VERSION ""

NS_ :

BS_:

BU_:

BO_ 2558394110 EAMC: 8 Vector__XXX
 SG_ EltrfdAssrMtrEnlCmmnd : 0|2@1+ (1,0) [0|3] "" Vector__XXX
 SG_ EltrfdAssrMtrPrntSpdCmmnd : 24|8@1+ (0.5,0) [0|125] "%" Vector__XXX
 SG_ EltrfdAssrMtrPwrHld : 2|2@1+ (1,0) [0|3] "" Vector__XXX
 SG_ EltrfdAssrMtrSpdCmmnd : 8|16@1+ (0.5,0) [0|32127.5] "rpm" Vector__XXX
 SG_ ElectrifiedAccessoryMotor1 : 32|1@1+ (1,0) [0|1] "" Vector__XXX
 SG_ ElectrifiedAccessoryMotor2 : 33|1@1+ (1,0) [0|1] "" Vector__XXX
 SG_ ElectrifiedAccessoryMotor3 : 34|1@1+ (1,0) [0|1] "" Vector__XXX
 SG_ ElectrifiedAccessoryMotor4 : 35|1@1+ (1,0) [0|1] "" Vector__XXX
 SG_ ElectrifiedAccessoryMotor5 : 36|1@1+ (1,0) [0|1] "" Vector__XXX
 SG_ ElectrifiedAccessoryMotor6 : 37|1@1+ (1,0) [0|1] "" Vector__XXX
 SG_ ElectrifiedAccessoryMotor7 : 38|1@1+ (1,0) [0|1] "" Vector__XXX
 SG_ ElectrifiedAccessoryMotor8 : 39|1@1+ (1,0) [0|1] "" Vector__XXX
 SG_ ElectrifiedAccessoryMotor9 : 40|1@1+ (1,0) [0|1] "" Vector__XXX
 SG_ ElectrifiedAccessoryMotor10 : 41|1@1+ (1,0) [0|1] "" Vector__XXX
 SG_ ElectrifiedAccessoryMotor11 : 42|1@1+ (1,0) [0|1] "" Vector__XXX
 SG_ ElectrifiedAccessoryMotor12 : 43|1@1+ (1,0) [0|1] "" Vector__XXX
 SG_ ElectrifiedAccessoryMotor13 : 44|1@1+ (1,0) [0|1] "" Vector__XXX
 SG_ ElectrifiedAccessoryMotor14 : 45|1@1+ (1,0) [0|1] "" Vector__XXX
 SG_ ElectrifiedAccessoryMotor15 : 46|1@1+ (1,0) [0|1] "" Vector__XXX

BO_ 2558459646 ESRRBR: 8 Vector__XXX
 SG_ RqstdEngnSpdAlrtnRtLmt : 0|16@1+ (1,0) [0|64255] "rpm/s" Vector__XXX
 SG_ RqstdEngnSpdDlrtnRtLmt : 16|16@1+ (1,0) [0|64255] "rpm/s" Vector__XXX

BO_ 2558525182 TSIC: 200 Vector__XXX
 SG_ NumberofTireSensors : 0|8@1+ (1,0) [0|250] "count" Vector__XXX
 SG_ TireLocation : 16|8@1+ (8,0) [0|0] "bit-mapped" Vector__XXX
 SG_ TireNumber : 8|8@1+ (1,0) [0|250] "count" Vector__XXX
 SG_ TireSensorIdentificationNumber : 24|8@1+ (1,0) [0|255] "ASCII" Vector__XXX

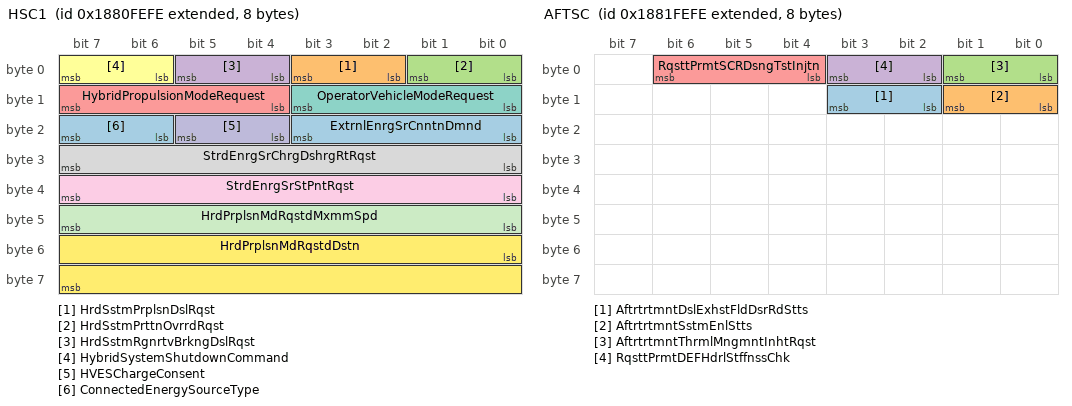
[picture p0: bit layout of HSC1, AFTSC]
BO_ 2558590718 HSC1: 8 Vector__XXX
 SG_ ExtrnlEnrgSrCnntnDmnd : 16|4@1+ (1,0) [0|15] "" Vector__XXX
 SG_ HrdSstmPrplsnDslRqst : 2|2@1+ (1,0) [0|3] "" Vector__XXX
 SG_ HrdSstmPrttnOvrrdRqst : 0|2@1+ (1,0) [0|3] "" Vector__XXX
 SG_ HrdSstmRgnrtvBrkngDslRqst : 4|2@1+ (1,0) [0|3] "" Vector__XXX
 SG_ HybridPropulsionModeRequest : 12|4@1+ (1,0) [0|15] "" Vector__XXX
 SG_ HybridSystemShutdownCommand : 6|2@1+ (1,0) [0|3] "" Vector__XXX
 SG_ OperatorVehicleModeRequest : 8|4@1+ (1,0) [0|15] "" Vector__XXX
 SG_ StrdEnrgSrChrgDshrgRtRqst : 24|8@1+ (0.4,0) [0|100] "%" Vector__XXX
 SG_ StrdEnrgSrStPntRqst : 32|8@1+ (0.4,0) [0|100] "%" Vector__XXX
 SG_ HVESChargeConsent : 20|2@1+ (1,0) [0|3] "" Vector__XXX
 SG_ HrdPrplsnMdRqstdMxmmSpd : 40|8@1+ (1,0) [0|250] "km/h" Vector__XXX
 SG_ HrdPrplsnMdRqstdDstn : 48|16@1+ (0.03125,0) [0|2007.96875] "km" Vector__XXX
 SG_ ConnectedEnergySourceType : 22|2@1+ (1,0) [0|3] "" Vector__XXX

BO_ 2558656254 AFTSC: 8 Vector__XXX
 SG_ AftrtrtmntDslExhstFldDsrRdStts : 10|2@1+ (1,0) [0|3] "" Vector__XXX
 SG_ AftrtrtmntSstmEnlStts : 8|2@1+ (1,0) [0|3] "" Vector__XXX
 SG_ AftrtrtmntThrmlMngmntInhtRqst : 0|2@1+ (1,0) [0|3] "" Vector__XXX
 SG_ RqsttPrmtDEFHdrlStffnssChk : 2|2@1+ (1,0) [0|3] "" Vector__XXX
 SG_ RqsttPrmtSCRDsngTstInjtn : 4|3@1+ (1,0) [0|7] "" Vector__XXX

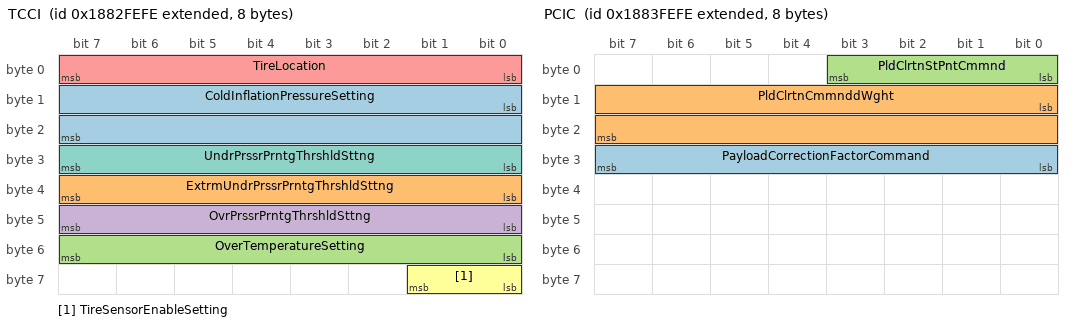
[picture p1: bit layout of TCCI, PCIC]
BO_ 2558721790 TCCI: 8 Vector__XXX
 SG_ ColdInflationPressureSetting : 8|16@1+ (1,0) [0|64255] "kPa" Vector__XXX
 SG_ ExtrmUndrPrssrPrntgThrshldSttng : 32|8@1+ (0.5,0) [0|125] "%" Vector__XXX
 SG_ OverTemperatureSetting : 48|8@1+ (1,-40) [-40|210] "degC" Vector__XXX
 SG_ OvrPrssrPrntgThrshldSttng : 40|8@1+ (0.5,0) [0|125] "%" Vector__XXX
 SG_ TireLocation : 0|8@1+ (8,0) [0|0] "bit-mapped" Vector__XXX
 SG_ TireSensorEnableSetting : 56|2@1+ (1,0) [0|3] "" Vector__XXX
 SG_ UndrPrssrPrntgThrshldSttng : 24|8@1+ (0.5,0) [0|125] "%" Vector__XXX

BO_ 2558787326 PCIC: 8 Vector__XXX
 SG_ PayloadCorrectionFactorCommand : 24|8@1+ (1,-125) [-125|125] "%" Vector__XXX
 SG_ PldClrtnCmmnddWght : 8|16@1+ (2,0) [0|128510] "kg" Vector__XXX
 SG_ PldClrtnStPntCmmnd : 0|4@1+ (1,0) [0|15] "" Vector__XXX

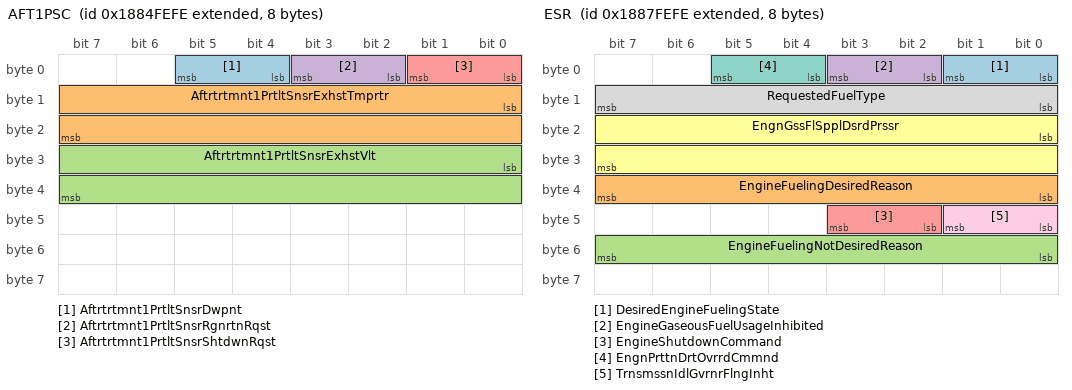
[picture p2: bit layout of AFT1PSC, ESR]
BO_ 2558852862 AFT1PSC: 8 Vector__XXX
 SG_ Aftrtrtmnt1PrtltSnsrDwpnt : 4|2@1+ (1,0) [0|3] "" Vector__XXX
 SG_ Aftrtrtmnt1PrtltSnsrExhstTmprtr : 8|16@1+ (0.03125,-273) [-273|1734.96875] "degC" Vector__XXX
 SG_ Aftrtrtmnt1PrtltSnsrExhstVlt : 24|16@1+ (0.00390625,0) [0|250.996] "km/h" Vector__XXX
 SG_ Aftrtrtmnt1PrtltSnsrRgnrtnRqst : 2|2@1+ (1,0) [0|3] "" Vector__XXX
 SG_ Aftrtrtmnt1PrtltSnsrShtdwnRqst : 0|2@1+ (1,0) [0|3] "" Vector__XXX

BO_ 2558918398 CM2: 8 Vector__XXX
 SG_ ActiveShiftConsoleRequest : 52|2@1+ (1,0) [0|3] "" Vector__XXX
 SG_ AftrtrtmntSstmEnlCmmnd : 50|2@1+ (1,0) [0|3] "" Vector__XXX
 SG_ AttttRtESpdAwdSwt : 30|2@1+ (1,0) [0|3] "" Vector__XXX
 SG_ ElvtdEngnSpdAllwdSwth : 28|2@1+ (1,0) [0|3] "" Vector__XXX
 SG_ EngineFan2RequestedPercentSpeed : 0|8@1+ (0.4,0) [0|100] "%" Vector__XXX
 SG_ EngineStopStartDisableCommand : 26|2@1+ (1,0) [0|3] "" Vector__XXX
 SG_ EngnIdlMngmntPndngEvntOvrrd : 54|2@1+ (1,0) [0|3] "" Vector__XXX
 SG_ HtExhngrDrsPrgFrSwth : 20|2@1+ (1,0) [0|3] "" Vector__XXX
 SG_ HtExhngrDrsPrgInhtSwth : 18|2@1+ (1,0) [0|3] "" Vector__XXX
 SG_ PerformanceBiasSelection : 8|8@1+ (0.4,0) [0|100] "%" Vector__XXX
 SG_ PrdtvCrsCntrlDtvtnRqst : 24|2@1+ (1,0) [0|3] "" Vector__XXX
 SG_ PrdtvCrsCntrlEnlSwth : 22|2@1+ (1,0) [0|3] "" Vector__XXX
 SG_ PrdtvCrsCntrlMxmmNgtvOffst : 40|8@1+ (0.125,-31.25) [-31.25|0] "km/h" Vector__XXX
 SG_ PrdtvCrsCntrlMxmmPstvOffst : 32|8@1+ (0.125,0) [0|31.25] "km/h" Vector__XXX
 SG_ SCROprtrIndmntOvrrdSwth : 16|2@1+ (1,0) [0|3] "" Vector__XXX
 SG_ TrnsmssnAtNtrlMnlRtrnEnlSwth : 48|2@1+ (1,0) [0|3] "" Vector__XXX
 SG_ VehicleHoodSwitch : 56|2@1+ (1,0) [0|3] "" Vector__XXX

BO_ 2558983934 SPOC: 8 Vector__XXX
 SG_ SwitchedPowerOutput10Command : 20|2@1+ (1,0) [0|3] "" Vector__XXX
 SG_ SwitchedPowerOutput11Command : 18|2@1+ (1,0) [0|3] "" Vector__XXX
 SG_ SwitchedPowerOutput12Command : 16|2@1+ (1,0) [0|3] "" Vector__XXX
 SG_ SwitchedPowerOutput13Command : 30|2@1+ (1,0) [0|3] "" Vector__XXX
 SG_ SwitchedPowerOutput14Command : 28|2@1+ (1,0) [0|3] "" Vector__XXX
 SG_ SwitchedPowerOutput15Command : 26|2@1+ (1,0) [0|3] "" Vector__XXX
 SG_ SwitchedPowerOutput16Command : 24|2@1+ (1,0) [0|3] "" Vector__XXX
 SG_ SwitchedPowerOutput17Command : 38|2@1+ (1,0) [0|3] "" Vector__XXX
 SG_ SwitchedPowerOutput18Command : 36|2@1+ (1,0) [0|3] "" Vector__XXX
 SG_ SwitchedPowerOutput19Command : 34|2@1+ (1,0) [0|3] "" Vector__XXX
 SG_ SwitchedPowerOutput1Command : 6|2@1+ (1,0) [0|3] "" Vector__XXX
 SG_ SwitchedPowerOutput20Command : 32|2@1+ (1,0) [0|3] "" Vector__XXX
 SG_ SwitchedPowerOutput21Command : 46|2@1+ (1,0) [0|3] "" Vector__XXX
 SG_ SwitchedPowerOutput22Command : 44|2@1+ (1,0) [0|3] "" Vector__XXX
 SG_ SwitchedPowerOutput23Command : 42|2@1+ (1,0) [0|3] "" Vector__XXX
 SG_ SwitchedPowerOutput24Command : 40|2@1+ (1,0) [0|3] "" Vector__XXX
 SG_ SwitchedPowerOutput25Command : 54|2@1+ (1,0) [0|3] "" Vector__XXX
 SG_ SwitchedPowerOutput26Command : 52|2@1+ (1,0) [0|3] "" Vector__XXX
 SG_ SwitchedPowerOutput27Command : 50|2@1+ (1,0) [0|3] "" Vector__XXX
 SG_ SwitchedPowerOutput28Command : 48|2@1+ (1,0) [0|3] "" Vector__XXX
 SG_ SwitchedPowerOutput29Command : 62|2@1+ (1,0) [0|3] "" Vector__XXX
 SG_ SwitchedPowerOutput2Command : 4|2@1+ (1,0) [0|3] "" Vector__XXX
 SG_ SwitchedPowerOutput30Command : 60|2@1+ (1,0) [0|3] "" Vector__XXX
 SG_ SwitchedPowerOutput31Command : 58|2@1+ (1,0) [0|3] "" Vector__XXX
 SG_ SwitchedPowerOutput32Command : 56|2@1+ (1,0) [0|3] "" Vector__XXX
 SG_ SwitchedPowerOutput3Command : 2|2@1+ (1,0) [0|3] "" Vector__XXX
 SG_ SwitchedPowerOutput4Command : 0|2@1+ (1,0) [0|3] "" Vector__XXX
 SG_ SwitchedPowerOutput5Command : 14|2@1+ (1,0) [0|3] "" Vector__XXX
 SG_ SwitchedPowerOutput6Command : 12|2@1+ (1,0) [0|3] "" Vector__XXX
 SG_ SwitchedPowerOutput7Command : 10|2@1+ (1,0) [0|3] "" Vector__XXX
 SG_ SwitchedPowerOutput8Command : 8|2@1+ (1,0) [0|3] "" Vector__XXX
 SG_ SwitchedPowerOutput9Command : 22|2@1+ (1,0) [0|3] "" Vector__XXX

BO_ 2559049470 ESR: 8 Vector__XXX
 SG_ DesiredEngineFuelingState : 0|2@1+ (1,0) [0|3] "" Vector__XXX
 SG_ EngineFuelingDesiredReason : 32|8@1+ (1,0) [0|255] "" Vector__XXX
 SG_ EngineFuelingNotDesiredReason : 48|8@1+ (1,0) [0|255] "" Vector__XXX
 SG_ EngineGaseousFuelUsageInhibited : 2|2@1+ (1,0) [0|3] "" Vector__XXX
 SG_ EngineShutdownCommand : 42|2@1+ (1,0) [0|3] "" Vector__XXX
 SG_ EngnGssFlSpplDsrdPrssr : 16|16@1+ (0.5,0) [0|32127.5] "kPa" Vector__XXX
 SG_ EngnPrttnDrtOvrrdCmmnd : 4|2@1+ (1,0) [0|3] "" Vector__XXX
 SG_ RequestedFuelType : 8|8@1+ (1,0) [0|255] "" Vector__XXX
 SG_ TrnsmssnIdlGvrnrFlngInht : 40|2@1+ (1,0) [0|3] "" Vector__XXX

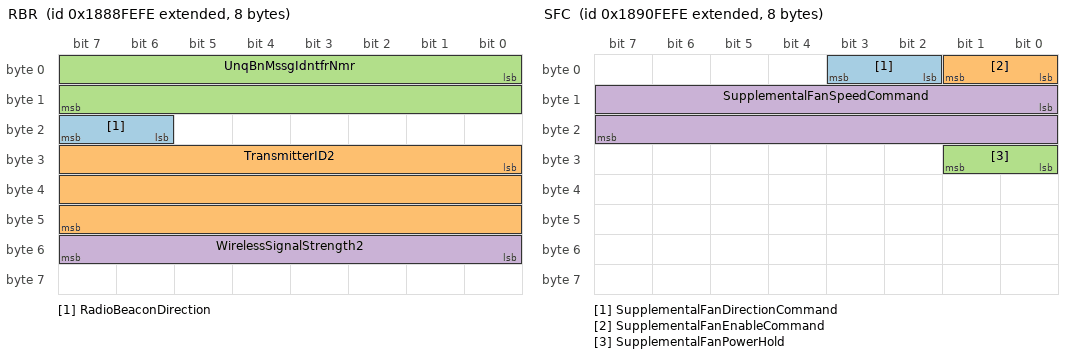
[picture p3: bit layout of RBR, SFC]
BO_ 2559115006 RBR: 8 Vector__XXX
 SG_ RadioBeaconDirection : 22|2@1+ (1,0) [0|3] "" Vector__XXX
 SG_ TransmitterID2 : 24|24@1+ (1,0) [0|16449635] "ID" Vector__XXX
 SG_ UnqBnMssgIdntfrNmr : 0|16@1+ (1,0) [0|64255] "count" Vector__XXX
 SG_ WirelessSignalStrength2 : 48|8@1+ (0.5,-125) [-125|0] "dBm" Vector__XXX

BO_ 2559573758 ECC: 8 Vector__XXX
 SG_ CtLvEPttStdwOvdCd : 0|2@1+ (1,0) [0|3] "" Vector__XXX

BO_ 2559639294 SFC: 8 Vector__XXX
 SG_ SupplementalFanDirectionCommand : 2|2@1+ (1,0) [0|3] "" Vector__XXX
 SG_ SupplementalFanEnableCommand : 0|2@1+ (1,0) [0|3] "" Vector__XXX
 SG_ SupplementalFanPowerHold : 24|2@1+ (1,0) [0|3] "" Vector__XXX
 SG_ SupplementalFanSpeedCommand : 8|16@1+ (0.5,0) [0|32127.5] "rpm" Vector__XXX

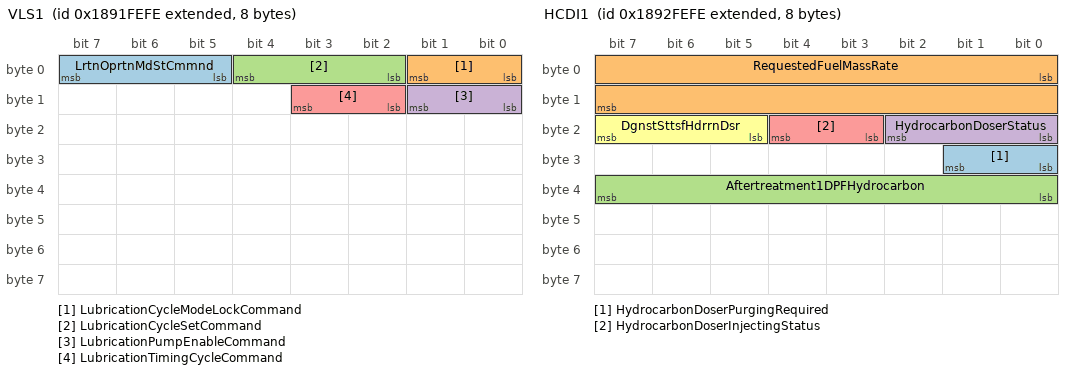
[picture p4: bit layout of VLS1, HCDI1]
BO_ 2559704830 VLS1: 8 Vector__XXX
 SG_ LrtnOprtnMdStCmmnd : 5|3@1+ (1,0) [0|7] "" Vector__XXX
 SG_ LubricationCycleModeLockCommand : 0|2@1+ (1,0) [0|3] "" Vector__XXX
 SG_ LubricationCycleSetCommand : 2|3@1+ (1,0) [0|7] "" Vector__XXX
 SG_ LubricationPumpEnableCommand : 8|2@1+ (1,0) [0|3] "" Vector__XXX
 SG_ LubricationTimingCycleCommand : 10|2@1+ (1,0) [0|3] "" Vector__XXX

BO_ 2559770366 HCDI1: 8 Vector__XXX
 SG_ HydrocarbonDoserPurgingRequired : 24|2@1+ (1,0) [0|3] "" Vector__XXX
 SG_ RequestedFuelMassRate : 0|16@1+ (0.05,0) [0|3212.75] "g/min" Vector__XXX
 SG_ Aftertreatment1DPFHydrocarbon : 32|8@1+ (0.5,0) [0|125] "%" Vector__XXX
 SG_ HydrocarbonDoserStatus : 16|3@1+ (1,0) [0|7] "" Vector__XXX
 SG_ HydrocarbonDoserInjectingStatus : 19|2@1+ (1,0) [0|3] "" Vector__XXX
 SG_ DgnstSttsfHdrrnDsr : 21|3@1+ (1,0) [0|7] "" Vector__XXX

BO_ 2559901438 AT1DPFSSC: 8 Vector__XXX
 SG_ Atttt1DsPttFtStMCtOst : 0|16@1+ (0.0025,0) [0|160.6375] "%" Vector__XXX
 SG_ Atttt1DsPttFtStStddDvtCtOst : 16|16@1+ (0.0025,0) [0|160.6375] "%" Vector__XXX

BO_ 2559966974 AT2DPFSSC: 8 Vector__XXX
 SG_ Atttt2DsPttFtStMCtOst : 0|16@1+ (0.0025,0) [0|160.6375] "%" Vector__XXX
 SG_ Atttt2DsPttFtStStddDvtCtOst : 16|16@1+ (0.0025,0) [0|160.6375] "%" Vector__XXX

BO_ 2560032510 LVDSOM: 8 Vector__XXX
 SG_ LwVltgDsnntDsrdOprtngMd : 0|4@1+ (1,0) [0|15] "" Vector__XXX

BO_ 2560098046 NCS: 8 Vector__XXX
 SG_ CabNoiseControlStatus : 0|2@1+ (1,0) [0|3] "" Vector__XXX
 SG_ CabNoiseControlTuningStatus : 2|4@1+ (1,0) [0|15] "" Vector__XXX

BO_ 2560163582 NC1: 8 Vector__XXX
 SG_ CabNoiseControlCommand : 0|2@1+ (1,0) [0|3] "" Vector__XXX
 SG_ CabNoiseControlTuningCommand : 2|3@1+ (1,0) [0|7] "" Vector__XXX

BO_ 2560360190 PMI: 8 Vector__XXX
 SG_ DataDictionaryManufacturerCode : 0|11@1+ (1,0) [0|2047] "" Vector__XXX
 SG_ DataDictionaryMethod : 11|21@1+ (1,0) [0|2097151] "" Vector__XXX

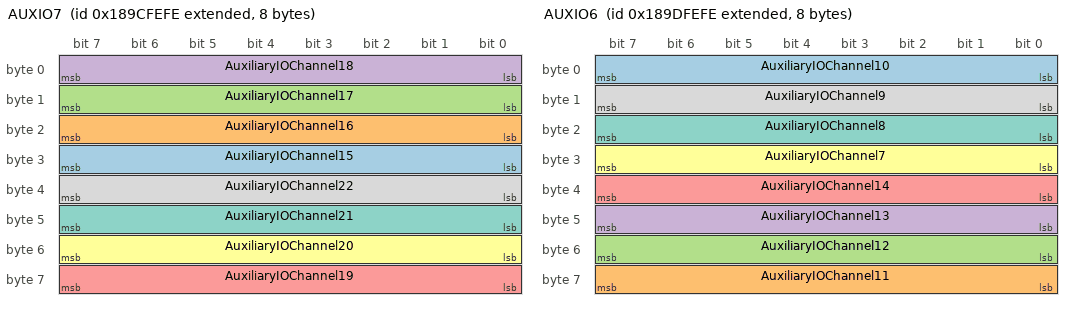
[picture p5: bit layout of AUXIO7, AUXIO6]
BO_ 2560425726 AUXIO7: 8 Vector__XXX
 SG_ AuxiliaryIOChannel15 : 24|8@1+ (1,0) [0|250] "count" Vector__XXX
 SG_ AuxiliaryIOChannel16 : 16|8@1+ (1,0) [0|250] "count" Vector__XXX
 SG_ AuxiliaryIOChannel17 : 8|8@1+ (1,0) [0|250] "count" Vector__XXX
 SG_ AuxiliaryIOChannel18 : 0|8@1+ (1,0) [0|250] "count" Vector__XXX
 SG_ AuxiliaryIOChannel19 : 56|8@1+ (1,0) [0|250] "count" Vector__XXX
 SG_ AuxiliaryIOChannel20 : 48|8@1+ (1,0) [0|250] "count" Vector__XXX
 SG_ AuxiliaryIOChannel21 : 40|8@1+ (1,0) [0|250] "count" Vector__XXX
 SG_ AuxiliaryIOChannel22 : 32|8@1+ (1,0) [0|250] "count" Vector__XXX

BO_ 2560491262 AUXIO6: 8 Vector__XXX
 SG_ AuxiliaryIOChannel10 : 0|8@1+ (1,0) [0|250] "count" Vector__XXX
 SG_ AuxiliaryIOChannel11 : 56|8@1+ (1,0) [0|250] "count" Vector__XXX
 SG_ AuxiliaryIOChannel12 : 48|8@1+ (1,0) [0|250] "count" Vector__XXX
 SG_ AuxiliaryIOChannel13 : 40|8@1+ (1,0) [0|250] "count" Vector__XXX
 SG_ AuxiliaryIOChannel14 : 32|8@1+ (1,0) [0|250] "count" Vector__XXX
 SG_ AuxiliaryIOChannel7 : 24|8@1+ (1,0) [0|250] "count" Vector__XXX
 SG_ AuxiliaryIOChannel8 : 16|8@1+ (1,0) [0|250] "count" Vector__XXX
 SG_ AuxiliaryIOChannel9 : 8|8@1+ (1,0) [0|250] "count" Vector__XXX

BO_ 2561015550 AUXIO4: 8 Vector__XXX
 SG_ AuxiliaryIO100 : 32|2@1+ (1,0) [0|3] "" Vector__XXX
 SG_ AuxiliaryIO101 : 46|2@1+ (1,0) [0|3] "" Vector__XXX
 SG_ AuxiliaryIO102 : 44|2@1+ (1,0) [0|3] "" Vector__XXX
 SG_ AuxiliaryIO103 : 42|2@1+ (1,0) [0|3] "" Vector__XXX
 SG_ AuxiliaryIO104 : 40|2@1+ (1,0) [0|3] "" Vector__XXX
 SG_ AuxiliaryIO105 : 54|2@1+ (1,0) [0|3] "" Vector__XXX
 SG_ AuxiliaryIO106 : 52|2@1+ (1,0) [0|3] "" Vector__XXX
 SG_ AuxiliaryIO107 : 50|2@1+ (1,0) [0|3] "" Vector__XXX
 SG_ AuxiliaryIO108 : 48|2@1+ (1,0) [0|3] "" Vector__XXX
 SG_ AuxiliaryIO109 : 62|2@1+ (1,0) [0|3] "" Vector__XXX
 SG_ AuxiliaryIO110 : 60|2@1+ (1,0) [0|3] "" Vector__XXX
 SG_ AuxiliaryIO111 : 58|2@1+ (1,0) [0|3] "" Vector__XXX
 SG_ AuxiliaryIO112 : 56|2@1+ (1,0) [0|3] "" Vector__XXX
 SG_ AuxiliaryIO81 : 6|2@1+ (1,0) [0|3] "" Vector__XXX
 SG_ AuxiliaryIO82 : 4|2@1+ (1,0) [0|3] "" Vector__XXX
 SG_ AuxiliaryIO83 : 2|2@1+ (1,0) [0|3] "" Vector__XXX
 SG_ AuxiliaryIO84 : 0|2@1+ (1,0) [0|3] "" Vector__XXX
 SG_ AuxiliaryIO85 : 14|2@1+ (1,0) [0|3] "" Vector__XXX
 SG_ AuxiliaryIO86 : 12|2@1+ (1,0) [0|3] "" Vector__XXX
 SG_ AuxiliaryIO87 : 10|2@1+ (1,0) [0|3] "" Vector__XXX
 SG_ AuxiliaryIO88 : 8|2@1+ (1,0) [0|3] "" Vector__XXX
 SG_ AuxiliaryIO89 : 22|2@1+ (1,0) [0|3] "" Vector__XXX
 SG_ AuxiliaryIO90 : 20|2@1+ (1,0) [0|3] "" Vector__XXX
 SG_ AuxiliaryIO91 : 18|2@1+ (1,0) [0|3] "" Vector__XXX
 SG_ AuxiliaryIO92 : 16|2@1+ (1,0) [0|3] "" Vector__XXX
 SG_ AuxiliaryIO93 : 30|2@1+ (1,0) [0|3] "" Vector__XXX
 SG_ AuxiliaryIO94 : 28|2@1+ (1,0) [0|3] "" Vector__XXX
 SG_ AuxiliaryIO95 : 26|2@1+ (1,0) [0|3] "" Vector__XXX
 SG_ AuxiliaryIO96 : 24|2@1+ (1,0) [0|3] "" Vector__XXX
 SG_ AuxiliaryIO97 : 38|2@1+ (1,0) [0|3] "" Vector__XXX
 SG_ AuxiliaryIO98 : 36|2@1+ (1,0) [0|3] "" Vector__XXX
 SG_ AuxiliaryIO99 : 34|2@1+ (1,0) [0|3] "" Vector__XXX

BO_ 2561081086 AUXIO3: 8 Vector__XXX
 SG_ AuxiliaryIO49 : 6|2@1+ (1,0) [0|3] "" Vector__XXX
 SG_ AuxiliaryIO50 : 4|2@1+ (1,0) [0|3] "" Vector__XXX
 SG_ AuxiliaryIO51 : 2|2@1+ (1,0) [0|3] "" Vector__XXX
 SG_ AuxiliaryIO52 : 0|2@1+ (1,0) [0|3] "" Vector__XXX
 SG_ AuxiliaryIO53 : 14|2@1+ (1,0) [0|3] "" Vector__XXX
 SG_ AuxiliaryIO54 : 12|2@1+ (1,0) [0|3] "" Vector__XXX
 SG_ AuxiliaryIO55 : 10|2@1+ (1,0) [0|3] "" Vector__XXX
 SG_ AuxiliaryIO56 : 8|2@1+ (1,0) [0|3] "" Vector__XXX
 SG_ AuxiliaryIO57 : 22|2@1+ (1,0) [0|3] "" Vector__XXX
 SG_ AuxiliaryIO58 : 20|2@1+ (1,0) [0|3] "" Vector__XXX
 SG_ AuxiliaryIO59 : 18|2@1+ (1,0) [0|3] "" Vector__XXX
 SG_ AuxiliaryIO60 : 16|2@1+ (1,0) [0|3] "" Vector__XXX
 SG_ AuxiliaryIO61 : 30|2@1+ (1,0) [0|3] "" Vector__XXX
 SG_ AuxiliaryIO62 : 28|2@1+ (1,0) [0|3] "" Vector__XXX
 SG_ AuxiliaryIO63 : 26|2@1+ (1,0) [0|3] "" Vector__XXX
 SG_ AuxiliaryIO64 : 24|2@1+ (1,0) [0|3] "" Vector__XXX
 SG_ AuxiliaryIO65 : 38|2@1+ (1,0) [0|3] "" Vector__XXX
 SG_ AuxiliaryIO66 : 36|2@1+ (1,0) [0|3] "" Vector__XXX
 SG_ AuxiliaryIO67 : 34|2@1+ (1,0) [0|3] "" Vector__XXX
 SG_ AuxiliaryIO68 : 32|2@1+ (1,0) [0|3] "" Vector__XXX
 SG_ AuxiliaryIO69 : 46|2@1+ (1,0) [0|3] "" Vector__XXX
 SG_ AuxiliaryIO70 : 44|2@1+ (1,0) [0|3] "" Vector__XXX
 SG_ AuxiliaryIO71 : 42|2@1+ (1,0) [0|3] "" Vector__XXX
 SG_ AuxiliaryIO72 : 40|2@1+ (1,0) [0|3] "" Vector__XXX
 SG_ AuxiliaryIO73 : 54|2@1+ (1,0) [0|3] "" Vector__XXX
 SG_ AuxiliaryIO74 : 52|2@1+ (1,0) [0|3] "" Vector__XXX
 SG_ AuxiliaryIO75 : 50|2@1+ (1,0) [0|3] "" Vector__XXX
 SG_ AuxiliaryIO76 : 48|2@1+ (1,0) [0|3] "" Vector__XXX
 SG_ AuxiliaryIO77 : 62|2@1+ (1,0) [0|3] "" Vector__XXX
 SG_ AuxiliaryIO78 : 60|2@1+ (1,0) [0|3] "" Vector__XXX
 SG_ AuxiliaryIO79 : 58|2@1+ (1,0) [0|3] "" Vector__XXX
 SG_ AuxiliaryIO80 : 56|2@1+ (1,0) [0|3] "" Vector__XXX

BO_ 2561146622 AUXIO2: 8 Vector__XXX
 SG_ AuxiliaryIO17 : 6|2@1+ (1,0) [0|3] "" Vector__XXX
 SG_ AuxiliaryIO18 : 4|2@1+ (1,0) [0|3] "" Vector__XXX
 SG_ AuxiliaryIO19 : 2|2@1+ (1,0) [0|3] "" Vector__XXX
 SG_ AuxiliaryIO20 : 0|2@1+ (1,0) [0|3] "" Vector__XXX
 SG_ AuxiliaryIO21 : 14|2@1+ (1,0) [0|3] "" Vector__XXX
 SG_ AuxiliaryIO22 : 12|2@1+ (1,0) [0|3] "" Vector__XXX
 SG_ AuxiliaryIO23 : 10|2@1+ (1,0) [0|3] "" Vector__XXX
 SG_ AuxiliaryIO24 : 8|2@1+ (1,0) [0|3] "" Vector__XXX
 SG_ AuxiliaryIO25 : 22|2@1+ (1,0) [0|3] "" Vector__XXX
 SG_ AuxiliaryIO26 : 20|2@1+ (1,0) [0|3] "" Vector__XXX
 SG_ AuxiliaryIO27 : 18|2@1+ (1,0) [0|3] "" Vector__XXX
 SG_ AuxiliaryIO28 : 16|2@1+ (1,0) [0|3] "" Vector__XXX
 SG_ AuxiliaryIO29 : 30|2@1+ (1,0) [0|3] "" Vector__XXX
 SG_ AuxiliaryIO30 : 28|2@1+ (1,0) [0|3] "" Vector__XXX
 SG_ AuxiliaryIO31 : 26|2@1+ (1,0) [0|3] "" Vector__XXX
 SG_ AuxiliaryIO32 : 24|2@1+ (1,0) [0|3] "" Vector__XXX
 SG_ AuxiliaryIO33 : 38|2@1+ (1,0) [0|3] "" Vector__XXX
 SG_ AuxiliaryIO34 : 36|2@1+ (1,0) [0|3] "" Vector__XXX
 SG_ AuxiliaryIO35 : 34|2@1+ (1,0) [0|3] "" Vector__XXX
 SG_ AuxiliaryIO36 : 32|2@1+ (1,0) [0|3] "" Vector__XXX
 SG_ AuxiliaryIO37 : 46|2@1+ (1,0) [0|3] "" Vector__XXX
 SG_ AuxiliaryIO38 : 44|2@1+ (1,0) [0|3] "" Vector__XXX
 SG_ AuxiliaryIO39 : 42|2@1+ (1,0) [0|3] "" Vector__XXX
 SG_ AuxiliaryIO40 : 40|2@1+ (1,0) [0|3] "" Vector__XXX
 SG_ AuxiliaryIO41 : 54|2@1+ (1,0) [0|3] "" Vector__XXX
 SG_ AuxiliaryIO42 : 52|2@1+ (1,0) [0|3] "" Vector__XXX
 SG_ AuxiliaryIO43 : 50|2@1+ (1,0) [0|3] "" Vector__XXX
 SG_ AuxiliaryIO44 : 48|2@1+ (1,0) [0|3] "" Vector__XXX
 SG_ AuxiliaryIO45 : 62|2@1+ (1,0) [0|3] "" Vector__XXX
 SG_ AuxiliaryIO46 : 60|2@1+ (1,0) [0|3] "" Vector__XXX
 SG_ AuxiliaryIO47 : 58|2@1+ (1,0) [0|3] "" Vector__XXX
 SG_ AuxiliaryIO48 : 56|2@1+ (1,0) [0|3] "" Vector__XXX

BO_ 2561212158 DISP1: 8 Vector__XXX
 SG_ TextDisplayIndex : 16|8@1+ (1,0) [0|250] "count" Vector__XXX
 SG_ TextDisplayInstructions : 0|4@1+ (1,0) [0|15] "" Vector__XXX

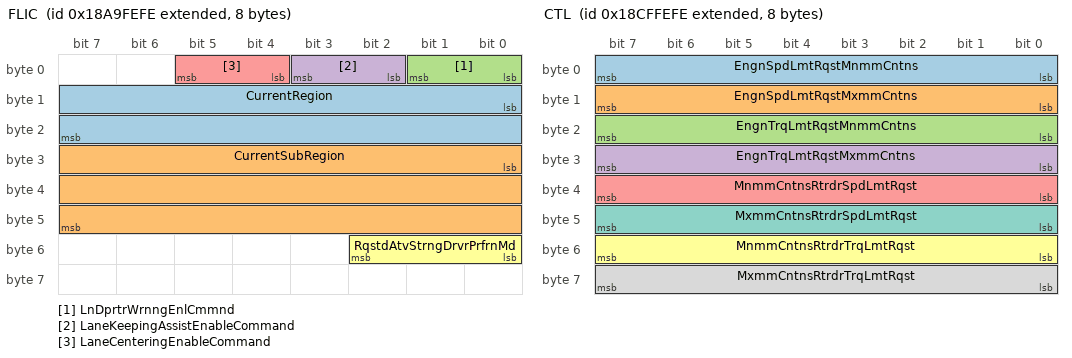
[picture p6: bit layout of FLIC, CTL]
BO_ 2561277694 FLIC: 8 Vector__XXX
 SG_ CurrentRegion : 8|16@1+ (1,0) [0|255] "ASCII" Vector__XXX
 SG_ CurrentSubRegion : 24|24@1+ (1,0) [0|255] "ASCII" Vector__XXX
 SG_ LnDprtrWrnngEnlCmmnd : 0|2@1+ (1,0) [0|3] "" Vector__XXX
 SG_ LaneKeepingAssistEnableCommand : 2|2@1+ (1,0) [0|3] "" Vector__XXX
 SG_ LaneCenteringEnableCommand : 4|2@1+ (1,0) [0|3] "" Vector__XXX
 SG_ RqstdAtvStrngDrvrPrfrnMd : 48|3@1+ (1,0) [0|7] "" Vector__XXX

BO_ 2561605374 TPRS: 8 Vector__XXX
 SG_ ReferenceTirePressureSetting : 8|8@1+ (8,0) [0|2000] "kPa" Vector__XXX
 SG_ TireLocation : 0|8@1+ (1,0) [0|255] "" Vector__XXX

BO_ 2563768062 CTL: 8 Vector__XXX
 SG_ EngnSpdLmtRqstMnmmCntns : 0|8@1+ (32,0) [0|8000] "rpm" Vector__XXX
 SG_ EngnSpdLmtRqstMxmmCntns : 8|8@1+ (32,0) [0|8000] "rpm" Vector__XXX
 SG_ EngnTrqLmtRqstMnmmCntns : 16|8@1+ (1,-125) [-125|125] "%" Vector__XXX
 SG_ EngnTrqLmtRqstMxmmCntns : 24|8@1+ (1,-125) [-125|125] "%" Vector__XXX
 SG_ MnmmCntnsRtrdrSpdLmtRqst : 32|8@1+ (32,0) [0|8000] "rpm" Vector__XXX
 SG_ MnmmCntnsRtrdrTrqLmtRqst : 48|8@1+ (1,-125) [-125|125] "%" Vector__XXX
 SG_ MxmmCntnsRtrdrSpdLmtRqst : 40|8@1+ (32,0) [0|8000] "rpm" Vector__XXX
 SG_ MxmmCntnsRtrdrTrqLmtRqst : 56|8@1+ (1,-125) [-125|125] "%" Vector__XXX

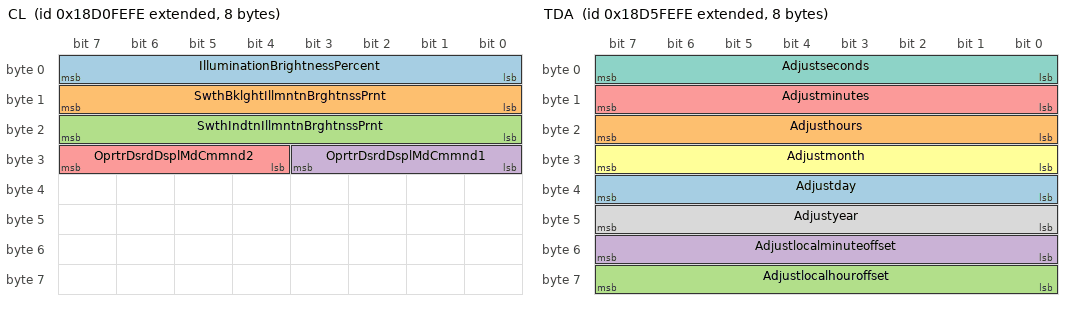
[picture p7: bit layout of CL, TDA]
BO_ 2563833598 CL: 8 Vector__XXX
 SG_ IlluminationBrightnessPercent : 0|8@1+ (0.4,0) [0|100] "%" Vector__XXX
 SG_ SwthBklghtIllmntnBrghtnssPrnt : 8|8@1+ (0.4,0) [0|100] "%" Vector__XXX
 SG_ SwthIndtnIllmntnBrghtnssPrnt : 16|8@1+ (0.4,0) [0|100] "%" Vector__XXX
 SG_ OprtrDsrdDsplMdCmmnd1 : 24|4@1+ (1,0) [0|15] "" Vector__XXX
 SG_ OprtrDsrdDsplMdCmmnd2 : 28|4@1+ (1,0) [0|15] "" Vector__XXX

BO_ 2564161278 TDA: 8 Vector__XXX
 SG_ Adjustday : 32|8@1+ (0.25,0) [0|62.5] "days" Vector__XXX
 SG_ Adjusthours : 16|8@1+ (1,0) [0|250] "h" Vector__XXX
 SG_ Adjustlocalhouroffset : 56|8@1+ (1,-125) [-125|125] "h" Vector__XXX
 SG_ Adjustlocalminuteoffset : 48|8@1+ (1,-125) [-125|125] "min" Vector__XXX
 SG_ Adjustminutes : 8|8@1+ (1,0) [0|250] "min" Vector__XXX
 SG_ Adjustmonth : 24|8@1+ (1,0) [0|250] "months" Vector__XXX
 SG_ Adjustseconds : 0|8@1+ (0.25,0) [0|62.5] "s" Vector__XXX
 SG_ Adjustyear : 40|8@1+ (1,1985) [1985|2235] "years" Vector__XXX

BO_ 2564882174 CM1: 8 Vector__XXX
 SG_ AftrtrtmntRgnrtnFrSwth : 42|2@1+ (1,0) [0|3] "" Vector__XXX
 SG_ AftrtrtmntRgnrtnInhtSwth : 40|2@1+ (1,0) [0|3] "" Vector__XXX
 SG_ AtmtGrShftngEnlSwth : 44|2@1+ (1,0) [0|3] "" Vector__XXX
 SG_ AuxiliaryHeaterModeRequest : 48|4@1+ (1,0) [0|15] "" Vector__XXX
 SG_ AxlrHtrClntPmpRqst : 24|2@1+ (1,0) [0|3] "" Vector__XXX
 SG_ BatteryMainSwitchHoldRequest : 26|2@1+ (1,0) [0|3] "" Vector__XXX
 SG_ CabInteriorTemperatureCommand : 8|16@1+ (0.03125,-273) [-273|1734.96875] "degC" Vector__XXX
 SG_ EngineFan1RequestedPercentSpeed : 0|8@1+ (0.4,0) [0|100] "%" Vector__XXX
 SG_ EngnAtmtStrtEnlSwth : 46|2@1+ (1,0) [0|3] "" Vector__XXX
 SG_ OperatorSeatDirectionSwitch : 28|2@1+ (1,0) [0|3] "" Vector__XXX
 SG_ ParkBrakeCommand : 32|2@1+ (1,0) [0|3] "" Vector__XXX
 SG_ RequestCabZoneHeating : 54|2@1+ (1,0) [0|3] "" Vector__XXX
 SG_ RequestEngineZoneHeating : 52|2@1+ (1,0) [0|3] "" Vector__XXX
 SG_ SeatBeltSwitch : 30|2@1+ (1,0) [0|3] "" Vector__XXX
 SG_ SltdMxmmVhlSpdLmt : 56|8@1+ (1,0) [0|250] "count" Vector__XXX
 SG_ VhlLmtngSpdGvrnrDrmntSwth : 34|2@1+ (1,0) [0|3] "" Vector__XXX
 SG_ VhlLmtngSpdGvrnrEnlSwth : 38|2@1+ (1,0) [0|3] "" Vector__XXX
 SG_ VhlLmtngSpdGvrnrInrmntSwth : 36|2@1+ (1,0) [0|3] "" Vector__XXX

BO_ 2565865982 EBC1: 8 Vector__XXX
 SG_ ABSEBSAmrWrnngSgnlPwrdVhl : 44|2@1+ (1,0) [0|3] "" Vector__XXX
 SG_ ABSFullyOperational : 40|2@1+ (1,0) [0|3] "" Vector__XXX
 SG_ ABSOffroadSwitch : 16|2@1+ (1,0) [0|3] "" Vector__XXX
 SG_ AcceleratorInterlockSwitch : 24|2@1+ (1,0) [0|3] "" Vector__XXX
 SG_ AntiLockBrakingABSActive : 4|2@1+ (1,0) [0|3] "" Vector__XXX
 SG_ ASRBrakeControlActive : 2|2@1+ (1,0) [0|3] "" Vector__XXX
 SG_ ASREngineControlActive : 0|2@1+ (1,0) [0|3] "" Vector__XXX
 SG_ ASRHillHolderSwitch : 20|2@1+ (1,0) [0|3] "" Vector__XXX
 SG_ ASROffroadSwitch : 18|2@1+ (1,0) [0|3] "" Vector__XXX
 SG_ ATCASRInformationSignal : 46|2@1+ (1,0) [0|3] "" Vector__XXX
 SG_ BrakePedalPosition : 8|8@1+ (0.4,0) [0|100] "%" Vector__XXX
 SG_ EBSBrakeSwitch : 6|2@1+ (1,0) [0|3] "" Vector__XXX
 SG_ EBSRedWarningSignal : 42|2@1+ (1,0) [0|3] "" Vector__XXX
 SG_ EngineAuxiliaryShutdownSwitch : 28|2@1+ (1,0) [0|3] "" Vector__XXX
 SG_ EngineDerateSwitch : 26|2@1+ (1,0) [0|3] "" Vector__XXX
 SG_ EngineRetarderSelection : 32|8@1+ (0.4,0) [0|100] "%" Vector__XXX
 SG_ Haltbrakeswitch : 58|2@1+ (1,0) [0|3] "" Vector__XXX
 SG_ RailroadModeSwitch : 56|2@1+ (1,0) [0|3] "" Vector__XXX
 SG_ RemoteAcceleratorEnableSwitch : 30|2@1+ (1,0) [0|3] "" Vector__XXX
 SG_ SrAddrssfCntrllngDvfrBrkCntrl : 48|8@1+ (1,0) [0|255] "SA" Vector__XXX
 SG_ TractionControlOverrideSwitch : 22|2@1+ (1,0) [0|3] "" Vector__XXX
 SG_ TrailerABSStatus : 60|2@1+ (1,0) [0|3] "" Vector__XXX
 SG_ TrtrMntdTrlrABSWrnngSgnl : 62|2@1+ (1,0) [0|3] "" Vector__XXX

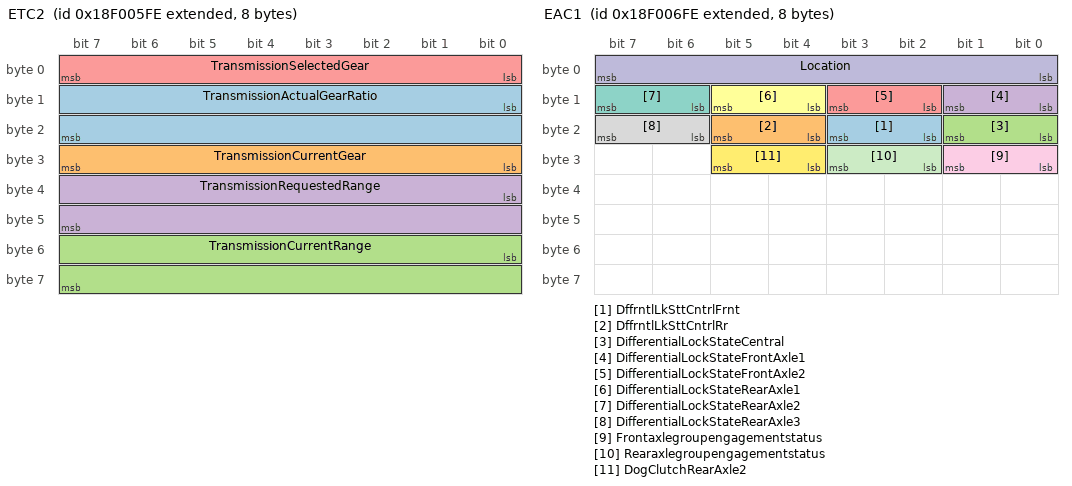
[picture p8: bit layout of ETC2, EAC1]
BO_ 2565867006 ETC2: 8 Vector__XXX
 SG_ TransmissionActualGearRatio : 8|16@1+ (0.001,0) [0|64.255] "Ratio" Vector__XXX
 SG_ TransmissionCurrentGear : 24|8@1+ (1,-125) [-125|125] "gear value" Vector__XXX
 SG_ TransmissionCurrentRange : 48|16@1+ (1,0) [0|255] "ASCII" Vector__XXX
 SG_ TransmissionRequestedRange : 32|16@1+ (1,0) [0|255] "ASCII" Vector__XXX
 SG_ TransmissionSelectedGear : 0|8@1+ (1,-125) [-125|125] "gear value" Vector__XXX

BO_ 2565867262 EAC1: 8 Vector__XXX
 SG_ DffrntlLkSttCntrlFrnt : 18|2@1+ (1,0) [0|3] "" Vector__XXX
 SG_ DffrntlLkSttCntrlRr : 20|2@1+ (1,0) [0|3] "" Vector__XXX
 SG_ DifferentialLockStateCentral : 16|2@1+ (1,0) [0|3] "" Vector__XXX
 SG_ DifferentialLockStateFrontAxle1 : 8|2@1+ (1,0) [0|3] "" Vector__XXX
 SG_ DifferentialLockStateFrontAxle2 : 10|2@1+ (1,0) [0|3] "" Vector__XXX
 SG_ DifferentialLockStateRearAxle1 : 12|2@1+ (1,0) [0|3] "" Vector__XXX
 SG_ DifferentialLockStateRearAxle2 : 14|2@1+ (1,0) [0|3] "" Vector__XXX
 SG_ DifferentialLockStateRearAxle3 : 22|2@1+ (1,0) [0|3] "" Vector__XXX
 SG_ Frontaxlegroupengagementstatus : 24|2@1+ (1,0) [0|3] "" Vector__XXX
 SG_ Location : 0|8@1+ (1,0) [0|255] "" Vector__XXX
 SG_ Rearaxlegroupengagementstatus : 26|2@1+ (1,0) [0|3] "" Vector__XXX
 SG_ DogClutchRearAxle2 : 28|2@1+ (1,0) [0|3] "" Vector__XXX

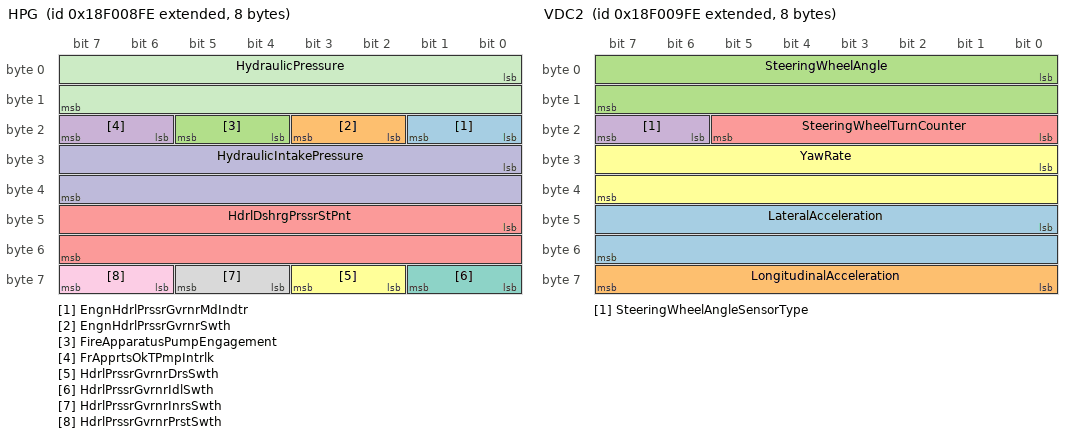
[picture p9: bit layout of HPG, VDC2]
BO_ 2565867774 HPG: 8 Vector__XXX
 SG_ EngnHdrlPrssrGvrnrMdIndtr : 16|2@1+ (1,0) [0|3] "" Vector__XXX
 SG_ EngnHdrlPrssrGvrnrSwth : 18|2@1+ (1,0) [0|3] "" Vector__XXX
 SG_ FireApparatusPumpEngagement : 20|2@1+ (1,0) [0|3] "" Vector__XXX
 SG_ FrApprtsOkTPmpIntrlk : 22|2@1+ (1,0) [0|3] "" Vector__XXX
 SG_ HdrlDshrgPrssrStPnt : 40|16@1+ (2,0) [0|128510] "kPa" Vector__XXX
 SG_ HdrlPrssrGvrnrDrsSwth : 58|2@1+ (1,0) [0|3] "" Vector__XXX
 SG_ HdrlPrssrGvrnrIdlSwth : 56|2@1+ (1,0) [0|3] "" Vector__XXX
 SG_ HdrlPrssrGvrnrInrsSwth : 60|2@1+ (1,0) [0|3] "" Vector__XXX
 SG_ HdrlPrssrGvrnrPrstSwth : 62|2@1+ (1,0) [0|3] "" Vector__XXX
 SG_ HydraulicIntakePressure : 24|16@1+ (0.0001220703125,-1) [-1|6.84362793] "MPa" Vector__XXX
 SG_ HydraulicPressure : 0|16@1+ (2,0) [0|128510] "kPa" Vector__XXX

BO_ 2565868030 VDC2: 8 Vector__XXX
 SG_ LateralAcceleration : 40|16@1+ (0.00048828125,-15.687) [-15.687|15.687] "m/(s*s)" Vector__XXX
 SG_ LongitudinalAcceleration : 56|8@1+ (0.1,-12.5) [-12.5|12.5] "m/(s*s)" Vector__XXX
 SG_ SteeringWheelAngle : 0|16@1+ (0.0009765625,-31.374) [-31.374|31.374] "rad" Vector__XXX
 SG_ SteeringWheelAngleSensorType : 22|2@1+ (1,0) [0|3] "" Vector__XXX
 SG_ SteeringWheelTurnCounter : 16|6@1+ (1,-32) [-32|29] "turns" Vector__XXX
 SG_ YawRate : 24|16@1+ (0.0001220703125,-3.92) [-3.92|3.92] "rad/s" Vector__XXX

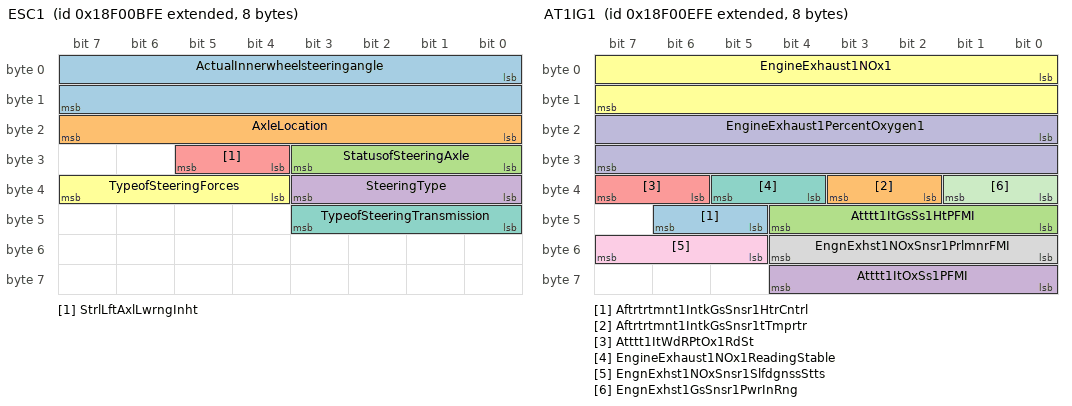
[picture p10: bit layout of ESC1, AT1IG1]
BO_ 2565868542 ESC1: 8 Vector__XXX
 SG_ ActualInnerwheelsteeringangle : 0|16@1+ (0.00390625,-125) [-125|125] "deg" Vector__XXX
 SG_ AxleLocation : 16|8@1+ (1,0) [0|255] "" Vector__XXX
 SG_ StatusofSteeringAxle : 24|4@1+ (1,0) [0|15] "" Vector__XXX
 SG_ SteeringType : 32|4@1+ (1,0) [0|15] "" Vector__XXX
 SG_ StrlLftAxlLwrngInht : 28|2@1+ (1,0) [0|3] "" Vector__XXX
 SG_ TypeofSteeringForces : 36|4@1+ (1,0) [0|15] "" Vector__XXX
 SG_ TypeofSteeringTransmission : 40|4@1+ (1,0) [0|15] "" Vector__XXX

BO_ 2565869310 AT1IG1: 8 Vector__XXX
 SG_ Aftrtrtmnt1IntkGsSnsr1HtrCntrl : 45|2@1+ (1,0) [0|3] "" Vector__XXX
 SG_ Aftrtrtmnt1IntkGsSnsr1tTmprtr : 34|2@1+ (1,0) [0|3] "" Vector__XXX
 SG_ Atttt1ItGsSs1HtPFMI : 40|5@1+ (1,0) [0|31] "binary" Vector__XXX
 SG_ Atttt1ItOxSs1PFMI : 56|5@1+ (1,0) [0|31] "binary" Vector__XXX
 SG_ Atttt1ItWdRPtOx1RdSt : 38|2@1+ (1,0) [0|3] "" Vector__XXX
 SG_ EngineExhaust1NOx1 : 0|16@1+ (0.05,-200) [-200|3012.75] "ppm" Vector__XXX
 SG_ EngineExhaust1NOx1ReadingStable : 36|2@1+ (1,0) [0|3] "" Vector__XXX
 SG_ EngnExhst1NOxSnsr1PrlmnrFMI : 48|5@1+ (1,0) [0|31] "binary" Vector__XXX
 SG_ EngnExhst1NOxSnsr1SlfdgnssStts : 53|3@1+ (1,0) [0|7] "" Vector__XXX
 SG_ EngineExhaust1PercentOxygen1 : 16|16@1+ (0.000514,-12) [-12|21.02707] "%" Vector__XXX
 SG_ EngnExhst1GsSnsr1PwrInRng : 32|2@1+ (1,0) [0|3] "" Vector__XXX

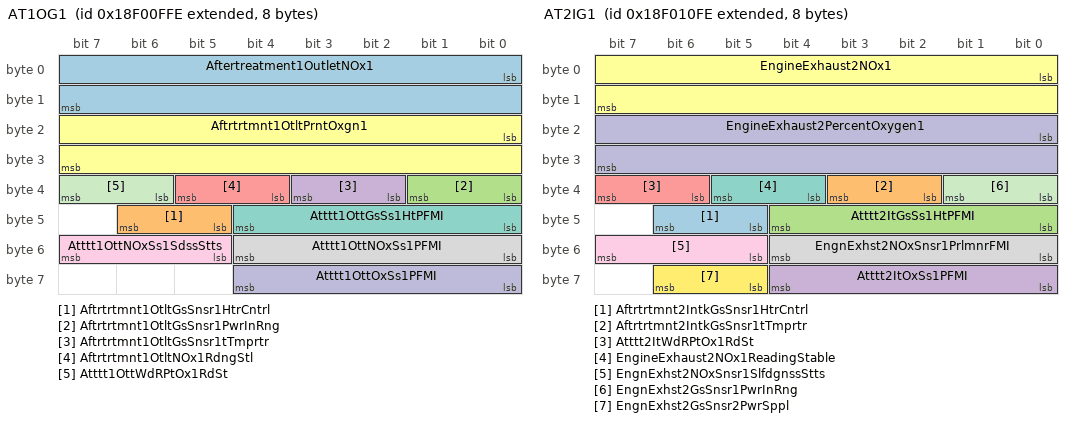
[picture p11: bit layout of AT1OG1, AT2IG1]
BO_ 2565869566 AT1OG1: 8 Vector__XXX
 SG_ Aftertreatment1OutletNOx1 : 0|16@1+ (0.05,-200) [-200|3012.75] "ppm" Vector__XXX
 SG_ Aftrtrtmnt1OtltGsSnsr1HtrCntrl : 45|2@1+ (1,0) [0|3] "" Vector__XXX
 SG_ Aftrtrtmnt1OtltGsSnsr1PwrInRng : 32|2@1+ (1,0) [0|3] "" Vector__XXX
 SG_ Aftrtrtmnt1OtltGsSnsr1tTmprtr : 34|2@1+ (1,0) [0|3] "" Vector__XXX
 SG_ Aftrtrtmnt1OtltNOx1RdngStl : 36|2@1+ (1,0) [0|3] "" Vector__XXX
 SG_ Aftrtrtmnt1OtltPrntOxgn1 : 16|16@1+ (0.000514,-12) [-12|21.02707] "%" Vector__XXX
 SG_ Atttt1OttGsSs1HtPFMI : 40|5@1+ (1,0) [0|31] "binary" Vector__XXX
 SG_ Atttt1OttNOxSs1PFMI : 48|5@1+ (1,0) [0|31] "binary" Vector__XXX
 SG_ Atttt1OttNOxSs1SdssStts : 53|3@1+ (1,0) [0|7] "" Vector__XXX
 SG_ Atttt1OttOxSs1PFMI : 56|5@1+ (1,0) [0|31] "binary" Vector__XXX
 SG_ Atttt1OttWdRPtOx1RdSt : 38|2@1+ (1,0) [0|3] "" Vector__XXX

BO_ 2565869822 AT2IG1: 8 Vector__XXX
 SG_ Aftrtrtmnt2IntkGsSnsr1HtrCntrl : 45|2@1+ (1,0) [0|3] "" Vector__XXX
 SG_ Aftrtrtmnt2IntkGsSnsr1tTmprtr : 34|2@1+ (1,0) [0|3] "" Vector__XXX
 SG_ Atttt2ItGsSs1HtPFMI : 40|5@1+ (1,0) [0|31] "binary" Vector__XXX
 SG_ Atttt2ItOxSs1PFMI : 56|5@1+ (1,0) [0|31] "binary" Vector__XXX
 SG_ Atttt2ItWdRPtOx1RdSt : 38|2@1+ (1,0) [0|3] "" Vector__XXX
 SG_ EngineExhaust2NOx1 : 0|16@1+ (0.05,-200) [-200|3012.75] "ppm" Vector__XXX
 SG_ EngineExhaust2NOx1ReadingStable : 36|2@1+ (1,0) [0|3] "" Vector__XXX
 SG_ EngnExhst2NOxSnsr1PrlmnrFMI : 48|5@1+ (1,0) [0|31] "binary" Vector__XXX
 SG_ EngnExhst2NOxSnsr1SlfdgnssStts : 53|3@1+ (1,0) [0|7] "" Vector__XXX
 SG_ EngineExhaust2PercentOxygen1 : 16|16@1+ (0.000514,-12) [-12|21.02707] "%" Vector__XXX
 SG_ EngnExhst2GsSnsr1PwrInRng : 32|2@1+ (1,0) [0|3] "" Vector__XXX
 SG_ EngnExhst2GsSnsr2PwrSppl : 61|2@1+ (1,0) [0|3] "" Vector__XXX

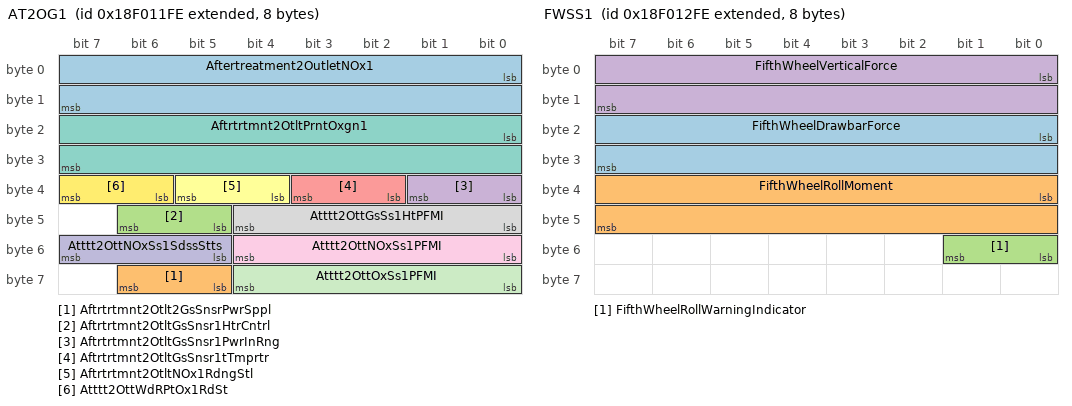
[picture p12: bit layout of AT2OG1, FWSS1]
BO_ 2565870078 AT2OG1: 8 Vector__XXX
 SG_ Aftertreatment2OutletNOx1 : 0|16@1+ (0.05,-200) [-200|3012.75] "ppm" Vector__XXX
 SG_ Aftrtrtmnt2Otlt2GsSnsrPwrSppl : 61|2@1+ (1,0) [0|3] "" Vector__XXX
 SG_ Aftrtrtmnt2OtltGsSnsr1HtrCntrl : 45|2@1+ (1,0) [0|3] "" Vector__XXX
 SG_ Aftrtrtmnt2OtltGsSnsr1PwrInRng : 32|2@1+ (1,0) [0|3] "" Vector__XXX
 SG_ Aftrtrtmnt2OtltGsSnsr1tTmprtr : 34|2@1+ (1,0) [0|3] "" Vector__XXX
 SG_ Aftrtrtmnt2OtltNOx1RdngStl : 36|2@1+ (1,0) [0|3] "" Vector__XXX
 SG_ Aftrtrtmnt2OtltPrntOxgn1 : 16|16@1+ (0.000514,-12) [-12|21.02707] "%" Vector__XXX
 SG_ Atttt2OttGsSs1HtPFMI : 40|5@1+ (1,0) [0|31] "binary" Vector__XXX
 SG_ Atttt2OttNOxSs1PFMI : 48|5@1+ (1,0) [0|31] "binary" Vector__XXX
 SG_ Atttt2OttNOxSs1SdssStts : 53|3@1+ (1,0) [0|7] "" Vector__XXX
 SG_ Atttt2OttOxSs1PFMI : 56|5@1+ (1,0) [0|31] "binary" Vector__XXX
 SG_ Atttt2OttWdRPtOx1RdSt : 38|2@1+ (1,0) [0|3] "" Vector__XXX

BO_ 2565870334 FWSS1: 8 Vector__XXX
 SG_ FifthWheelDrawbarForce : 16|16@1+ (10,-320000) [-320000|322550] "N" Vector__XXX
 SG_ FifthWheelRollMoment : 32|16@1+ (10,-320000) [-320000|322550] "N" Vector__XXX
 SG_ FifthWheelRollWarningIndicator : 48|2@1+ (1,0) [0|3] "" Vector__XXX
 SG_ FifthWheelVerticalForce : 0|16@1+ (5,0) [0|321275] "N" Vector__XXX

CM_ BO_ 2558394110 "Electrified Accessory Motor Command";
CM_ SG_ 2558394110 EltrfdAssrMtrEnlCmmnd "Electrified Accessory Motor Enable Command: Enable and direction command to this electrified Accessory Motor.00b = Accessory Motor Off01b = Accessory Motor On Normal/Default Direction10b = Accessory Motor On Reverse Direction11b = Don't Care/Take no ...";
CM_ SG_ 2558394110 EltrfdAssrMtrPrntSpdCmmnd "Electrified Accessory Motor Percent Speed Command: Speed command to this Electrified Accessory Motor in percentage of maximum speed.Note: Both Speed Command and Percent Speed Command cannot be used at the same time.  Always set the unused speed comma...";
CM_ SG_ 2558394110 EltrfdAssrMtrPwrHld "Electrified Accessory Motor Power Hold: Command to allow this Electrified Accessory Motor to remain alive independently of the electrical enable input to the Accessory Motor.  For example, this could allow continued device operation after the keyswit...";
CM_ SG_ 2558394110 EltrfdAssrMtrSpdCmmnd "Electrified Accessory Motor Speed Command: Speed command to this Electrified Accessory Motor.  Note: Both Speed Command and Percent Speed Command cannot be used at the same time.  Always set the unused speed command to Not Available.If both commands ...";
CM_ SG_ 2558394110 ElectrifiedAccessoryMotor1 "Electrified Accessory Motor 1: Indicates this instance of the Electrified Accessory Motor.  Multiple instances can be controlled with the same command PG by setting each unique instance parameter to 0b.0b = Command applied to this Accessory Motor Ins...";
CM_ SG_ 2558394110 ElectrifiedAccessoryMotor2 "Electrified Accessory Motor 2: Indicates this instance of the Electrified Accessory Motor.  Multiple instances can be controlled with the same command PG by setting each unique instance parameter to 0b.0b = Command applied to this Accessory Motor Ins...";
CM_ SG_ 2558394110 ElectrifiedAccessoryMotor3 "Electrified Accessory Motor 3: Indicates this instance of the Electrified Accessory Motor.  Multiple instances can be controlled with the same command PG by setting each unique instance parameter to 0b.0b = Command applied to this Accessory Motor Ins...";
CM_ SG_ 2558394110 ElectrifiedAccessoryMotor4 "Electrified Accessory Motor 4: Indicates this instance of the Electrified Accessory Motor.  Multiple instances can be controlled with the same command PG by setting each unique instance parameter to 0b.0b = Command applied to this Accessory Motor Ins...";
CM_ SG_ 2558394110 ElectrifiedAccessoryMotor5 "Electrified Accessory Motor 5: Indicates this instance of the Electrified Accessory Motor.  Multiple instances can be controlled with the same command PG by setting each unique instance parameter to 0b.0b = Command applied to this Accessory Motor Ins...";
CM_ SG_ 2558394110 ElectrifiedAccessoryMotor6 "Electrified Accessory Motor 6: Indicates this instance of the Electrified Accessory Motor.  Multiple instances can be controlled with the same command PG by setting each unique instance parameter to 0b.0b = Command applied to this Accessory Motor Ins...";
CM_ SG_ 2558394110 ElectrifiedAccessoryMotor7 "Electrified Accessory Motor 7: Indicates this instance of the Electrified Accessory Motor.  Multiple instances can be controlled with the same command PG by setting each unique instance parameter to 0b.0b = Command applied to this Accessory Motor Ins...";
CM_ SG_ 2558394110 ElectrifiedAccessoryMotor8 "Electrified Accessory Motor 8: Indicates this instance of the Electrified Accessory Motor.  Multiple instances can be controlled with the same command PG by setting each unique instance parameter to 0b.0b = Command applied to this Accessory Motor Ins...";
CM_ SG_ 2558394110 ElectrifiedAccessoryMotor9 "Electrified Accessory Motor 9: Indicates this instance of the Electrified Accessory Motor.  Multiple instances can be controlled with the same command PG by setting each unique instance parameter to 0b.0b = Command applied to this Accessory Motor Ins...";
CM_ SG_ 2558394110 ElectrifiedAccessoryMotor10 "Electrified Accessory Motor 10: Indicates this instance of the Electrified Accessory Motor.  Multiple instances can be controlled with the same command PG by setting each unique instance parameter to 0b.0b = Command applied to this Accessory Motor In...";
CM_ SG_ 2558394110 ElectrifiedAccessoryMotor11 "Electrified Accessory Motor 11: Indicates this instance of the Electrified Accessory Motor.  Multiple instances can be controlled with the same command PG by setting each unique instance parameter to 0b.0b = Command applied to this Accessory Motor In...";
CM_ SG_ 2558394110 ElectrifiedAccessoryMotor12 "Electrified Accessory Motor 12: Indicates this instance of the Electrified Accessory Motor.  Multiple instances can be controlled with the same command PG by setting each unique instance parameter to 0b.0b = Command applied to this Accessory Motor In...";
CM_ SG_ 2558394110 ElectrifiedAccessoryMotor13 "Electrified Accessory Motor 13: Indicates this instance of the Electrified Accessory Motor.  Multiple instances can be controlled with the same command PG by setting each unique instance parameter to 0b.0b = Command applied to this Accessory Motor In...";
CM_ SG_ 2558394110 ElectrifiedAccessoryMotor14 "Electrified Accessory Motor 14: Indicates this instance of the Electrified Accessory Motor.  Multiple instances can be controlled with the same command PG by setting each unique instance parameter to 0b.0b = Command applied to this Accessory Motor In...";
CM_ SG_ 2558394110 ElectrifiedAccessoryMotor15 "Electrified Accessory Motor 15: Indicates this instance of the Electrified Accessory Motor.  Multiple instances can be controlled with the same command PG by setting each unique instance parameter to 0b.0b = Command applied to this Accessory Motor In...";
CM_ BO_ 2558459646 "Engine Speed Ramp Rate Boundary Request";
CM_ SG_ 2558459646 RqstdEngnSpdAlrtnRtLmt "Requested Engine Speed Acceleration Rate Limit: This parameter is intended to be received by a device sending speed commands to an engine (e.g. TSC1 or proprietary command). The sending device should issue speed commands such that this acceleration r...";
CM_ SG_ 2558459646 RqstdEngnSpdDlrtnRtLmt "Requested Engine Speed Deceleration Rate Limit: This parameter is intended to be received by a device sending speed commands to an engine (e.g. TSC1 or proprietary command). The sending device should issue speed commands such that this deceleration r...";
CM_ BO_ 2558525182 "Tire Sensor Identification Command";
CM_ SG_ 2558525182 NumberofTireSensors "Number of Tire Sensors: Total count of monitored tire sensor identification numbers represented in this instance of the parameter group.";
CM_ SG_ 2558525182 TireLocation "Tire Location: The location of monitored tire that corresponds with the tire sensor identification number SPN 7586. In order to specify the monitored tire by tire number, use the tire number SPN 7584.The high order 4 bits indicate the vehicle axle po...";
CM_ SG_ 2558525182 TireNumber "Tire Number: The number of the monitored tire that corresponds with the tire sensor identification number SPN 7586. In order to specify the monitored tire by location, use the tire location SPN 7585.The value FFh indicates this SP is not used.";
CM_ SG_ 2558525182 TireSensorIdentificationNumber "Tire Sensor Identification Number: The identification number of tire sensor for the tire specified in the tire sensor tire number (SPN 7584) or tire sensor location (SPN 7585).";
CM_ BO_ 2558590718 "Hybrid System Control 1";
CM_ SG_ 2558590718 ExtrnlEnrgSrCnntnDmnd "External Energy Source Connection Demand : This parameter allows for two external energy source connections.  Propulsion may or may not be allowed as defined by the Operator Vehicle Mode Request (SPN 7888).  The state of the engine (fuel cell etc.) i...";
CM_ SG_ 2558590718 HrdSstmPrplsnDslRqst "Hybrid System Propulsion Disable Request: Indicates the Hybrid System Disable Request state.  The signal gives network controllers the ability to disable the propulsion aspect of hybrid system operation when this request is on.  However, hybrid power...";
CM_ SG_ 2558590718 HrdSstmPrttnOvrrdRqst "Hybrid System Protection Override Request: Indicates the hybrid system protection override request state.  This request allows overriding of hybrid system protection features and failure modes allowing hybrid systems to continue to operate, if possib...";
CM_ SG_ 2558590718 HrdSstmRgnrtvBrkngDslRqst "Hybrid System Regenerative Braking Disable Request: Indicates the hybrid system regenerative braking disable request state.  This signal gives network controllers the ability to disable all regenerative braking.  This is not the operator controlled s...";
CM_ SG_ 2558590718 HybridPropulsionModeRequest "Hybrid Propulsion Mode Request : Hybrid Propulsion Mode Request is the operator intended propulsion mode.  This parameter can be from only one source on the vehicle.  Response to this request can be found in the Hybrid Propulsion Mode Status (SPN 789...";
CM_ SG_ 2558590718 HybridSystemShutdownCommand "Hybrid System Shutdown Command: Indicates the Hybrid System Shutdown Request state.  The signal gives network controllers the ability to disable all hybrid system functionality including propulsion, regenerative braking, and hybrid powered accessorie...";
CM_ SG_ 2558590718 OperatorVehicleModeRequest "Operator Vehicle Mode Request : Operator Vehicle Mode Request is the operator intended vehicle mode.  This parameter can be from only one source on the vehicle.  In the case of a Diesel-Electric Hybrid, the source of this parameter may be a vehicle c...";
CM_ SG_ 2558590718 StrdEnrgSrChrgDshrgRtRqst "Stored Energy Source Charge/Discharge Rate Request: Stored Energy Source Charge/Discharge Rate Request is used to control the rate at which the stored energy is changed in Energy Increasing or Energy Depleting modes.A value of FBh indicates a request...";
CM_ SG_ 2558590718 StrdEnrgSrStPntRqst "Stored Energy Source Set Point Request : Stored Energy Source Set Point Request is used to set the percentage that the Stored Energy Source should be managed to by the system.A value of FBh indicates a request for the default set point.  In the case ...";
CM_ SG_ 2558590718 HVESChargeConsent "HVES Charge Consent: Indicates the sender's consent to charge the system's HVES (high-voltage energy storage) from EVSE (electric vehicle supply equipment), i.e. offboard vehicle charging station.For example, a controller has certain application-spec...";
CM_ SG_ 2558590718 HrdPrplsnMdRqstdMxmmSpd "Hybrid Propulsion Mode Requested Maximum Speed: The requested maximum speed for the vehicle while in a Hybrid Propulsion Mode (see SPN 7889) other than Mode 1 - Stored Energy Source Sustaining.This shall be the operating vehicle speed limit while in ...";
CM_ SG_ 2558590718 HrdPrplsnMdRqstdDstn "Hybrid Propulsion Mode Requested Distance: The requested distance to maintain a Hybrid Propulsion Mode (see SPN 7889) other than Mode 1 - Stored Energy Source Sustaining.When the distance is met, or a protective mode is activated (e.g. HVES charge is...";
CM_ SG_ 2558590718 ConnectedEnergySourceType "Connected Energy Source Type: The type of energy source (EVSE) currently connected as specified in SPN 7890.This parameter and SPN 7890 shall only be sent by the same controller application.This parameter shall only be sent if SPN 7890 is also sent.T...";
CM_ BO_ 2558656254 "Aftertreatment System Control";
CM_ SG_ 2558656254 AftrtrtmntDslExhstFldDsrRdStts "Aftertreatment Diesel Exhaust Fluid Doser Ready Status: Indicates the aftertreatment systems operating conditions are appropriate for dosing.Note: Operating conditions may include but not limited to Diesel Exhaust Fluid tank level and Diesel Exhaust ...";
CM_ SG_ 2558656254 AftrtrtmntSstmEnlStts "Aftertreatment System Enable Status: Indicates that the aftertreatment system is enabled or disabled.  Enabled indicates the system will dose at regular intervals.00b = Aftertreatment System is Disabled01b = Aftertreatment System is Enabled10b = Erro...";
CM_ SG_ 2558656254 AftrtrtmntThrmlMngmntInhtRqst "Aftertreatment Thermal Management Inhibit Request: Provides state of inhibit request for Aftertreatment thermal management from external system.Aftertreatment Thermal Management indicates that the exhaust temperatures have been controlled for expecte...";
CM_ SG_ 2558656254 RqsttPrmtDEFHdrlStffnssChk "Request to Permit DEF Hydraulic Stiffness Check: A request to permit the DEF hydraulic stiffness check. The request continues to be broadcast until the stiffness check is finished or the corresponding permission status indicates an error.00b = no req...";
CM_ SG_ 2558656254 RqsttPrmtSCRDsngTstInjtn "Request to Permit SCR Dosing Test Injection: A request to permit the SCR dosing test injection. The request continues to be broadcast until the test injection is finished or the corresponding permission status indicates an error.000b = No request001b...";
CM_ BO_ 2558721790 "Tire Configuration Command Information";
CM_ SG_ 2558721790 ColdInflationPressureSetting "Cold Inflation Pressure Setting: Configurable value of the cold inflation pressure of the tire. Cold inflation pressure is the default/reference inflation pressure suggested by the manufacturer for a specific tire.";
CM_ SG_ 2558721790 ExtrmUndrPrssrPrntgThrshldSttng "Extreme Under Pressure Percentage Threshold Setting: Configurable percent deviation from the set cold inflation pressure, for the extreme under tire pressure alert.";
CM_ SG_ 2558721790 OverTemperatureSetting "Over Temperature Setting: Configurable constant temperature above which an over temperature alert will trigger.";
CM_ SG_ 2558721790 OvrPrssrPrntgThrshldSttng "Over Pressure Percentage Threshold Setting: Configurable percentage deviation from the set cold inflation pressure, for the over tire pressure alert.";
CM_ SG_ 2558721790 TireLocation "Tire Location: The location of monitored tire on the vehicle.The high order 4 bits indicate the vehicle axle position of the tire, counting front to back on the vehicle, with the value 0 representing the front axle on the vehicle. If the upper 4 bits...";
CM_ SG_ 2558721790 TireSensorEnableSetting "Tire Sensor Enable Setting: Command signal used to enable/disable the tire sensor. On receipt of this command, the tire sensor may either be enabled or disabled.00b = Off / Isolate / Disable01b = On / Enable10b = Reserved / Not Defined11b = Don't Car...";
CM_ SG_ 2558721790 UndrPrssrPrntgThrshldSttng "Under Pressure Percentage Threshold Setting: Configurable percent deviation from the set cold inflation pressure, for the under tire pressure alert.";
CM_ BO_ 2558787326 "Payload Calibration Information Command";
CM_ SG_ 2558787326 PayloadCorrectionFactorCommand "Payload Correction Factor Command: The payload correction factor is used to fine tune the sensor gain value.Correction factor calibration of the Payload Measurement system is performed through a Payload Calibration Set Point SP value of Correction Po...";
CM_ SG_ 2558787326 PldClrtnCmmnddWght "Payload Calibration Commanded Weight: The true known mass of real load weight applicable for the calibration point specified in SPN 6871 and used for calibrating Payload system.Multipoint calibration of the Payload Measurement system is performed by ...";
CM_ SG_ 2558787326 PldClrtnStPntCmmnd "Payload Calibration Set Point Command: Specifies the current payload point being calibrated. The data specified in the 'Payload Calibration Commanded Weight' SP (SPN 6872) or 'Payload Correction Factor Command' SP (SPN 6873) shall be used for calibra...";
CM_ BO_ 2558852862 "Aftertreatment 1 Particulate Sensor Control";
CM_ SG_ 2558852862 Aftrtrtmnt1PrtltSnsrDwpnt "Aftertreatment 1 Particulate Sensor Dewpoint: Indicates that the temperature near the particulate sensor has exceeded the dew point.00b = Dewpoint has not been reached01b = Dewpoint has been reached10b = SAE reserved11b = Not available";
CM_ SG_ 2558852862 Aftrtrtmnt1PrtltSnsrExhstTmprtr "Aftertreatment 1 Particulate Sensor Exhaust Temperature: This is the temperature in the exhaust stream that is closest to the particulate sensor. This could be a calculated value or read from another sensor. The ECU transmitting this message to the p...";
CM_ SG_ 2558852862 Aftrtrtmnt1PrtltSnsrExhstVlt "Aftertreatment 1 Particulate Sensor Exhaust Velocity: Velocity of the exhaust gas near the particulate sensor.";
CM_ SG_ 2558852862 Aftrtrtmnt1PrtltSnsrRgnrtnRqst "Aftertreatment 1 Particulate Sensor Regeneration Request: Another ECU would send this to request that the particulate sensor perform a regeneration of the sensor.  A request would be considered active when this parameter transitions from 00b to 01b.0...";
CM_ SG_ 2558852862 Aftrtrtmnt1PrtltSnsrShtdwnRqst "Aftertreatment 1 Particulate Sensor Shutdown Request: Aftertreatment 1 particulate sensor shutdown request.00b = Shutdown request not active01b = Shutdown request active10b = SAE reserved11b = Not available";
CM_ BO_ 2558918398 "Cab Message 2";
CM_ SG_ 2558918398 ActiveShiftConsoleRequest "Active Shift Console Request: Requests the shift console or shift selector that the operator desires to be active. See SPN 2945 (Active Shift Console Indicator) for feedback on which shift console is currently active.00b = Use Primary Shift Console01...";
CM_ SG_ 2558918398 AftrtrtmntSstmEnlCmmnd "Aftertreatment System Enable Command: Request to enable Aftertreatment system.00b = De-activate Aftertreatment System01b = Activate Aftertreatment System10b = Reserved11b = Don't care/Take no ActionNote: In some marine applications it may be desireab...";
CM_ SG_ 2558918398 AttttRtESpdAwdSwt "Aftertreatment Regeneration Engine Speed Allowed Switch: If this parameter is 01b, then the aftertreatment control system is permitted to perform an aftertreatment regeneration, but the aftertreatment control system is not allowed to take control of ...";
CM_ SG_ 2558918398 ElvtdEngnSpdAllwdSwth "Elevated Engine Speed Allowed Switch: Indicates the state of a switch to indicate the control system is permitted to automatically elevate the engine speed as needed for strategies such as cold mode, aftertreatment regeneration, etc. This is not a di...";
CM_ SG_ 2558918398 EngineFan2RequestedPercentSpeed "Engine Fan 2 Requested Percent Speed: Fan speed of the second fan in the system as a ratio of the actual fan drive (current speed) to the fully engaged fan drive (maximum fan speed). A two state fan (off/on) will use 0% and 100% respectively.  A thre...";
CM_ SG_ 2558918398 EngineStopStartDisableCommand "Engine Stop-Start Disable Command: Engine Stop-Start Disable Command indicates the desire to disable the engine stop-start functionality during propulsion modes. For momentary switches, this parameter does not indicate the state of the switch contact...";
CM_ SG_ 2558918398 EngnIdlMngmntPndngEvntOvrrd "Engine Idle Management Pending Event Override: Command signal which allows the operator to override an impending engine idle management start-up or an impending engine idle management shutdown.00b = Off (not requesting an override)01b = On (requestin...";
CM_ SG_ 2558918398 HtExhngrDrsPrgFrSwth "Heat Exchanger Debris Purge Force Switch: Indicates the state of a switch available to the operator that forces the system to purge the debris from the heat exchanger.00b = not active01b = active10b = error11b = not availableThis SP would be not acti...";
CM_ SG_ 2558918398 HtExhngrDrsPrgInhtSwth "Heat Exchanger Debris Purge Inhibit Switch: Indicates the state of a switch available to the operator that will inhibit the system from purging the debris from the heat exchanger.00b = not active01b = active10b = error11b = not availableThis SP would...";
CM_ SG_ 2558918398 PerformanceBiasSelection "Performance Bias Selection: Indicates the operating bias toward performance of the power source.For values between 0% and 50%, functionality is biased toward fuel economy, with values closer to 0% indicating more bias toward fuel economy.50% Function...";
CM_ SG_ 2558918398 PrdtvCrsCntrlDtvtnRqst "Predictive Cruise Control Deactivation Request: Indicates that the operator has requested to deactivate the predictive cruise control (PCC) function.If enabled, the PCC device may still provide notification of events in range, road grade, and other i...";
CM_ SG_ 2558918398 PrdtvCrsCntrlEnlSwth "Predictive Cruise Control Enable Switch: Indicates whether predictive cruise control (PCC) is enabled. When not enabled, the predictive cruise control does not calculate a speed offset or identify predictive cruise events, and the predictive cruise c...";
CM_ SG_ 2558918398 PrdtvCrsCntrlMxmmNgtvOffst "Predictive Cruise Control Maximum Negative Offset: Maximum speed decrease that the predictive cruise control (PCC) is allowed to request. This may be adjusted by the operator (either directly or indirectly) to tailor the performance of the PCC system...";
CM_ SG_ 2558918398 PrdtvCrsCntrlMxmmPstvOffst "Predictive Cruise Control Maximum Positive Offset: Maximum speed increase that the predictive cruise control (PCC) is allowed to request. This may be adjusted by the operator (either directly or indirectly) to tailor the performance of the PCC system...";
CM_ SG_ 2558918398 SCROprtrIndmntOvrrdSwth "SCR Operator Inducement Override Switch: The position of the operator inducement override switch. This switch function allows the operator to override an operator inducement derate.See EU Commission directive 2012/46/EU. Appendix 1 Section 5.5 for mo...";
CM_ SG_ 2558918398 TrnsmssnAtNtrlMnlRtrnEnlSwth "Transmission Auto-Neutral (Manual Return) Enable Switch: This enable switch is for optional use with interfaces using SPN 7695 [Transmission Auto-Neutral (Manual Return) Request] or another vehicle input configured for Auto-Neutral (Manual Return) fu...";
CM_ SG_ 2558918398 VehicleHoodSwitch "Vehicle Hood Switch: Switch used to indicate the vehicle hood is open or closed.00b = Vehicle hood is closed01b = Vehicle hood is open10b = Error11b = Not available";
CM_ BO_ 2558983934 "Switched Power Outputs Command";
CM_ SG_ 2558983934 SwitchedPowerOutput10Command "Switched Power Output #10 Command: Desired state of Switched Power Output #10. Used to set the desired state.00b = Output off01b = Output on10b = Reserved11b = Take no action";
CM_ SG_ 2558983934 SwitchedPowerOutput11Command "Switched Power Output #11 Command: Desired state of Switched Power Output #11. Used to set the desired state.00b = Output off01b = Output on10b = Reserved11b = Take no action";
CM_ SG_ 2558983934 SwitchedPowerOutput12Command "Switched Power Output #12 Command: Desired state of Switched Power Output #12. Used to set the desired state.00b = Output off01b = Output on10b = Reserved11b = Take no action";
CM_ SG_ 2558983934 SwitchedPowerOutput13Command "Switched Power Output #13 Command: Desired state of Switched Power Output #13. Used to set the desired state.00b = Output off01b = Output on10b = Reserved11b = Take no action";
CM_ SG_ 2558983934 SwitchedPowerOutput14Command "Switched Power Output #14 Command: Desired state of Switched Power Output #14. Used to set the desired state.00b = Output off01b = Output on10b = Reserved11b = Take no action";
CM_ SG_ 2558983934 SwitchedPowerOutput15Command "Switched Power Output #15 Command: Desired state of Switched Power Output #15. Used to set the desired state.00b = Output off01b = Output on10b = Reserved11b = Take no action";
CM_ SG_ 2558983934 SwitchedPowerOutput16Command "Switched Power Output #16 Command: Desired state of Switched Power Output #16. Used to set the desired state.00b = Output off01b = Output on10b = Reserved11b = Take no action";
CM_ SG_ 2558983934 SwitchedPowerOutput17Command "Switched Power Output #17 Command: Desired state of Switched Power Output #17. Used to set the desired state.00b = Output off01b = Output on10b = Reserved11b = Take no action";
CM_ SG_ 2558983934 SwitchedPowerOutput18Command "Switched Power Output #18 Command: Desired state of Switched Power Output #18. Used to set the desired state.00b = Output off01b = Output on10b = Reserved11b = Take no action";
CM_ SG_ 2558983934 SwitchedPowerOutput19Command "Switched Power Output #19 Command: Desired state of Switched Power Output #19. Used to set the desired state.00b = Output off01b = Output on10b = Reserved11b = Take no action";
CM_ SG_ 2558983934 SwitchedPowerOutput1Command "Switched Power Output #1 Command: Desired state of Switched Power Output #1. Used to set the desired state.00b = Output off01b = Output on10b = Reserved11b = Take no action";
CM_ SG_ 2558983934 SwitchedPowerOutput20Command "Switched Power Output #20 Command: Desired state of Switched Power Output #20. Used to set the desired state.00b = Output off01b = Output on10b = Reserved11b = Take no action";
CM_ SG_ 2558983934 SwitchedPowerOutput21Command "Switched Power Output #21 Command: Desired state of Switched Power Output #21. Used to set the desired state.00b = Output off01b = Output on10b = Reserved11b = Take no action";
CM_ SG_ 2558983934 SwitchedPowerOutput22Command "Switched Power Output #22 Command: Desired state of Switched Power Output #22. Used to set the desired state.00b = Output off01b = Output on10b = Reserved11b = Take no action";
CM_ SG_ 2558983934 SwitchedPowerOutput23Command "Switched Power Output #23 Command: Desired state of Switched Power Output #23. Used to set the desired state.00b = Output off01b = Output on10b = Reserved11b = Take no action";
CM_ SG_ 2558983934 SwitchedPowerOutput24Command "Switched Power Output #24 Command: Desired state of Switched Power Output #24. Used to set the desired state.00b = Output off01b = Output on10b = Reserved11b = Take no action";
CM_ SG_ 2558983934 SwitchedPowerOutput25Command "Switched Power Output #25 Command: Desired state of Switched Power Output #25. Used to set the desired state.00b = Output off01b = Output on10b = Reserved11b = Take no action";
CM_ SG_ 2558983934 SwitchedPowerOutput26Command "Switched Power Output #26 Command: Desired state of Switched Power Output #26. Used to set the desired state.00b = Output off01b = Output on10b = Reserved11b = Take no action";
CM_ SG_ 2558983934 SwitchedPowerOutput27Command "Switched Power Output #27 Command: Desired state of Switched Power Output #27. Used to set the desired state.00b = Output off01b = Output on10b = Reserved11b = Take no action";
CM_ SG_ 2558983934 SwitchedPowerOutput28Command "Switched Power Output #28 Command: Desired state of Switched Power Output #28. Used to set the desired state.00b = Output off01b = Output on10b = Reserved11b = Take no action";
CM_ SG_ 2558983934 SwitchedPowerOutput29Command "Switched Power Output #29 Command: Desired state of Switched Power Output #29. Used to set the desired state.00b = Output off01b = Output on10b = Reserved11b = Take no action";
CM_ SG_ 2558983934 SwitchedPowerOutput2Command "Switched Power Output #2 Command: Desired state of Switched Power Output #2. Used to set the desired state.00b = Output off01b = Output on10b = Reserved11b = Take no action";
CM_ SG_ 2558983934 SwitchedPowerOutput30Command "Switched Power Output #30 Command: Desired state of Switched Power Output #30. Used to set the desired state.00b = Output off01b = Output on10b = Reserved11b = Take no action";
CM_ SG_ 2558983934 SwitchedPowerOutput31Command "Switched Power Output #31 Command: Desired state of Switched Power Output #31. Used to set the desired state.00b = Output off01b = Output on10b = Reserved11b = Take no action";
CM_ SG_ 2558983934 SwitchedPowerOutput32Command "Switched Power Output #32 Command: Desired state of Switched Power Output #32. Used to set the desired state.00b = Output off01b = Output on10b = Reserved11b = Take no action";
CM_ SG_ 2558983934 SwitchedPowerOutput3Command "Switched Power Output #3 Command: Desired state of Switched Power Output #3. Used to set the desired state.00b = Output off01b = Output on10b = Reserved11b = Take no action";
CM_ SG_ 2558983934 SwitchedPowerOutput4Command "Switched Power Output #4 Command: Desired state of Switched Power Output #4. Used to set the desired state.00b = Output off01b = Output on10b = Reserved11b = Take no action";
CM_ SG_ 2558983934 SwitchedPowerOutput5Command "Switched Power Output #5 Command: Desired state of Switched Power Output #5. Used to set the desired state.00b = Output off01b = Output on10b = Reserved11b = Take no action";
CM_ SG_ 2558983934 SwitchedPowerOutput6Command "Switched Power Output #6 Command: Desired state of Switched Power Output #6. Used to set the desired state.00b = Output off01b = Output on10b = Reserved11b = Take no action";
CM_ SG_ 2558983934 SwitchedPowerOutput7Command "Switched Power Output #7 Command: Desired state of Switched Power Output #7. Used to set the desired state.00b = Output off01b = Output on10b = Reserved11b = Take no action";
CM_ SG_ 2558983934 SwitchedPowerOutput8Command "Switched Power Output #8 Command: Desired state of Switched Power Output #8. Used to set the desired state.00b = Output off01b = Output on10b = Reserved11b = Take no action";
CM_ SG_ 2558983934 SwitchedPowerOutput9Command "Switched Power Output #9 Command: Desired state of Switched Power Output #9. Used to set the desired state.00b = Output off01b = Output on10b = Reserved11b = Take no action";
CM_ BO_ 2559049470 "Engine State Requests";
CM_ SG_ 2559049470 DesiredEngineFuelingState "Desired Engine Fueling State: Devices send this request to the engine controller to:(a) Shut off engine fueling, but remain prepared to re-start quickly by not shutting down the control system, or(b) Keep the engine running.00b = Fueling not desired ...";
CM_ SG_ 2559049470 EngineFuelingDesiredReason "Engine Fueling Desired Reason: This parameter conveys the reason a device wants the engine running.This SP is intended to be used in conjunction with Desired Engine Fueling State (SPN 5793). When a device sends Desired Engine Fueling State = Fueling ...";
CM_ SG_ 2559049470 EngineFuelingNotDesiredReason "Engine Fueling Not Desired Reason: This parameter conveys the reason a device wants the engine to inhibit fueling. This SP is intended to be used in conjunction with Desired Engine Fueling State (SPN 5793). When a device sends Desired Engine Fueling ...";
CM_ SG_ 2559049470 EngineGaseousFuelUsageInhibited "Engine Gaseous Fuel Usage Inhibited: Used to request that the engine should not be allowed to use gaseous fuel for engine cylinder combustion. This state is relevant for dual fuel systems and would be used when conditions are detected that make it un...";
CM_ SG_ 2559049470 EngineShutdownCommand "Engine Shutdown Command: Command to shut down the engine. If this parameter is received as 01b, then the engine should behave as if the key switch was turned off. An example of how this parameter could be used is an ECU would send 01b for this parame...";
CM_ SG_ 2559049470 EngnGssFlSpplDsrdPrssr "Engine Gaseous Fuel Supply Desired Pressure: Desired gage pressure of gaseous fuel supply to the engine.";
CM_ SG_ 2559049470 EngnPrttnDrtOvrrdCmmnd "Engine Protection Derate Override Command: Command signal to override engine protection derate.This is to temporarily override an engine protection derate due to coolant temperature, oil pressure etc. This is for applications such as fire, rescue, an...";
CM_ SG_ 2559049470 RequestedFuelType "Requested Fuel Type: Engine controller receives this request from another control module to select the type of fuel to be used for engine operation.00h = Not available - NONE01h = Gasoline/petrol - GAS02h = Methanol - METH03h = Ethanol - ETH04h = Die...";
CM_ SG_ 2559049470 TrnsmssnIdlGvrnrFlngInht "Transmission Idle Governor Fueling Inhibit: This parameter is a command provided to the Engine Control Module (ECM) from the Transmission Control Module (TCM) to inhibit idle governor fueling in the unlikely event that transmission has detected a fai...";
CM_ BO_ 2559115006 "Radio Beacon Request";
CM_ SG_ 2559115006 RadioBeaconDirection "Radio Beacon Direction: Indicates the function of a particular instance of the Radio Beacon Request message. The 'Beacon Request' state indicates the message is sent to a wireless transceiver to request a transmit of the special beacon message. The '...";
CM_ SG_ 2559115006 TransmitterID2 "Transmitter ID 2: The ID of the off-board transmitter that sent the incoming special beacon message received by the wireless transceiver.";
CM_ SG_ 2559115006 UnqBnMssgIdntfrNmr "Unique Beacon Message Identifier Number: The number is used to identify a wireless message originating from a device on a particular machine. Within a beacon request message (see SPN 5755 [Radio Beacon Direction]), this number is included in the tran...";
CM_ SG_ 2559115006 WirelessSignalStrength2 "Wireless Signal Strength 2: The absolute received signal strength of the special beacon signal received from the off-board transmitter. The signal strength is reported as a Received Signal Strength Indicator (RSSI) value in dBm. This measurement meth...";
CM_ BO_ 2559573758 "Engine Configuration Commands";
CM_ SG_ 2559573758 CtLvEPttStdwOvdCd "Coolant Level Engine Protection Shutdown Override Command: Overrides the engine protection shutdown functionality due to low coolant level.  00b = Disable engine protection shutdown override due to low coolant level01b = Enable engine protection shut...";
CM_ BO_ 2559639294 "Supplemental Fan Command";
CM_ SG_ 2559639294 SupplementalFanDirectionCommand "Supplemental Fan Direction Command: Direction command to the Supplemental Fan. Fan can be commanded to run forward or reverse.00b = Forward01b = Reverse10b = Reserved11b = Don't care/take no action (leave function as is)";
CM_ SG_ 2559639294 SupplementalFanEnableCommand "Supplemental Fan Enable Command: Enable/Disable command to Supplemental Fan.00b = Disable 01b = Enable10b = Reserved 11b = Don't Care/Take no action";
CM_ SG_ 2559639294 SupplementalFanPowerHold "Supplemental Fan Power Hold: Command to allow the supplemental fan controller to remain alive independently of the electrical enable input to the fan. This allows the fan controller to remain alive after the key switch has disabled the electrical ena...";
CM_ SG_ 2559639294 SupplementalFanSpeedCommand "Supplemental Fan Speed Command: Speed command to Supplemental Fan.";
CM_ BO_ 2559704830 "Vehicle/Chassis Lubrication System 1";
CM_ SG_ 2559704830 LrtnOprtnMdStCmmnd "Lubrication Operation Mode Set Command: Command signal to change lubrication system operational mode. The mode set command gives the operator and/or technician the ability to change the operational mode when diagnosing and servicing of the system is ...";
CM_ SG_ 2559704830 LubricationCycleModeLockCommand "Lubrication Cycle Mode Lock Command: Command signal to lock or unlock the ability to change the lubrication cycle mode.  Locking the lubrication mode would prevent the changing of the lubrication cycle mode, perhaps by an operator.00b = Not Locked01b...";
CM_ SG_ 2559704830 LubricationCycleSetCommand "Lubrication Cycle Set Command: Command signal to change the lubrication cycle. It gives the operator or technician the ability to the change the frequency of lubrication.000b = Cycle mode # 1 (Lowest Lubrication Frequency)001b = Cycle mode # 2010b = ...";
CM_ SG_ 2559704830 LubricationPumpEnableCommand "Lubrication Pump Enable Command: Command signal to reset the lubrication pump.  It allows the operator and/or technician to reset the paused lubrication pump and clear lubrication system faults. This shall enable the lubrication system to resume its ...";
CM_ SG_ 2559704830 LubricationTimingCycleCommand "Lubrication Timing Cycle Command: Command signal to enable or pause the lubrication activation clock 00b = Pause01b = Enable10b = Reserved 11b = Take no action     Note:  In some vehicles or machines the lubrication is only required when the vehicle ...";
CM_ BO_ 2559770366 "Aftertreatment 1 Hydrocarbon Doser Information 1";
CM_ SG_ 2559770366 HydrocarbonDoserPurgingRequired "Hydrocarbon Doser Purging Required: Purging of the Hydrocarbon Doser (HCD) is required.  Request could come from the HCD system.00b = Purging not required01b = Purging required - less urgent10b = Purging required - urgent11b = Not available";
CM_ SG_ 2559770366 RequestedFuelMassRate "Requested Fuel Mass Rate: Requested fuel dosing quantity from hydrocarbon doser.";
CM_ SG_ 2559770366 Aftertreatment1DPFHydrocarbon "Aftertreatment 1 DPF Hydrocarbon: Accumulated unburned fuel in the DPF.  0% = no unburned fuel in DPF, 100% = maximum recommended capacity of unburned fuel in DPF.";
CM_ SG_ 2559770366 HydrocarbonDoserStatus "Hydrocarbon Doser Status: Indicates whether the Hydrocarbon (HC) Doser/ HC Dosing system is enabled or is waiting for regeneration.000b = HC doser disabled001b = HC doser active010b = SAE reserved011b = HC doser enabled, waiting for regeneration100b ...";
CM_ SG_ 2559770366 HydrocarbonDoserInjectingStatus "Hydrocarbon Doser Injecting Status: Indicates whether the Hydrocarbon Doser (HCD) is presently injecting diesel fuel into the exhaust pipe.00b = Injecting not active01b = Injecting active10b = Error11b = Not available";
CM_ SG_ 2559770366 DgnstSttsfHdrrnDsr "Diagnostic Status of Hydrocarbon Doser: Indicates whether an error is active in the Hydrocarbon Doser (HCD) or whether the internal cyclic system test of the HCD is presently active.  This is not intended to replace the DM8/DM30 - Test results requir...";
CM_ BO_ 2559901438 "Aftertreatment 1 Diesel Particulate Filter Soot Sensor Calibration";
CM_ SG_ 2559901438 Atttt1DsPttFtStMCtOst "Aftertreatment 1 Diesel Particulate Filter Soot Mean Calibration Offset: Calibration offset for the soot Mean for Aftertreatment 1 Diesel Particulate Filter soot sensor.";
CM_ SG_ 2559901438 Atttt1DsPttFtStStddDvtCtOst "Aftertreatment 1 Diesel Particulate Filter Soot Standard Deviation Calibration Offset: Calibration offset for the soot standard deviation for Aftertreatment 1 Diesel Particulate Filter soot sensor.";
CM_ BO_ 2559966974 "Aftertreatment 2 Diesel Particulate Filter Soot Sensor Calibration";
CM_ SG_ 2559966974 Atttt2DsPttFtStMCtOst "Aftertreatment 2 Diesel Particulate Filter Soot Mean Calibration Offset: Calibration offset for the soot Mean for Aftertreatment 2 Diesel Particulate Filter soot sensor.";
CM_ SG_ 2559966974 Atttt2DsPttFtStStddDvtCtOst "Aftertreatment 2 Diesel Particulate Filter Soot Standard Deviation Calibration Offset: Calibration offset for the soot standard deviation for Aftertreatment 2 Diesel Particulate Filter soot sensor.";
CM_ BO_ 2560032510 "Low Voltage Disconnect Set Operating Mode";
CM_ SG_ 2560032510 LwVltgDsnntDsrdOprtngMd "Low Voltage Disconnect Desired Operating Mode: Desired Operating Mode of the LVD.  Used to issue a J1939 request to the LVD to change modes.0000b = Automatic0001b to 0011b = Reserved0100b = Manual Disconnect0101b = Manual Connect0110b to 1110b = Rese...";
CM_ BO_ 2560098046 "Noise Control Status";
CM_ SG_ 2560098046 CabNoiseControlStatus "Cab Noise Control Status: This parameter returns the current status of the Cab Noise Control system.00b = Cab Noise Control System ON-Line01b = Cab Noise Control System OFF-Line10b = Error Indicator11b = Not Available/Not Requested";
CM_ SG_ 2560098046 CabNoiseControlTuningStatus "Cab Noise Control Tuning Status: This parameter returns the current status of tuning function of the Cab Noise Control system.    When the tuning state is active, the Cab Noise Control System adjusts certain system characteristics (e.g. to account fo...";
CM_ BO_ 2560163582 "Noise Control 1";
CM_ SG_ 2560163582 CabNoiseControlCommand "Cab Noise Control Command: Command signal to change the state of the Cab Noise Control System to on-line or off-line00b = Take Cab Noise Control System Off Line01b = Bring Cab Noise Control System On Line10b = Reserved11b = Don't Care/Not Commanded...";
CM_ SG_ 2560163582 CabNoiseControlTuningCommand "Cab Noise Control Tuning Command: Command values for the Tuning State of the Cab Noise Control System.  The Tuning State allows the Cab Noise Control System to adjust certain system characteristics (e.g. to account for microphone or speaker degradati...";
CM_ BO_ 2560360190 "Proprietary Method Identification";
CM_ SG_ 2560360190 DataDictionaryManufacturerCode "Data Dictionary Manufacturer Code: The J1939 Manufacturer Code (see J1939 Table B10) associated with the manufacturer who defined the proprietary communications method.  7FFh reserved for Not Available";
CM_ SG_ 2560360190 DataDictionaryMethod "Data Dictionary Method: A manufacturer defined code to define the proprietary communications method.  The structure and interpretation of the code is manufacturer specific.  This allows manufacturers to establish their own methods for reporting propr...";
CM_ BO_ 2560425726 "Auxiliary Input/Output Status 7";
CM_ SG_ 2560425726 AuxiliaryIOChannel15 "Auxiliary I/O Channel #15: Identifies the current value of auxiliary input/output channels that are configured uniquely per application.";
CM_ SG_ 2560425726 AuxiliaryIOChannel16 "Auxiliary I/O Channel #16: Identifies the current value of auxiliary input/output channels that are configured uniquely per application.";
CM_ SG_ 2560425726 AuxiliaryIOChannel17 "Auxiliary I/O Channel #17: Identifies the current value of auxiliary input/output channels that are configured uniquely per application.";
CM_ SG_ 2560425726 AuxiliaryIOChannel18 "Auxiliary I/O Channel #18: Identifies the current value of auxiliary input/output channels that are configured uniquely per application.";
CM_ SG_ 2560425726 AuxiliaryIOChannel19 "Auxiliary I/O Channel #19: Identifies the current value of auxiliary input/output channels that are configured uniquely per application.";
CM_ SG_ 2560425726 AuxiliaryIOChannel20 "Auxiliary I/O Channel #20: Identifies the current value of auxiliary input/output channels that are configured uniquely per application.";
CM_ SG_ 2560425726 AuxiliaryIOChannel21 "Auxiliary I/O Channel #21: Identifies the current value of auxiliary input/output channels that are configured uniquely per application.";
CM_ SG_ 2560425726 AuxiliaryIOChannel22 "Auxiliary I/O Channel #22: Identifies the current value of auxiliary input/output channels that are configured uniquely per application.";
CM_ BO_ 2560491262 "Auxiliary Input/Output Status 6";
CM_ SG_ 2560491262 AuxiliaryIOChannel10 "Auxiliary I/O Channel #10: Identifies the current value of auxiliary input/output channels that are configured uniquely per application.";
CM_ SG_ 2560491262 AuxiliaryIOChannel11 "Auxiliary I/O Channel #11: Identifies the current value of auxiliary input/output channels that are configured uniquely per application.";
CM_ SG_ 2560491262 AuxiliaryIOChannel12 "Auxiliary I/O Channel #12: Identifies the current value of auxiliary input/output channels that are configured uniquely per application.";
CM_ SG_ 2560491262 AuxiliaryIOChannel13 "Auxiliary I/O Channel #13: Identifies the current value of auxiliary input/output channels that are configured uniquely per application.";
CM_ SG_ 2560491262 AuxiliaryIOChannel14 "Auxiliary I/O Channel #14: Identifies the current value of auxiliary input/output channels that are configured uniquely per application.";
CM_ SG_ 2560491262 AuxiliaryIOChannel7 "Auxiliary I/O Channel #7: Identifies the current value of auxiliary input/output channels that are configured uniquely per application.";
CM_ SG_ 2560491262 AuxiliaryIOChannel8 "Auxiliary I/O Channel #8: Identifies the current value of auxiliary input/output channels that are configured uniquely per application.";
CM_ SG_ 2560491262 AuxiliaryIOChannel9 "Auxiliary I/O Channel #9: Identifies the current value of auxiliary input/output channels that are configured uniquely per application.";
CM_ BO_ 2561015550 "Auxiliary Input/Output Status 4";
CM_ SG_ 2561015550 AuxiliaryIO100 "Auxiliary I/O #100: Identifies the current status of auxiliary input/output functions that are configured uniquely per application.00b = Auxiliary channel off01b = Auxiliary channel on10b = Error Indicator or Not Used , depending on application11b = ...";
CM_ SG_ 2561015550 AuxiliaryIO101 "Auxiliary I/O #101: Identifies the current status of auxiliary input/output functions that are configured uniquely per application.00b = Auxiliary channel off01b = Auxiliary channel on10b = Error Indicator or Not Used , depending on application11b = ...";
CM_ SG_ 2561015550 AuxiliaryIO102 "Auxiliary I/O #102: Identifies the current status of auxiliary input/output functions that are configured uniquely per application.00b = Auxiliary channel off01b = Auxiliary channel on10b = Error Indicator or Not Used , depending on application11b = ...";
CM_ SG_ 2561015550 AuxiliaryIO103 "Auxiliary I/O #103: Identifies the current status of auxiliary input/output functions that are configured uniquely per application.00b = Auxiliary channel off01b = Auxiliary channel on10b = Error Indicator or Not Used , depending on application11b = ...";
CM_ SG_ 2561015550 AuxiliaryIO104 "Auxiliary I/O #104: Identifies the current status of auxiliary input/output functions that are configured uniquely per application.00b = Auxiliary channel off01b = Auxiliary channel on10b = Error Indicator or Not Used , depending on application11b = ...";
CM_ SG_ 2561015550 AuxiliaryIO105 "Auxiliary I/O #105: Identifies the current status of auxiliary input/output functions that are configured uniquely per application.00b = Auxiliary channel off01b = Auxiliary channel on10b = Error Indicator or Not Used , depending on application11b = ...";
CM_ SG_ 2561015550 AuxiliaryIO106 "Auxiliary I/O #106: Identifies the current status of auxiliary input/output functions that are configured uniquely per application.00b = Auxiliary channel off01b = Auxiliary channel on10b = Error Indicator or Not Used , depending on application11b = ...";
CM_ SG_ 2561015550 AuxiliaryIO107 "Auxiliary I/O #107: Identifies the current status of auxiliary input/output functions that are configured uniquely per application.00b = Auxiliary channel off01b = Auxiliary channel on10b = Error Indicator or Not Used , depending on application11b = ...";
CM_ SG_ 2561015550 AuxiliaryIO108 "Auxiliary I/O #108: Identifies the current status of auxiliary input/output functions that are configured uniquely per application.00b = Auxiliary channel off01b = Auxiliary channel on10b = Error Indicator or Not Used , depending on application11b = ...";
CM_ SG_ 2561015550 AuxiliaryIO109 "Auxiliary I/O #109: Identifies the current status of auxiliary input/output functions that are configured uniquely per application.00b = Auxiliary channel off01b = Auxiliary channel on10b = Error Indicator or Not Used , depending on application11b = ...";
CM_ SG_ 2561015550 AuxiliaryIO110 "Auxiliary I/O #110: Identifies the current status of auxiliary input/output functions that are configured uniquely per application.00b = Auxiliary channel off01b = Auxiliary channel on10b = Error Indicator or Not Used , depending on application11b = ...";
CM_ SG_ 2561015550 AuxiliaryIO111 "Auxiliary I/O #111: Identifies the current status of auxiliary input/output functions that are configured uniquely per application.00b = Auxiliary channel off01b = Auxiliary channel on10b = Error Indicator or Not Used , depending on application11b = ...";
CM_ SG_ 2561015550 AuxiliaryIO112 "Auxiliary I/O #112: Identifies the current status of auxiliary input/output functions that are configured uniquely per application.00b = Auxiliary channel off01b = Auxiliary channel on10b = Error Indicator or Not Used , depending on application11b = ...";
CM_ SG_ 2561015550 AuxiliaryIO81 "Auxiliary I/O #81: Identifies the current status of auxiliary input/output functions that are configured uniquely per application.00b = Auxiliary channel off01b = Auxiliary channel on10b = Error Indicator or Not Used , depending on application11b = N...";
CM_ SG_ 2561015550 AuxiliaryIO82 "Auxiliary I/O #82: Identifies the current status of auxiliary input/output functions that are configured uniquely per application.00b = Auxiliary channel off01b = Auxiliary channel on10b = Error Indicator or Not Used , depending on application11b = N...";
CM_ SG_ 2561015550 AuxiliaryIO83 "Auxiliary I/O #83: Identifies the current status of auxiliary input/output functions that are configured uniquely per application.00b = Auxiliary channel off01b = Auxiliary channel on10b = Error Indicator or Not Used , depending on application11b = N...";
CM_ SG_ 2561015550 AuxiliaryIO84 "Auxiliary I/O #84: Identifies the current status of auxiliary input/output functions that are configured uniquely per application.00b = Auxiliary channel off01b = Auxiliary channel on10b = Error Indicator or Not Used , depending on application11b = N...";
CM_ SG_ 2561015550 AuxiliaryIO85 "Auxiliary I/O #85: Identifies the current status of auxiliary input/output functions that are configured uniquely per application.00b = Auxiliary channel off01b = Auxiliary channel on10b = Error Indicator or Not Used , depending on application11b = N...";
CM_ SG_ 2561015550 AuxiliaryIO86 "Auxiliary I/O #86: Identifies the current status of auxiliary input/output functions that are configured uniquely per application.00b = Auxiliary channel off01b = Auxiliary channel on10b = Error Indicator or Not Used , depending on application11b = N...";
CM_ SG_ 2561015550 AuxiliaryIO87 "Auxiliary I/O #87: Identifies the current status of auxiliary input/output functions that are configured uniquely per application.00b = Auxiliary channel off01b = Auxiliary channel on10b = Error Indicator or Not Used , depending on application11b = N...";
CM_ SG_ 2561015550 AuxiliaryIO88 "Auxiliary I/O #88: Identifies the current status of auxiliary input/output functions that are configured uniquely per application.00b = Auxiliary channel off01b = Auxiliary channel on10b = Error Indicator or Not Used , depending on application11b = N...";
CM_ SG_ 2561015550 AuxiliaryIO89 "Auxiliary I/O #89: Identifies the current status of auxiliary input/output functions that are configured uniquely per application.00b = Auxiliary channel off01b = Auxiliary channel on10b = Error Indicator or Not Used , depending on application11b = N...";
CM_ SG_ 2561015550 AuxiliaryIO90 "Auxiliary I/O #90: Identifies the current status of auxiliary input/output functions that are configured uniquely per application.00b = Auxiliary channel off01b = Auxiliary channel on10b = Error Indicator or Not Used , depending on application11b = N...";
CM_ SG_ 2561015550 AuxiliaryIO91 "Auxiliary I/O #91: Identifies the current status of auxiliary input/output functions that are configured uniquely per application.00b = Auxiliary channel off01b = Auxiliary channel on10b = Error Indicator or Not Used , depending on application11b = N...";
CM_ SG_ 2561015550 AuxiliaryIO92 "Auxiliary I/O #92: Identifies the current status of auxiliary input/output functions that are configured uniquely per application.00b = Auxiliary channel off01b = Auxiliary channel on10b = Error Indicator or Not Used , depending on application11b = N...";
CM_ SG_ 2561015550 AuxiliaryIO93 "Auxiliary I/O #93: Identifies the current status of auxiliary input/output functions that are configured uniquely per application.00b = Auxiliary channel off01b = Auxiliary channel on10b = Error Indicator or Not Used , depending on application11b = N...";
CM_ SG_ 2561015550 AuxiliaryIO94 "Auxiliary I/O #94: Identifies the current status of auxiliary input/output functions that are configured uniquely per application.00b = Auxiliary channel off01b = Auxiliary channel on10b = Error Indicator or Not Used , depending on application11b = N...";
CM_ SG_ 2561015550 AuxiliaryIO95 "Auxiliary I/O #95: Identifies the current status of auxiliary input/output functions that are configured uniquely per application.00b = Auxiliary channel off01b = Auxiliary channel on10b = Error Indicator or Not Used , depending on application11b = N...";
CM_ SG_ 2561015550 AuxiliaryIO96 "Auxiliary I/O #96: Identifies the current status of auxiliary input/output functions that are configured uniquely per application.00b = Auxiliary channel off01b = Auxiliary channel on10b = Error Indicator or Not Used , depending on application11b = N...";
CM_ SG_ 2561015550 AuxiliaryIO97 "Auxiliary I/O #97: Identifies the current status of auxiliary input/output functions that are configured uniquely per application.00b = Auxiliary channel off01b = Auxiliary channel on10b = Error Indicator or Not Used , depending on application11b = N...";
CM_ SG_ 2561015550 AuxiliaryIO98 "Auxiliary I/O #98: Identifies the current status of auxiliary input/output functions that are configured uniquely per application.00b = Auxiliary channel off01b = Auxiliary channel on10b = Error Indicator or Not Used , depending on application11b = N...";
CM_ SG_ 2561015550 AuxiliaryIO99 "Auxiliary I/O #99: Identifies the current status of auxiliary input/output functions that are configured uniquely per application.00b = Auxiliary channel off01b = Auxiliary channel on10b = Error Indicator or Not Used , depending on application11b = N...";
CM_ BO_ 2561081086 "Auxiliary Input/Output Status 3";
CM_ SG_ 2561081086 AuxiliaryIO49 "Auxiliary I/O #49: Identifies the current status of auxiliary input/output functions that are configured uniquely per application.00b = Auxiliary channel off01b = Auxiliary channel on10b = Error Indicator or Not Used , depending on application11b = N...";
CM_ SG_ 2561081086 AuxiliaryIO50 "Auxiliary I/O #50: Identifies the current status of auxiliary input/output functions that are configured uniquely per application.00b = Auxiliary channel off01b = Auxiliary channel on10b = Error Indicator or Not Used , depending on application11b = N...";
CM_ SG_ 2561081086 AuxiliaryIO51 "Auxiliary I/O #51: Identifies the current status of auxiliary input/output functions that are configured uniquely per application.00b = Auxiliary channel off01b = Auxiliary channel on10b = Error Indicator or Not Used , depending on application11b = N...";
CM_ SG_ 2561081086 AuxiliaryIO52 "Auxiliary I/O #52: Identifies the current status of auxiliary input/output functions that are configured uniquely per application.00b = Auxiliary channel off01b = Auxiliary channel on10b = Error Indicator or Not Used , depending on application11b = N...";
CM_ SG_ 2561081086 AuxiliaryIO53 "Auxiliary I/O #53: Identifies the current status of auxiliary input/output functions that are configured uniquely per application.00b = Auxiliary channel off01b = Auxiliary channel on10b = Error Indicator or Not Used , depending on application11b = N...";
CM_ SG_ 2561081086 AuxiliaryIO54 "Auxiliary I/O #54: Identifies the current status of auxiliary input/output functions that are configured uniquely per application.00b = Auxiliary channel off01b = Auxiliary channel on10b = Error Indicator or Not Used , depending on application11b = N...";
CM_ SG_ 2561081086 AuxiliaryIO55 "Auxiliary I/O #55: Identifies the current status of auxiliary input/output functions that are configured uniquely per application.00b = Auxiliary channel off01b = Auxiliary channel on10b = Error Indicator or Not Used , depending on application11b = N...";
CM_ SG_ 2561081086 AuxiliaryIO56 "Auxiliary I/O #56: Identifies the current status of auxiliary input/output functions that are configured uniquely per application.00b = Auxiliary channel off01b = Auxiliary channel on10b = Error Indicator or Not Used , depending on application11b = N...";
CM_ SG_ 2561081086 AuxiliaryIO57 "Auxiliary I/O #57: Identifies the current status of auxiliary input/output functions that are configured uniquely per application.00b = Auxiliary channel off01b = Auxiliary channel on10b = Error Indicator or Not Used , depending on application11b = N...";
CM_ SG_ 2561081086 AuxiliaryIO58 "Auxiliary I/O #58: Identifies the current status of auxiliary input/output functions that are configured uniquely per application.00b = Auxiliary channel off01b = Auxiliary channel on10b = Error Indicator or Not Used , depending on application11b = N...";
CM_ SG_ 2561081086 AuxiliaryIO59 "Auxiliary I/O #59: Identifies the current status of auxiliary input/output functions that are configured uniquely per application.00b = Auxiliary channel off01b = Auxiliary channel on10b = Error Indicator or Not Used , depending on application11b = N...";
CM_ SG_ 2561081086 AuxiliaryIO60 "Auxiliary I/O #60: Identifies the current status of auxiliary input/output functions that are configured uniquely per application.00b = Auxiliary channel off01b = Auxiliary channel on10b = Error Indicator or Not Used , depending on application11b = N...";
CM_ SG_ 2561081086 AuxiliaryIO61 "Auxiliary I/O #61: Identifies the current status of auxiliary input/output functions that are configured uniquely per application.00b = Auxiliary channel off01b = Auxiliary channel on10b = Error Indicator or Not Used , depending on application11b = N...";
CM_ SG_ 2561081086 AuxiliaryIO62 "Auxiliary I/O #62: Identifies the current status of auxiliary input/output functions that are configured uniquely per application.00b = Auxiliary channel off01b = Auxiliary channel on10b = Error Indicator or Not Used , depending on application11b = N...";
CM_ SG_ 2561081086 AuxiliaryIO63 "Auxiliary I/O #63: Identifies the current status of auxiliary input/output functions that are configured uniquely per application.00b = Auxiliary channel off01b = Auxiliary channel on10b = Error Indicator or Not Used , depending on application11b = N...";
CM_ SG_ 2561081086 AuxiliaryIO64 "Auxiliary I/O #64: Identifies the current status of auxiliary input/output functions that are configured uniquely per application.00b = Auxiliary channel off01b = Auxiliary channel on10b = Error Indicator or Not Used , depending on application11b = N...";
CM_ SG_ 2561081086 AuxiliaryIO65 "Auxiliary I/O #65: Identifies the current status of auxiliary input/output functions that are configured uniquely per application.00b = Auxiliary channel off01b = Auxiliary channel on10b = Error Indicator or Not Used , depending on application11b = N...";
CM_ SG_ 2561081086 AuxiliaryIO66 "Auxiliary I/O #66: Identifies the current status of auxiliary input/output functions that are configured uniquely per application.00b = Auxiliary channel off01b = Auxiliary channel on10b = Error Indicator or Not Used , depending on application11b = N...";
CM_ SG_ 2561081086 AuxiliaryIO67 "Auxiliary I/O #67: Identifies the current status of auxiliary input/output functions that are configured uniquely per application.00b = Auxiliary channel off01b = Auxiliary channel on10b = Error Indicator or Not Used , depending on application11b = N...";
CM_ SG_ 2561081086 AuxiliaryIO68 "Auxiliary I/O #68: Identifies the current status of auxiliary input/output functions that are configured uniquely per application.00b = Auxiliary channel off01b = Auxiliary channel on10b = Error Indicator or Not Used , depending on application11b = N...";
CM_ SG_ 2561081086 AuxiliaryIO69 "Auxiliary I/O #69: Identifies the current status of auxiliary input/output functions that are configured uniquely per application.00b = Auxiliary channel off01b = Auxiliary channel on10b = Error Indicator or Not Used , depending on application11b = N...";
CM_ SG_ 2561081086 AuxiliaryIO70 "Auxiliary I/O #70: Identifies the current status of auxiliary input/output functions that are configured uniquely per application.00b = Auxiliary channel off01b = Auxiliary channel on10b = Error Indicator or Not Used , depending on application11b = N...";
CM_ SG_ 2561081086 AuxiliaryIO71 "Auxiliary I/O #71: Identifies the current status of auxiliary input/output functions that are configured uniquely per application.00b = Auxiliary channel off01b = Auxiliary channel on10b = Error Indicator or Not Used , depending on application11b = N...";
CM_ SG_ 2561081086 AuxiliaryIO72 "Auxiliary I/O #72: Identifies the current status of auxiliary input/output functions that are configured uniquely per application.00b = Auxiliary channel off01b = Auxiliary channel on10b = Error Indicator or Not Used , depending on application11b = N...";
CM_ SG_ 2561081086 AuxiliaryIO73 "Auxiliary I/O #73: Identifies the current status of auxiliary input/output functions that are configured uniquely per application.00b = Auxiliary channel off01b = Auxiliary channel on10b = Error Indicator or Not Used , depending on application11b = N...";
CM_ SG_ 2561081086 AuxiliaryIO74 "Auxiliary I/O #74: Identifies the current status of auxiliary input/output functions that are configured uniquely per application.00b = Auxiliary channel off01b = Auxiliary channel on10b = Error Indicator or Not Used , depending on application11b = N...";
CM_ SG_ 2561081086 AuxiliaryIO75 "Auxiliary I/O #75: Identifies the current status of auxiliary input/output functions that are configured uniquely per application.00b = Auxiliary channel off01b = Auxiliary channel on10b = Error Indicator or Not Used , depending on application11b = N...";
CM_ SG_ 2561081086 AuxiliaryIO76 "Auxiliary I/O #76: Identifies the current status of auxiliary input/output functions that are configured uniquely per application.00b = Auxiliary channel off01b = Auxiliary channel on10b = Error Indicator or Not Used , depending on application11b = N...";
CM_ SG_ 2561081086 AuxiliaryIO77 "Auxiliary I/O #77: Identifies the current status of auxiliary input/output functions that are configured uniquely per application.00b = Auxiliary channel off01b = Auxiliary channel on10b = Error Indicator or Not Used , depending on application11b = N...";
CM_ SG_ 2561081086 AuxiliaryIO78 "Auxiliary I/O #78: Identifies the current status of auxiliary input/output functions that are configured uniquely per application.00b = Auxiliary channel off01b = Auxiliary channel on10b = Error Indicator or Not Used , depending on application11b = N...";
CM_ SG_ 2561081086 AuxiliaryIO79 "Auxiliary I/O #79: Identifies the current status of auxiliary input/output functions that are configured uniquely per application.00b = Auxiliary channel off01b = Auxiliary channel on10b = Error Indicator or Not Used , depending on application11b = N...";
CM_ SG_ 2561081086 AuxiliaryIO80 "Auxiliary I/O #80: Identifies the current status of auxiliary input/output functions that are configured uniquely per application.00b = Auxiliary channel off01b = Auxiliary channel on10b = Error Indicator or Not Used , depending on application11b = N...";
CM_ BO_ 2561146622 "Auxiliary Input/Output Status 2";
CM_ SG_ 2561146622 AuxiliaryIO17 "Auxiliary I/O #17: Identifies the current status of auxiliary input/output functions that are configured uniquely per application.00b = Auxiliary channel off01b = Auxiliary channel on10b = Error Indicator or Not Used , depending on application11b = N...";
CM_ SG_ 2561146622 AuxiliaryIO18 "Auxiliary I/O #18: Identifies the current status of auxiliary input/output functions that are configured uniquely per application.00b = Auxiliary channel off01b = Auxiliary channel on10b = Error Indicator or Not Used , depending on application11b = N...";
CM_ SG_ 2561146622 AuxiliaryIO19 "Auxiliary I/O #19: Identifies the current status of auxiliary input/output functions that are configured uniquely per application.00b = Auxiliary channel off01b = Auxiliary channel on10b = Error Indicator or Not Used , depending on application11b = N...";
CM_ SG_ 2561146622 AuxiliaryIO20 "Auxiliary I/O #20: Identifies the current status of auxiliary input/output functions that are configured uniquely per application.00b = Auxiliary channel off01b = Auxiliary channel on10b = Error Indicator or Not Used , depending on application11b = N...";
CM_ SG_ 2561146622 AuxiliaryIO21 "Auxiliary I/O #21: Identifies the current status of auxiliary input/output functions that are configured uniquely per application.00b = Auxiliary channel off01b = Auxiliary channel on10b = Error Indicator or Not Used , depending on application11b = N...";
CM_ SG_ 2561146622 AuxiliaryIO22 "Auxiliary I/O #22: Identifies the current status of auxiliary input/output functions that are configured uniquely per application.00b = Auxiliary channel off01b = Auxiliary channel on10b = Error Indicator or Not Used , depending on application11b = N...";
CM_ SG_ 2561146622 AuxiliaryIO23 "Auxiliary I/O #23: Identifies the current status of auxiliary input/output functions that are configured uniquely per application.00b = Auxiliary channel off01b = Auxiliary channel on10b = Error Indicator or Not Used , depending on application11b = N...";
CM_ SG_ 2561146622 AuxiliaryIO24 "Auxiliary I/O #24: Identifies the current status of auxiliary input/output functions that are configured uniquely per application.00b = Auxiliary channel off01b = Auxiliary channel on10b = Error Indicator or Not Used , depending on application11b = N...";
CM_ SG_ 2561146622 AuxiliaryIO25 "Auxiliary I/O #25: Identifies the current status of auxiliary input/output functions that are configured uniquely per application.00b = Auxiliary channel off01b = Auxiliary channel on10b = Error Indicator or Not Used , depending on application11b = N...";
CM_ SG_ 2561146622 AuxiliaryIO26 "Auxiliary I/O #26: Identifies the current status of auxiliary input/output functions that are configured uniquely per application.00b = Auxiliary channel off01b = Auxiliary channel on10b = Error Indicator or Not Used , depending on application11b = N...";
CM_ SG_ 2561146622 AuxiliaryIO27 "Auxiliary I/O #27: Identifies the current status of auxiliary input/output functions that are configured uniquely per application.00b = Auxiliary channel off01b = Auxiliary channel on10b = Error Indicator or Not Used , depending on application11b = N...";
CM_ SG_ 2561146622 AuxiliaryIO28 "Auxiliary I/O #28: Identifies the current status of auxiliary input/output functions that are configured uniquely per application.00b = Auxiliary channel off01b = Auxiliary channel on10b = Error Indicator or Not Used , depending on application11b = N...";
CM_ SG_ 2561146622 AuxiliaryIO29 "Auxiliary I/O #29: Identifies the current status of auxiliary input/output functions that are configured uniquely per application.00b = Auxiliary channel off01b = Auxiliary channel on10b = Error Indicator or Not Used , depending on application11b = N...";
CM_ SG_ 2561146622 AuxiliaryIO30 "Auxiliary I/O #30: Identifies the current status of auxiliary input/output functions that are configured uniquely per application.00b = Auxiliary channel off01b = Auxiliary channel on10b = Error Indicator or Not Used , depending on application11b = N...";
CM_ SG_ 2561146622 AuxiliaryIO31 "Auxiliary I/O #31: Identifies the current status of auxiliary input/output functions that are configured uniquely per application.00b = Auxiliary channel off01b = Auxiliary channel on10b = Error Indicator or Not Used , depending on application11b = N...";
CM_ SG_ 2561146622 AuxiliaryIO32 "Auxiliary I/O #32: Identifies the current status of auxiliary input/output functions that are configured uniquely per application.00b = Auxiliary channel off01b = Auxiliary channel on10b = Error Indicator or Not Used , depending on application11b = N...";
CM_ SG_ 2561146622 AuxiliaryIO33 "Auxiliary I/O #33: Identifies the current status of auxiliary input/output functions that are configured uniquely per application.00b = Auxiliary channel off01b = Auxiliary channel on10b = Error Indicator or Not Used , depending on application11b = N...";
CM_ SG_ 2561146622 AuxiliaryIO34 "Auxiliary I/O #34: Identifies the current status of auxiliary input/output functions that are configured uniquely per application.00b = Auxiliary channel off01b = Auxiliary channel on10b = Error Indicator or Not Used , depending on application11b = N...";
CM_ SG_ 2561146622 AuxiliaryIO35 "Auxiliary I/O #35: Identifies the current status of auxiliary input/output functions that are configured uniquely per application.00b = Auxiliary channel off01b = Auxiliary channel on10b = Error Indicator or Not Used , depending on application11b = N...";
CM_ SG_ 2561146622 AuxiliaryIO36 "Auxiliary I/O #36: Identifies the current status of auxiliary input/output functions that are configured uniquely per application.00b = Auxiliary channel off01b = Auxiliary channel on10b = Error Indicator or Not Used , depending on application11b = N...";
CM_ SG_ 2561146622 AuxiliaryIO37 "Auxiliary I/O #37: Identifies the current status of auxiliary input/output functions that are configured uniquely per application.00b = Auxiliary channel off01b = Auxiliary channel on10b = Error Indicator or Not Used , depending on application11b = N...";
CM_ SG_ 2561146622 AuxiliaryIO38 "Auxiliary I/O #38: Identifies the current status of auxiliary input/output functions that are configured uniquely per application.00b = Auxiliary channel off01b = Auxiliary channel on10b = Error Indicator or Not Used , depending on application11b = N...";
CM_ SG_ 2561146622 AuxiliaryIO39 "Auxiliary I/O #39: Identifies the current status of auxiliary input/output functions that are configured uniquely per application.00b = Auxiliary channel off01b = Auxiliary channel on10b = Error Indicator or Not Used , depending on application11b = N...";
CM_ SG_ 2561146622 AuxiliaryIO40 "Auxiliary I/O #40: Identifies the current status of auxiliary input/output functions that are configured uniquely per application.00b = Auxiliary channel off01b = Auxiliary channel on10b = Error Indicator or Not Used , depending on application11b = N...";
CM_ SG_ 2561146622 AuxiliaryIO41 "Auxiliary I/O #41: Identifies the current status of auxiliary input/output functions that are configured uniquely per application.00b = Auxiliary channel off01b = Auxiliary channel on10b = Error Indicator or Not Used , depending on application11b = N...";
CM_ SG_ 2561146622 AuxiliaryIO42 "Auxiliary I/O #42: Identifies the current status of auxiliary input/output functions that are configured uniquely per application.00b = Auxiliary channel off01b = Auxiliary channel on10b = Error Indicator or Not Used , depending on application11b = N...";
CM_ SG_ 2561146622 AuxiliaryIO43 "Auxiliary I/O #43: Identifies the current status of auxiliary input/output functions that are configured uniquely per application.00b = Auxiliary channel off01b = Auxiliary channel on10b = Error Indicator or Not Used , depending on application11b = N...";
CM_ SG_ 2561146622 AuxiliaryIO44 "Auxiliary I/O #44: Identifies the current status of auxiliary input/output functions that are configured uniquely per application.00b = Auxiliary channel off01b = Auxiliary channel on10b = Error Indicator or Not Used , depending on application11b = N...";
CM_ SG_ 2561146622 AuxiliaryIO45 "Auxiliary I/O #45: Identifies the current status of auxiliary input/output functions that are configured uniquely per application.00b = Auxiliary channel off01b = Auxiliary channel on10b = Error Indicator or Not Used , depending on application11b = N...";
CM_ SG_ 2561146622 AuxiliaryIO46 "Auxiliary I/O #46: Identifies the current status of auxiliary input/output functions that are configured uniquely per application.00b = Auxiliary channel off01b = Auxiliary channel on10b = Error Indicator or Not Used , depending on application11b = N...";
CM_ SG_ 2561146622 AuxiliaryIO47 "Auxiliary I/O #47: Identifies the current status of auxiliary input/output functions that are configured uniquely per application.00b = Auxiliary channel off01b = Auxiliary channel on10b = Error Indicator or Not Used , depending on application11b = N...";
CM_ SG_ 2561146622 AuxiliaryIO48 "Auxiliary I/O #48: Identifies the current status of auxiliary input/output functions that are configured uniquely per application.00b = Auxiliary channel off01b = Auxiliary channel on10b = Error Indicator or Not Used , depending on application11b = N...";
CM_ BO_ 2561212158 "Text Display";
CM_ SG_ 2561212158 TextDisplayIndex "Text Display Index: Used for overwriting consecutive bytes of a displayed string when byte 1 Text Display Instructions state is set for overwrite substring mode.  When used, this byte declares where in the text string that the new text will start ove...";
CM_ SG_ 2561212158 TextDisplayInstructions "Text Display Instructions: This parameter describes the status for the display how to show the information.0000b = Clear display - The displayed information should be deleted or not displayed any more.0001b = Hold display - The presently displayed in...";
CM_ BO_ 2561277694 "Forward Lane Image Command";
CM_ SG_ 2561277694 CurrentRegion "Current Region: Command sent to forward imager which specifies the operator's desired region to assist with object recognition.Message shall use the 2-character string country codes in ISO 3166-1 alpha-2.Typical examples from ISO 3166-1 alpha-2 are:F...";
CM_ SG_ 2561277694 CurrentSubRegion "Current Sub-Region: Command sent to all Forward Imager which specifies the operator's desired sub-region to assist with object recognition.This signal will be dependent on Current Region and shall use the 3-character string subdivision codes in ISO 3...";
CM_ SG_ 2561277694 LnDprtrWrnngEnlCmmnd "Lane Departure Warning Enable Command: Command to enable/disable Lane Departure Indication00b = Disable Lane Departure Warning01b = Enable Lane Departure Warning10b = Reserved11b = Don´t care";
CM_ SG_ 2561277694 LaneKeepingAssistEnableCommand "Lane Keeping Assist Enable Command: Command to enable/disable lane keeping assist system.00b = Disable lane keeping assist01b = Enable lane keeping assist10b = Reserved11b = Don´t care";
CM_ SG_ 2561277694 LaneCenteringEnableCommand "Lane Centering Enable Command: Command to enable/disable lane centering system.00b = Disable lane centering01b = Enable lane centering10b = Reserved11b = Don´t care";
CM_ SG_ 2561277694 RqstdAtvStrngDrvrPrfrnMd "Requested Active Steering Driver Preference Mode: The requested active steering mode to the active steering system from the operators interface. This parameter is the driver's request, the state is shown in SPN 9757.000b = Requested Active Steering M...";
CM_ BO_ 2561605374 "Tire Pressure Reference Setting";
CM_ SG_ 2561605374 ReferenceTirePressureSetting "Reference Tire Pressure Setting: Reference value of the tire pressure setting as basis for the tire pressure monitoring";
CM_ SG_ 2561605374 TireLocation "Tire Location: Identifies which tire is associated with the parametric data in this PG.The low order 4 bits represent a position number, counting left to right when facing in the direction of normal vehicle travel (forward).The high order 4 bits repr...";
CM_ BO_ 2563768062 "Continuous Torque & Speed Limit Request";
CM_ SG_ 2563768062 EngnSpdLmtRqstMnmmCntns "Engine Speed Limit Request - Minimum Continuous: Requested minimum continuous engine speed";
CM_ SG_ 2563768062 EngnSpdLmtRqstMxmmCntns "Engine Speed Limit Request - Maximum Continuous: Requested maximum continuous engine speed";
CM_ SG_ 2563768062 EngnTrqLmtRqstMnmmCntns "Engine Torque Limit Request - Minimum Continuous: Requested minimum continuous engine torque (operating range: 0 to 125%)";
CM_ SG_ 2563768062 EngnTrqLmtRqstMxmmCntns "Engine Torque Limit Request - Maximum Continuous: Requested maximum continuous engine torque (operating range: 0 to 125%)";
CM_ SG_ 2563768062 MnmmCntnsRtrdrSpdLmtRqst "Minimum Continuous Retarder Speed Limit Request: Requested minimum continuous retarder speed";
CM_ SG_ 2563768062 MnmmCntnsRtrdrTrqLmtRqst "Minimum Continuous Retarder Torque Limit Request: Requested minimum continuous retarder torque (operating range: -125 to 0%)";
CM_ SG_ 2563768062 MxmmCntnsRtrdrSpdLmtRqst "Maximum Continuous Retarder Speed Limit Request: Requested maximum continuous retarder speed";
CM_ SG_ 2563768062 MxmmCntnsRtrdrTrqLmtRqst "Maximum Continuous Retarder Torque Limit Request: Requested maximum continuous retarder torque (operating range: -125 to 0%)";
CM_ BO_ 2563833598 "Cab Illumination Message";
CM_ SG_ 2563833598 IlluminationBrightnessPercent "Illumination Brightness Percent: Commanded backlight brightness level for all cab displays.  Note:  If a separate device is used to independently control the switch backlight brightness level, see SPN 5532.";
CM_ SG_ 2563833598 SwthBklghtIllmntnBrghtnssPrnt "Switch Backlight Illumination Brightness Percent: Commanded switch backlight brightness level for all operator control switches.  This is separate from the cab display illumination Brightness Percent parameter.Note:  If a single device is used to con...";
CM_ SG_ 2563833598 SwthIndtnIllmntnBrghtnssPrnt "Switch Indication Illumination Brightness Percent: Commanded switch indication illumination brightness level for all operator control switches. This is separate from the cab display illumination Brightness Percent parameter.Note: If a single device i...";
CM_ SG_ 2563833598 OprtrDsrdDsplMdCmmnd1 "Operator Desired Display Mode Command 1: The desired mode of the operator's display.  Allows the operator to select different day/night modes and broadcast desired setting to other displays in the system.  Display modes may include brightness, color,...";
CM_ SG_ 2563833598 OprtrDsrdDsplMdCmmnd2 "Operator Desired Display Mode Command 2: The desired mode of the operator's display.  Allows the operator to select different day/night modes and broadcast desired setting to other displays in the system.  Display modes may include brightness, color,...";
CM_ BO_ 2564161278 "Time/Date Adjust";
CM_ SG_ 2564161278 Adjustday "Adjust day: The day component for setting the current calendar date.  This should be reported as the day component of the current date according to the calendar date standard indicated with the Local Hour Offset parameter (SPN 1602).  The calendar da...";
CM_ SG_ 2564161278 Adjusthours "Adjust hours: The hours component for setting the current time of day.  This should be reported as the hours component of the current time according to the time of day standard indicated with the Local Hour Offset parameter (SPN 1602).  The time of d...";
CM_ SG_ 2564161278 Adjustlocalhouroffset "Adjust local hour offset: The hour component for setting the offset between the UTC (Universal Time Coordinate) time and date and a the local time zone time and date.  This is the number of minutes to add to UTC, a.k.a. GMT, time and date to convert ...";
CM_ SG_ 2564161278 Adjustlocalminuteoffset "Adjust local minute offset: The minute component for setting the offset between the UTC (Universal Time Coordinate) time and date and a the local time zone time and date.  This is the number of minutes to add to UTC, a.k.a. GMT, time and date to conv...";
CM_ SG_ 2564161278 Adjustminutes "Adjust minutes: The minutes component for setting the current time of day.  This should be reported as the minutes component of the current time according to the time of day standard indicated with the Local Hour Offset parameter (SPN 1602).  The tim...";
CM_ SG_ 2564161278 Adjustmonth "Adjust month: The month component for setting the current calendar date.  This should be reported as the month component of the current date according to the calendar date standard indicated with the Local Hour Offset parameter (SPN 1602).  The calen...";
CM_ SG_ 2564161278 Adjustseconds "Adjust seconds: The seconds component for setting the current time of day.  This should be reported as the seconds component of the current time according to the time of day standard indicated with the Local Hour Offset parameter (SPN 1602).  The tim...";
CM_ SG_ 2564161278 Adjustyear "Adjust year: The year component for setting the current calendar date.  This should be reported as the year component of the current date according to the calendar date standard indicated with the Local Hour Offset parameter (SPN 1602).  The calendar...";
CM_ BO_ 2564882174 "Cab Message 1";
CM_ SG_ 2564882174 AftrtrtmntRgnrtnFrSwth "Aftertreatment Regeneration Force Switch: Indicates the state of a switch available to the operator that forces aftertreatment regeneration. 00b = not active 01b = active 10b = error 11b = not available  This SP would be not active when aftertreatmen...";
CM_ SG_ 2564882174 AftrtrtmntRgnrtnInhtSwth "Aftertreatment Regeneration Inhibit Switch: Indicates the state of a switch available to the operator that inhibits aftertreatment regeneration. 00b = not active 01b = active 10b = error 11b = not available  This SP would be not active when aftertrea...";
CM_ SG_ 2564882174 AtmtGrShftngEnlSwth "Automatic Gear Shifting Enable Switch: Indicates that automated gear shifting is enabled via a switch00b = Automated Gear Shifting is disabled01b = Automated Gear Shifting is enabled10b = Error11b = Not available";
CM_ SG_ 2564882174 AuxiliaryHeaterModeRequest "Auxiliary Heater Mode Request: Request to activate the auxiliary heater.0000b = De-activate auxiliary heater0001b = Off due to ADR per European Regulations for Transport of hazardous materials0010b = Economy mode0011b = Normal mode0100b = Heater pump...";
CM_ SG_ 2564882174 AxlrHtrClntPmpRqst "Auxiliary Heater Coolant Pump Request: Indicates whether to activate the auxiliary heater coolant water pump.00b = Deactivate water pump01b = Activate water pump10b = Reserved11b = Don't care/take no action";
CM_ SG_ 2564882174 BatteryMainSwitchHoldRequest "Battery Main Switch Hold Request: Request to hold the battery main switch.00b = Release Battery Main Switch01b = Hold Battery Main Switch10b = undefined11b = Don't care/take no action";
CM_ SG_ 2564882174 CabInteriorTemperatureCommand "Cab Interior Temperature Command: Parameter used to command a certain cab interior temperature.Note: See also SPN 170.  SPN 1662 is an additional diagnostic SP associated with cab temperature.";
CM_ SG_ 2564882174 EngineFan1RequestedPercentSpeed "Engine Fan 1 Requested Percent Speed: Fan speed of the first or only fan in the system as a ratio of the actual fan drive (current speed) to the fully engaged fan drive (maximum fan speed). A two state fan (off/on) will use 0% and 100% respectively. ...";
CM_ SG_ 2564882174 EngnAtmtStrtEnlSwth "Engine Automatic Start Enable Switch: Switch signal which enables the idle management system to be enabled. When this system is enabled with the engine in an idle mode and safe operating conditions existing, then the engine may be started or stopped ...";
CM_ SG_ 2564882174 OperatorSeatDirectionSwitch "Operator Seat Direction Switch: Senses whether the operator seat is in the forward driving position00b = Operator seat not facing forward01b = Operator seat is facing forward10b = Error11b = Not Available";
CM_ SG_ 2564882174 ParkBrakeCommand "Park Brake Command: Request by a secondary device to command the Park Brake.  The Park Brake controller should treat this as a request and should apply the Park Brake as determined by the controller. Feedback of the park brake actuation may utilize S...";
CM_ SG_ 2564882174 RequestCabZoneHeating "Request Cab Zone Heating: Request to activate cab zone heating.00b = Do not heat cab engine zone01b = Heat cab zone10b = Reserved11b = Don't care/take no action";
CM_ SG_ 2564882174 RequestEngineZoneHeating "Request Engine Zone Heating: Request to activate engine zone heating.00b = Do not heat engine zone01b = Heat engine zone10b = Reserved11b = Don't care/take no action";
CM_ SG_ 2564882174 SeatBeltSwitch "Seat Belt Switch: State of switch used to determine if Seat Belt is buckled00b = NOT Buckled01b = OK - Seat Belt is buckled10b = Error - Switch state cannot be determined11b = Not Available";
CM_ SG_ 2564882174 SltdMxmmVhlSpdLmt "Selected Maximum Vehicle Speed Limit: User selected maximum vehicle speed.  If one is selected, then this SP must equal one of the maximum vehicle speeds #1-#7 from PGN 64997 - Maximum Vehicle Speed Limit Status. If different maximum vehicle speed re...";
CM_ SG_ 2564882174 VhlLmtngSpdGvrnrDrmntSwth "Vehicle Limiting Speed Governor Decrement Switch: Switch signal which decreases the Vehicle Limiting Speed Governor (VLSG).00b = Switch in the off state01b = Switch in the on state - decrease10b = Error11b = Not available";
CM_ SG_ 2564882174 VhlLmtngSpdGvrnrEnlSwth "Vehicle Limiting Speed Governor Enable Switch: Switch signal which enables the Vehicle Limiting Speed Governor (VLSG) such that the vehicle speed may be either increased or decreased when the engine is off idle.00b = Switch disabled01b = Switched ena...";
CM_ SG_ 2564882174 VhlLmtngSpdGvrnrInrmntSwth "Vehicle Limiting Speed Governor Increment Switch: Switch signal which increases the Vehicle Limiting Speed Governor (VLSG).00b = Switch in the off state01b = Switch in the on state - increase10b = Error11b = Not available";
CM_ BO_ 2565865982 "Electronic Brake Controller 1";
CM_ SG_ 2565865982 ABSEBSAmrWrnngSgnlPwrdVhl "ABS/EBS Amber Warning Signal (Powered Vehicle): This parameter commands the ABS/EBS amber/yellow optical warning signal00b = Off01b = On10b = Reserved11b = Take no action";
CM_ SG_ 2565865982 ABSFullyOperational "ABS Fully Operational: Signal which indicates whether an ABS system is fully operational or whether its functionality is reduced by a defect or by an intended action (e.g., by activation of an ABS-off-road switch or during special diagnostic procedur...";
CM_ SG_ 2565865982 ABSOffroadSwitch "ABS Off-road Switch: Switch signal which indicates the position of the ABS off-road switch.00b = ABS off-road switch passive01b = ABS off-road switch active10b = Error11b = Not available";
CM_ SG_ 2565865982 AcceleratorInterlockSwitch "Accelerator Interlock Switch: Switch signal used to disable the accelerator and remote accelerator inputs, causing the engine to return to idle.00b = Off01b = On10b = Error11b = Not available";
CM_ SG_ 2565865982 AntiLockBrakingABSActive "Anti-Lock Braking (ABS) Active: State signal which indicates that the ABS is active.  The signal is set active when wheel brake pressure actually starts to be modulated by ABS and is reset to passive when all wheels are in a stable condition for a ce...";
CM_ SG_ 2565865982 ASRBrakeControlActive "ASR Brake Control Active: State signal which indicates that ASR brake control is active. Active means that ASR actually controls wheel brake pressure at one or more wheels of the driven axle(s).00b = ASR brake control passive but installed01b = ASR b...";
CM_ SG_ 2565865982 ASREngineControlActive "ASR Engine Control Active: State signal which indicates that ASR engine control has been commanded to be active. Active means that ASR actually tries to control the engine. This state signal is independent of other control commands to the engine (e.g...";
CM_ SG_ 2565865982 ASRHillHolderSwitch "ASR Hill Holder Switch: Switch signal which indicates the position of the ASR hill holder switch.00b = ASR hill holder switch passive01b = ASR hill holder switch active10b = Error11b = Not available";
CM_ SG_ 2565865982 ASROffroadSwitch "ASR Off-road Switch: Switch signal which indicates the position of the ASR off-road switch.00b = ASR off-road switch passive01b = ASR off-road switch active10b = Error11b = Not available";
CM_ SG_ 2565865982 ATCASRInformationSignal "ATC/ASR Information Signal: This parameter commands the ATC/ASR driver information signal, for example a dash lamp.00b = Off01b = On 10b = Reserved11b = Take no action";
CM_ SG_ 2565865982 BrakePedalPosition "Brake Pedal Position: Ratio of brake pedal position to maximum pedal position.  Used for electric brake applications. 0% means no braking. Also when there are two brake pedals on the machine (Left Brake Pedal Position SPN 3033 and Right Brake Pedal P...";
CM_ SG_ 2565865982 EBSBrakeSwitch "EBS Brake Switch: Switch signal which indicates that the brake pedal is being pressed.  The EBS brake switch is independent of the brake light switch and has no provisions for external connections.00b = Brake pedal is not being pressed01b = Brake ped...";
CM_ SG_ 2565865982 EBSRedWarningSignal "EBS Red Warning Signal: This parameter commands the EBS red optical warning signal00b = Off01b = On10b = Reserved11b = Take no action";
CM_ SG_ 2565865982 EngineAuxiliaryShutdownSwitch "Engine Auxiliary Shutdown Switch: Switch signal which requests that all engine fueling stop.00b = Off01b = On10b = Error11b = Not available";
CM_ SG_ 2565865982 EngineDerateSwitch "Engine Derate Switch: Switch signal used to activate the torque limiting feature of the engine.  The specific nature of torque limiting should be verified with the manufacturer.00b = Off01b = On10b = Error11b = Not available";
CM_ SG_ 2565865982 EngineRetarderSelection "Engine Retarder Selection: The position of the operator controlled selector, expressed as a percentage and determined by the ratio of the current position of the selector to its maximum possible position. Zero percent means no braking torque is reque...";
CM_ SG_ 2565865982 Haltbrakeswitch "Halt brake switch: Switch signal which indicates the position of the halt brake switch.00b = Halt brake switch passive01b = Halt brake switch active10b = Error11b = Not available";
CM_ SG_ 2565865982 RailroadModeSwitch "Railroad Mode Switch: Switch signal which indicates the position of the Railroad mode switch.00b = Railroad mode switch passive (City/Highway mode)01b = Railroad mode switch active (Railroad mode)10b = Error11b = Not availableNote:  This switch signa...";
CM_ SG_ 2565865982 RemoteAcceleratorEnableSwitch "Remote Accelerator Enable Switch: Switch signal which indicates that the remote accelerator has been enabled and controls the engine.  00b = Off01b = On10b = Error11b = Not availableNOTE—The accelerator interlock switch (see SPN 972) must be disabled...";
CM_ SG_ 2565865982 SrAddrssfCntrllngDvfrBrkCntrl "Source Address of Controlling Device for Brake Control: The source address of the SAE J1939 device currently controlling the brake system. Its value may be the source address of the ECU transmitting the message (which means that no external SAE J1939...";
CM_ SG_ 2565865982 TractionControlOverrideSwitch "Traction Control Override Switch: Switch signal which indicates the position of the traction control override switch.  The traction control override signal disables the automatic traction control function allowing the wheels to spin.00b = Off01b = On...";
CM_ SG_ 2565865982 TrailerABSStatus "Trailer ABS Status: State signal which indicates that ABS in the trailer is actively controlling the brakes.  A message is sent to the tractor from the trailer (i.e. by PLC). The receiving device in the tractor transfers this information to the J1939...";
CM_ SG_ 2565865982 TrtrMntdTrlrABSWrnngSgnl "Tractor-Mounted Trailer ABS Warning Signal: This parameter commands the tractor-mounted trailer ABS optical warning signal.00b = Off01b = On 10b = Reserved11b = Take no action";
CM_ BO_ 2565867006 "Electronic Transmission Controller 2";
CM_ SG_ 2565867006 TransmissionActualGearRatio "Transmission Actual Gear Ratio: Actual ratio of input shaft speed to output shaft speed.";
CM_ SG_ 2565867006 TransmissionCurrentGear "Transmission Current Gear: The gear currently engaged in the transmission or the last gear engaged while the transmission is in the process of shifting to the new or selected gear.  Transitions toward a destination gear will not be indicated.  Once t...";
CM_ SG_ 2565867006 TransmissionCurrentRange "Transmission Current Range: Range currently being commanded by the transmission control system. Characters may include P, Rx, Rx-1...R2, R1, R, Nx, Nx-1...N2, N1, N, D, D1, D2..., Dx, L, L1, L2..., Lx-1, 1, 2, 3,... If only one displayed character is...";
CM_ SG_ 2565867006 TransmissionRequestedRange "Transmission Requested Range: Range selected by the operator.  Characters may include P, Rx, Rx-1...R2, R1, R, Nx, Nx-1...N2, N1, N, D, D1, D2..., Dx, L, L1, L2..., Lx-1, 1, 2, 3,...  If only one displayed character is required, the second character ...";
CM_ SG_ 2565867006 TransmissionSelectedGear "Transmission Selected Gear: The gear that the transmission will attempt to achieve during the current shift if a shift is in progress, or the next shift if one is pending (i.e., waiting for torque reduction to initiate the shift).Negative values are ...";
CM_ BO_ 2565867262 "Electronic Axle Controller 1";
CM_ SG_ 2565867262 DffrntlLkSttCntrlFrnt "Differential Lock State - Central Front: State used which indicates the condition of the central front differential lock.  The differential locks are located as defined in figure SPN564_A.00b = Differential lock disengaged01b = Differential lock enga...";
CM_ SG_ 2565867262 DffrntlLkSttCntrlRr "Differential Lock State - Central Rear: State used which indicates the condition of the central rear differential lock.  The differential locks are located as defined in figure SPN564_A.00b = Differential lock disengaged01b = Differential lock engage...";
CM_ SG_ 2565867262 DifferentialLockStateCentral "Differential Lock State - Central: State used which indicates the condition of the central differential lock.  The differential locks are located as defined in attached figure SPN564_A.00b = Differential lock disengaged01b = Differential lock engaged...";
CM_ SG_ 2565867262 DifferentialLockStateFrontAxle1 "Differential Lock State - Front Axle 1: State used which indicates the condition of the front axle 1 differential lock.  The differential locks are located as defined in figure SPN564_A.00b = Differential lock disengaged01b = Differential lock engage...";
CM_ SG_ 2565867262 DifferentialLockStateFrontAxle2 "Differential Lock State - Front Axle 2: State used which indicates the condition of the front axle 2 differential lock. The differential locks are located as defined in figure SPN 564_A.00b = Differential lock disengaged01b = Differential lock engage...";
CM_ SG_ 2565867262 DifferentialLockStateRearAxle1 "Differential Lock State - Rear Axle 1: State used which indicates the condition of the rear axle 1 differential lock.  The differential locks are located as defined in figure SPN 564_A.00b = Differential lock disengaged01b = Differential lock engaged...";
CM_ SG_ 2565867262 DifferentialLockStateRearAxle2 "Differential Lock State - Rear Axle 2: State used which indicates the condition of the rear axle 2 differential lock.  The differential locks are located as defined in figure SPN 564_A.00b = Differential lock disengaged01b = Differential lock engaged...";
CM_ SG_ 2565867262 DifferentialLockStateRearAxle3 "Differential Lock State - Rear Axle 3: State used which indicates the condition of the rear axle 3 differential lock. The differential locks are located as defined in figure SPN 564_A.00b = Differential lock disengaged01b = Differential lock engaged1...";
CM_ SG_ 2565867262 Frontaxlegroupengagementstatus "Front axle group engagement status: Front axle group engagement status 00b = front axle group disengaged 01b = front axle group engaged10b = error11b = not available";
CM_ SG_ 2565867262 Location "Location: To identify to which of several similar devices (such as tires or fuel tanks) the information applies.The low order 4 bits represent a position number, counting left to right when facing in the direction of normal vehicle travel (forward).T...";
CM_ SG_ 2565867262 Rearaxlegroupengagementstatus "Rear axle group engagement status: Rear axle group engagement status00b = rear axle group disengaged 01b = rear axle group engaged10b = error11b = not available";
CM_ SG_ 2565867262 DogClutchRearAxle2 "Dog Clutch Rear Axle 2: Status of the Dog Clutch Rear Axle 2.00b = Dog Clutch Rear Axle 2 Disengaged01b = Dog Clutch Rear Axle 2 Engaged10b = Error11b = Not Available";
CM_ BO_ 2565867774 "Hydraulic Pressure Governor Info";
CM_ SG_ 2565867774 EngnHdrlPrssrGvrnrMdIndtr "Engine Hydraulic Pressure Governor Mode Indicator: Mode for governor operation is hydraulic pressure control.00b = Disabled01b = Enabled10b = Error Indicator11b = Not Available";
CM_ SG_ 2565867774 EngnHdrlPrssrGvrnrSwth "Engine Hydraulic Pressure Governor Switch: Switch that sets the  mode of hydraulic governor00b = Pressure Mode Inactive01b = Pressure Mode Active10b = Error Indicator11b = Not Available";
CM_ SG_ 2565867774 FireApparatusPumpEngagement "Fire Apparatus Pump Engagement: The measured status of the pump used to provide water in fire fighting apparatus for distribution of water through water cannons or fire hoses.00b = Pump not engaged01b = Pump engaged10b = Error11b = Not available or n...";
CM_ SG_ 2565867774 FrApprtsOkTPmpIntrlk "Fire Apparatus Okay To Pump Interlock: The measured state of the Okay To Pump interlock of the fire apparatus.00b = Okay to Pump Interlock Inactive01b = Okay to Pump Interlock Active10b = Error11b = Not AvailableNote: Okay to Pump is incorporated int...";
CM_ SG_ 2565867774 HdrlDshrgPrssrStPnt "Hydraulic Discharge Pressure Set Point: Hydraulic pressure governing system discharge pressure set point.";
CM_ SG_ 2565867774 HdrlPrssrGvrnrDrsSwth "Hydraulic Pressure Governor Decrease Switch: Switch that commands hydraulic pressure governor to decrease engine rpm resulting in expected decrease of hydraulic discharge pressure.00b = Decrease Switch Inactive01b = Decrease Switch Active10b = Error1...";
CM_ SG_ 2565867774 HdrlPrssrGvrnrIdlSwth "Hydraulic Pressure Governor Idle Switch: Switch that commands hydraulic pressure governor to decrease engine rpm to its idle position.00b = Idle Switch Inactive01b = Idle Switch Active10b = Error11b = Not available";
CM_ SG_ 2565867774 HdrlPrssrGvrnrInrsSwth "Hydraulic Pressure Governor Increase Switch: Switch that commands hydraulic pressure governor to increase engine rpm resulting in expected increase of hydraulic discharge pressure.00b = Increase Switch Inactive01b = Increase Switch Active10b = Error1...";
CM_ SG_ 2565867774 HdrlPrssrGvrnrPrstSwth "Hydraulic Pressure Governor Preset Switch: Switch that commands hydraulic pressure governor to increase or decrease engine rpm to achieve a predefined discharge pressure.00b = Preset Switch Inactive01b = Preset Switch Active10b = Error11b = Not avail...";
CM_ SG_ 2565867774 HydraulicIntakePressure "Hydraulic Intake Pressure: Hydraulic pressure measured at the intake of the hydraulic pump.";
CM_ SG_ 2565867774 HydraulicPressure "Hydraulic Pressure: Hydraulic pressure measured at the output of the hydraulic pump.";
CM_ BO_ 2565868030 "Vehicle Dynamic Stability Control 2";
CM_ SG_ 2565868030 LateralAcceleration "Lateral Acceleration: Indicates a lateral acceleration of the vehicle (the component of vehicle acceleration vector along the Y-axis). A positive lateral acceleration signal results when the vehicle is accelerated to the left.  This parameter is defi...";
CM_ SG_ 2565868030 LongitudinalAcceleration "Longitudinal Acceleration: Indicates the longitudinal acceleration of the vehicle. A positive longitudinal acceleration signal results when the vehicle speed increases, regardless of driving the vehicle forward or backward.  This parameter is applica...";
CM_ SG_ 2565868030 SteeringWheelAngle "Steering Wheel Angle: The main operator`s steering wheel angle (on the steering column, not the actual wheel angle).  The vehicle being steered to the left (counterclockwise) results in a positive steering wheel angle.  This is the yaw angle of the s...";
CM_ SG_ 2565868030 SteeringWheelAngleSensorType "Steering Wheel Angle Sensor Type: Indicates whether the steering wheel angle sensor is capable of absolute measuring of the number of steering wheel turns or not (relative measuring to position at ignition on).00b = Relative measuring principle01b = ...";
CM_ SG_ 2565868030 SteeringWheelTurnCounter "Steering Wheel Turn Counter: Indicates number of steering wheel turns, absolute position or relative position at ignition on. Positive values indicate left turns.";
CM_ SG_ 2565868030 YawRate "Yaw Rate: Indicates the rate of rotation about the vertical axis (i.e. the z-axis).  A positive yaw rate signal results when the vehicle turns counter-clockwise.   This parameter is defined according to a Z-Up axis system and the sign of the value is...";
CM_ BO_ 2565868542 "Electronic Steering Control";
CM_ SG_ 2565868542 ActualInnerwheelsteeringangle "Actual Inner wheel steering angle: Signal which indicates the actual inner wheel steering angle.  The steering angle is the angle of wheel turn relative to the vehicle x-axis (yaw angle of inner wheel). See Figure SPN2927_A for explanation of positiv...";
CM_ SG_ 2565868542 AxleLocation "Axle Location: To identify to which of several similar devices (such as tires or fuel tanks) the information applies.The low order 4 bits represent a position number, counting left to right when facing in the direction of normal vehicle travel (forwa...";
CM_ SG_ 2565868542 StatusofSteeringAxle "Status of Steering Axle: A signal which indicates different states of the steering axle0000b = Axle steering not active (adhesion steering)0001b = Axle steering active0010b = Axle centered0011b = Axle centered, because of an error0100b = Axle not act...";
CM_ SG_ 2565868542 SteeringType "Steering Type: Indicates the different types of steering systems (ref. ECE Regulation 79 paragraph 2.5)0000b = Main steering system0001b = Auxiliary steering equipment0010b to 1110b = Reserved for Assignment by SAE1111b = Not Available0000b    Main s...";
CM_ SG_ 2565868542 StrlLftAxlLwrngInht "Steerable Lift Axle Lowering Inhibit: A signal which indicates if lowering of lifted axle is allowed or inhibited.00b = Lowering allowed01b = Lowering inhibited10b = Reserved11b = Not available";
CM_ SG_ 2565868542 TypeofSteeringForces "Type of Steering Forces: Type of Steering Forces (Ref. ECE Regulation 79 paragraph 2.5)0000b = Manual steering equipment0001b = Power assisted steering equipment0010b = Full power steering equipment0011b = Self tracking steering equipment0100b to 111...";
CM_ SG_ 2565868542 TypeofSteeringTransmission "Type of Steering Transmission: Type of Steering Transmission (Ref. ECE Regulation 79 paragraph 2.6)0000b = Purely mechanical steering transmission0001b = Purely hydraulic steering transmission0010b = Purely electric steering transmission0011b = Hybri...";
CM_ BO_ 2565869310 "Aftertreatment 1 Intake Gas 1";
CM_ SG_ 2565869310 Aftrtrtmnt1IntkGsSnsr1HtrCntrl "Aftertreatment 1 Intake Gas Sensor 1 Heater Control: Indicates the heater status in the warm-up process.  Upon receiving a power-up command, the gas sensor ramps up according to a manufacturer defined profile.  The Preheat 1, Preheat 2, and Automatic...";
CM_ SG_ 2565869310 Aftrtrtmnt1IntkGsSnsr1tTmprtr "Aftertreatment 1 Intake Gas Sensor 1 at Temperature: Indicates that the heater element of the aftertreatment intake gas sensor, either NOx or O2, is within the manufacturer's specified range for accurate measurements in exhaust bank 1.00b = Not in ra...";
CM_ SG_ 2565869310 Atttt1ItGsSs1HtPFMI "Aftertreatment 1 Intake Gas Sensor 1 Heater Preliminary FMI: Used to identify the applicable J1939-73 FMI detected in the heater of the intake exhaust gas sensor, either NOx or O2, by the manufacturer’s sensor control software in exhaust bank 1.  In ...";
CM_ SG_ 2565869310 Atttt1ItOxSs1PFMI "Aftertreatment 1 Intake Oxygen  Sensor 1 Preliminary FMI: Used to identify the applicable J1939-73 FMI detected in the aftertreatment intake oxygen sensor by the manufacturer’s sensor control software in exhaust bank 1.  In the case of multiple failu...";
CM_ SG_ 2565869310 Atttt1ItWdRPtOx1RdSt "Aftertreatment 1 Intake Wide-Range Percent Oxygen 1 Reading Stable: Indicates that the percent oxygen reading of the aftertreatment intake gas sensor, either NOx or O2, is stable as determined by the manufacturer's control software in exhaust bank 1....";
CM_ SG_ 2565869310 EngineExhaust1NOx1 "Engine Exhaust 1 NOx 1: The amount of combined NO and NO2 in the exhaust, represented in NOx molecule parts per million non-NOx molecules, in exhaust bank 1.  This sensor is located at the intake of the SCR system if an SCR system exists. SPN 3216 sh...";
CM_ SG_ 2565869310 EngineExhaust1NOx1ReadingStable "Engine Exhaust 1 NOx 1 Reading Stable: Indicates that the NOx reading of the first NOx sensor is stable as determined by the manufacturer's control software in exhaust bank 1.  This sensor is located at the intake of the SCR system if an SCR system e...";
CM_ SG_ 2565869310 EngnExhst1NOxSnsr1PrlmnrFMI "Engine Exhaust 1 NOx Sensor 1 Preliminary FMI: Used to identify the applicable J1939-73 FMI detected in the first NOx sensor by the manufacturer’s sensor control software in exhaust bank 1.  This sensor is located at the intake of the SCR system if a...";
CM_ SG_ 2565869310 EngnExhst1NOxSnsr1SlfdgnssStts "Engine Exhaust 1 NOx Sensor 1 Self-diagnosis Status: Self-diagnosis result status for the first NOx sensor in Engine Exhaust Bank 1 (EEB1).  This sensor is located at the intake of the aftertreatment system if an aftertreatment system exists.000b = D...";
CM_ SG_ 2565869310 EngineExhaust1PercentOxygen1 "Engine Exhaust 1 Percent Oxygen 1: The actual oxidation factor (Percent Oxygen) of the gas within the exhaust stream. For positive values, the parameter represents the percent oxygen in excess of the amount required for stoichiometric combustion. For...";
CM_ SG_ 2565869310 EngnExhst1GsSnsr1PwrInRng "Engine Exhaust 1 Gas Sensor 1 Power In Range: Indicates that the power supplied to the first gas sensor, either NOx or O2,  is within the manufacturer's specification in exhaust bank 1.  This parameter reports the status as reported by the sensor. Th...";
CM_ BO_ 2565869566 "Aftertreatment 1 Outlet Gas 1";
CM_ SG_ 2565869566 Aftertreatment1OutletNOx1 "Aftertreatment 1 Outlet NOx 1: The amount of combined NO and NO2 in the exhaust exiting the aftertreatment system measured by a NOx sensor at the aftertreatment outlet, represented in NOx molecule parts per million non-NOx molecules in exhaust bank 1...";
CM_ SG_ 2565869566 Aftrtrtmnt1OtltGsSnsr1HtrCntrl "Aftertreatment 1 Outlet Gas Sensor 1 Heater Control: Indicates the heater status in the warm-up process.  Upon receiving a power-up command, the gas sensor ramps up according to a manufacturer defined profile.  The Preheat 1, Preheat 2, and Automatic...";
CM_ SG_ 2565869566 Aftrtrtmnt1OtltGsSnsr1PwrInRng "Aftertreatment 1 Outlet Gas Sensor 1 Power In Range: Indicates that the power supplied to the aftertreatment outlet gas sensor, either NOx or O2, is within the manufacturer's specification in exhaust bank 1. This parameter reports the status as repor...";
CM_ SG_ 2565869566 Aftrtrtmnt1OtltGsSnsr1tTmprtr "Aftertreatment 1 Outlet Gas Sensor 1 at Temperature: Indicates that the heater element of the aftertreatment outlet gas sensor, either NOx or O2, is within the manufacturer's specified range for accurate measurements in exhaust bank 1.00b = Not in ra...";
CM_ SG_ 2565869566 Aftrtrtmnt1OtltNOx1RdngStl "Aftertreatment 1 Outlet NOx 1 Reading Stable: Indicates that the NOx reading of the aftertreatment outlet NOx sensor is stable as determined by the manufacturer's control software in exhaust bank 1.00b = Not stable01b = Stable10b = Error11b = Not ava...";
CM_ SG_ 2565869566 Aftrtrtmnt1OtltPrntOxgn1 "Aftertreatment 1 Outlet Percent Oxygen 1: The actual oxidation factor (percent oxygen) of the gas within the exhaust stream.  For positive values, the parameter represents the percent oxygen in excess of the amount required for stoichiometric combust...";
CM_ SG_ 2565869566 Atttt1OttGsSs1HtPFMI "Aftertreatment 1 Outlet Gas Sensor 1 Heater Preliminary FMI: Used to identify the applicable J1939-73 FMI detected in the heater of the outlet exhaust gas sensor, either NOx or O2, by the manufacturer’s sensor control software in exhaust bank 1.  In ...";
CM_ SG_ 2565869566 Atttt1OttNOxSs1PFMI "Aftertreatment 1 Outlet NOx Sensor 1 Preliminary FMI: Used to identify the applicable J1939-73 FMI detected in the aftertreatment outlet NOx sensor by the manufacturer’s sensor control software in exhaust bank 1.  In the case of multiple failures the...";
CM_ SG_ 2565869566 Atttt1OttNOxSs1SdssStts "Aftertreatment 1 Outlet NOx Sensor 1 Self-diagnosis Status: Self-diagnosis result status for NOx sensor ATO1 (Aftertreatment Outlet Bank 1)000b = Diagnosis not active001b = NOx Sensor ATO1 Self-diagnosis active flag010b = NOx Sensor ATO1 Self-diagnos...";
CM_ SG_ 2565869566 Atttt1OttOxSs1PFMI "Aftertreatment 1 Outlet Oxygen Sensor 1 Preliminary FMI: Used to identify the applicable J1939-73 FMI detected in the aftertreatment outlet oxygen sensor by the manufacturer’s sensor control software in exhaust bank 1.  In the case of multiple failur...";
CM_ SG_ 2565869566 Atttt1OttWdRPtOx1RdSt "Aftertreatment 1 Outlet Wide-Range Percent Oxygen 1 Reading Stable: Indicates that the percent oxygen reading of the aftertreatment outlet gas sensor, either NOx or O2, is stable as determined by the manufacturer's control software in exhaust bank 1....";
CM_ BO_ 2565869822 "Aftertreatment 2 Intake Gas 1";
CM_ SG_ 2565869822 Aftrtrtmnt2IntkGsSnsr1HtrCntrl "Aftertreatment 2 Intake Gas Sensor 1 Heater Control: Indicates the heater status in the warm-up process.  Upon receiving a power-up command, the gas sensor ramps up according to a manufacturer defined profile.  The Preheat 1, Preheat 2, and Automatic...";
CM_ SG_ 2565869822 Aftrtrtmnt2IntkGsSnsr1tTmprtr "Aftertreatment 2 Intake Gas Sensor 1 at Temperature: Indicates that the heater element of the aftertreatment intake gas sensor, either NOx or O2, is within the manufacturer's specified range for accurate measurements in exhaust bank 2.For a single ex...";
CM_ SG_ 2565869822 Atttt2ItGsSs1HtPFMI "Aftertreatment 2 Intake Gas Sensor 1 Heater Preliminary FMI: Used to identify the applicable J1939-73 FMI detected in the heater of the intake exhaust gas sensor, either NOx or O2, by the manufacturer’s sensor control software in exhaust bank 2.  In ...";
CM_ SG_ 2565869822 Atttt2ItOxSs1PFMI "Aftertreatment 2 Intake Oxygen Sensor 1 Preliminary FMI: Used to identify the applicable J1939-73 FMI detected in the aftertreatment intake oxygen sensor by the manufacturer’s sensor control software in exhaust bank 2.  In the case of multiple failur...";
CM_ SG_ 2565869822 Atttt2ItWdRPtOx1RdSt "Aftertreatment 2 Intake Wide-Range Percent Oxygen 1 Reading Stable: Indicates that the percent oxygen reading of the aftertreatment intake gas sensor, either NOx or O2, is stable as determined by the manufacturer's control software in exhaust bank 2....";
CM_ SG_ 2565869822 EngineExhaust2NOx1 "Engine Exhaust 2 NOx 1: The amount of combined NO and NO2 in the exhaust, represented in NOx molecule parts per million non-NOx molecules, in exhaust bank 2.  This sensor is located at the intake of the SCR system if an SCR system exists.For a single...";
CM_ SG_ 2565869822 EngineExhaust2NOx1ReadingStable "Engine Exhaust 2 NOx 1 Reading Stable: Indicates that the NOx reading of the first NOx sensor is stable as determined by the manufacturer's control software in exhaust bank 2.  This sensor is located at the intake of the SCR system if an SCR system e...";
CM_ SG_ 2565869822 EngnExhst2NOxSnsr1PrlmnrFMI "Engine Exhaust 2 NOx Sensor 1 Preliminary FMI: Used to identify the applicable J1939-73 FMI detected in the NOx sensor by the manufacturer’s sensor control software in exhaust bank 2.  This sensor is located at the intake of the SCR system if an SCR ...";
CM_ SG_ 2565869822 EngnExhst2NOxSnsr1SlfdgnssStts "Engine Exhaust 2 NOx Sensor 1 Self-diagnosis Status: Self-diagnosis result status for NOx sensor Engine Exhaust Bank 2 (EEB2).  This sensor is located at the intake of the aftertreatment system if an aftertreatment system exists.000b = Diagnosis not ...";
CM_ SG_ 2565869822 EngineExhaust2PercentOxygen1 "Engine Exhaust 2 Percent Oxygen 1: The actual oxidation factor (percent oxygen) of the gas within the exhaust stream.  For positive values, the parameter represents the percent oxygen in excess of the amount required for stoichiometric combustion.  F...";
CM_ SG_ 2565869822 EngnExhst2GsSnsr1PwrInRng "Engine Exhaust 2 Gas Sensor 1 Power In Range: Indicates that the power supplied to the first gas sensor, either NOx or O2,  is within the manufacturer's specification in exhaust bank 2.  This parameter reports the status as reported by the sensor. Th...";
CM_ SG_ 2565869822 EngnExhst2GsSnsr2PwrSppl "Engine Exhaust 2 Gas Sensor 2 Power Supply: State signal which indicates when the Engine Exhaust 2 Intake 2 Gas Sensor driver output is being driven.  On means the ECU is powering the Engine Exhaust 2 Intake 2 Gas Sensor.  Note that the ECU is extern...";
CM_ BO_ 2565870078 "Aftertreatment 2 Outlet Gas 1";
CM_ SG_ 2565870078 Aftertreatment2OutletNOx1 "Aftertreatment 2 Outlet NOx 1: The amount of combined NO and NO2 in the exhaust entering the aftertreatment system measured by a NOx sensor at the aftertreatment outlet, represented in NOx molecule parts per million non-NOx molecules in exhaust bank ...";
CM_ SG_ 2565870078 Aftrtrtmnt2Otlt2GsSnsrPwrSppl "Aftertreatment 2 Outlet 2 Gas Sensor Power Supply: State signal which indicates when the Aftertreatment 2 Outlet 2 Gas Sensor driver output is being driven.  On means the ECU is powering the Aftertreatment 2 Outlet 2 Gas Sensor.  Note that the ECU is...";
CM_ SG_ 2565870078 Aftrtrtmnt2OtltGsSnsr1HtrCntrl "Aftertreatment 2 Outlet Gas Sensor 1 Heater Control: Indicates the heater status in the warm-up process.  Upon receiving a power-up command, the gas sensor ramps up according to a manufacturer defined profile.  The Preheat 1, Preheat 2, and Automatic...";
CM_ SG_ 2565870078 Aftrtrtmnt2OtltGsSnsr1PwrInRng "Aftertreatment 2 Outlet Gas Sensor 1 Power In Range:  Indicates that the power supplied to the aftertreatment outlet gas sensor, either NOx or O2, is within the manufacturer's specification in exhaust bank 2.For a single exhaust bank system, refer to...";
CM_ SG_ 2565870078 Aftrtrtmnt2OtltGsSnsr1tTmprtr "Aftertreatment 2 Outlet Gas Sensor 1 at Temperature: Indicates that the heater element of the aftertreatment outlet gas sensor, either NOx or O2, is within the manufacturer's specified range for accurate measurements in exhaust bank 2.For a single ex...";
CM_ SG_ 2565870078 Aftrtrtmnt2OtltNOx1RdngStl "Aftertreatment 2 Outlet NOx 1 Reading Stable: Indicates that the NOx reading of the aftertreatment outlet NOx sensor is stable as determined by the manufacturer's control software in exhaust bank 2.For a single exhaust bank system, refer to parameter...";
CM_ SG_ 2565870078 Aftrtrtmnt2OtltPrntOxgn1 "Aftertreatment 2 Outlet Percent Oxygen 1: The actual oxidation factor (percent oxygen) of the gas within the exhaust stream.  For positive values, the parameter represents the percent oxygen in excess of the amount required for stoichiometric combust...";
CM_ SG_ 2565870078 Atttt2OttGsSs1HtPFMI "Aftertreatment 2 Outlet Gas Sensor 1 Heater Preliminary FMI: Used to identify the applicable J1939-73 FMI detected in the heater of the outlet exhaust gas sensor, either NOx or O2, by the manufacturer’s sensor control software in exhaust bank 2.  In ...";
CM_ SG_ 2565870078 Atttt2OttNOxSs1PFMI "Aftertreatment 2 Outlet NOx Sensor 1 Preliminary FMI: Used to identify the applicable J1939-73 FMI detected in the aftertreatment outlet NOx sensor by the manufacturer’s sensor control software in exhaust bank 2.  In the case of multiple failures the...";
CM_ SG_ 2565870078 Atttt2OttNOxSs1SdssStts "Aftertreatment 2 Outlet NOx Sensor 1 Self-diagnosis Status: Self-diagnosis result status for NOx sensor ATO2 (Aftertreatment Outlet Bank 2)000b = Diagnosis not active001b = NOx Sensor ATO2 Self-diagnosis active flag010b = NOx Sensor ATO2 Self-diagnos...";
CM_ SG_ 2565870078 Atttt2OttOxSs1PFMI "Aftertreatment 2 Outlet Oxygen Sensor 1 Preliminary FMI: Used to identify the applicable J1939-73 FMI detected in the aftertreatment outlet oxygen sensor by the manufacturer’s sensor control software in exhaust bank 2.  In the case of multiple failur...";
CM_ SG_ 2565870078 Atttt2OttWdRPtOx1RdSt "Aftertreatment 2 Outlet Wide-Range Percent Oxygen 1 Reading Stable: Indicates that the percent oxygen reading of the aftertreatment outlet gas sensor, either NOx or O2, is stable as determined by the manufacturer's control software in exhaust bank 2....";
CM_ BO_ 2565870334 "Fifth Wheel Smart Systems 1";
CM_ SG_ 2565870334 FifthWheelDrawbarForce "Fifth Wheel Drawbar Force: Fifth wheel drawbar force, with the trailer held stationary a positive force is generated by the vehicle pulling forward.";
CM_ SG_ 2565870334 FifthWheelRollMoment "Fifth Wheel Roll Moment : Fifth wheel roll moment force - If the moment is positive, the trailer is rolling clockwise relative to the normal vehicle forward motion.";
CM_ SG_ 2565870334 FifthWheelRollWarningIndicator "Fifth Wheel Roll Warning Indicator: Indicates to the vehicle operator that the roll moment has exceeded a preset limit. 00b = Limit not exceeded01b = Limit exceeded10b = error11b = Not Available";
CM_ SG_ 2565870334 FifthWheelVerticalForce "Fifth Wheel Vertical Force: The amount of load being applied to the fifth wheel by the trailer. Zero load is indicated without a trailer.";
BA_DEF_ SG_  "SPN" INT 0 524287;
BA_DEF_ BO_  "VFrameFormat" ENUM  "StandardCAN","ExtendedCAN","reserved","J1939PG";
BA_DEF_DEF_  "SPN" 0;
BA_DEF_DEF_  "VFrameFormat" "J1939PG";
BA_ "SPN" SG_ 2558394110 EltrfdAssrMtrEnlCmmnd 7943;
BA_ "SPN" SG_ 2558394110 EltrfdAssrMtrPrntSpdCmmnd 7946;
BA_ "SPN" SG_ 2558394110 EltrfdAssrMtrPwrHld 7944;
BA_ "SPN" SG_ 2558394110 EltrfdAssrMtrSpdCmmnd 7945;
BA_ "SPN" SG_ 2558394110 ElectrifiedAccessoryMotor1 8292;
BA_ "SPN" SG_ 2558394110 ElectrifiedAccessoryMotor2 8293;
BA_ "SPN" SG_ 2558394110 ElectrifiedAccessoryMotor3 8294;
BA_ "SPN" SG_ 2558394110 ElectrifiedAccessoryMotor4 8295;
BA_ "SPN" SG_ 2558394110 ElectrifiedAccessoryMotor5 8296;
BA_ "SPN" SG_ 2558394110 ElectrifiedAccessoryMotor6 8297;
BA_ "SPN" SG_ 2558394110 ElectrifiedAccessoryMotor7 8298;
BA_ "SPN" SG_ 2558394110 ElectrifiedAccessoryMotor8 8299;
BA_ "SPN" SG_ 2558394110 ElectrifiedAccessoryMotor9 8300;
BA_ "SPN" SG_ 2558394110 ElectrifiedAccessoryMotor10 8301;
BA_ "SPN" SG_ 2558394110 ElectrifiedAccessoryMotor11 8302;
BA_ "SPN" SG_ 2558394110 ElectrifiedAccessoryMotor12 8303;
BA_ "SPN" SG_ 2558394110 ElectrifiedAccessoryMotor13 8304;
BA_ "SPN" SG_ 2558394110 ElectrifiedAccessoryMotor14 8305;
BA_ "SPN" SG_ 2558394110 ElectrifiedAccessoryMotor15 8306;
BA_ "SPN" SG_ 2558459646 RqstdEngnSpdAlrtnRtLmt 7760;
BA_ "SPN" SG_ 2558459646 RqstdEngnSpdDlrtnRtLmt 7761;
BA_ "SPN" SG_ 2558525182 NumberofTireSensors 7583;
BA_ "SPN" SG_ 2558525182 TireLocation 7585;
BA_ "SPN" SG_ 2558525182 TireNumber 7584;
BA_ "SPN" SG_ 2558525182 TireSensorIdentificationNumber 7586;
BA_ "SPN" SG_ 2558590718 ExtrnlEnrgSrCnntnDmnd 7890;
BA_ "SPN" SG_ 2558590718 HrdSstmPrplsnDslRqst 7558;
BA_ "SPN" SG_ 2558590718 HrdSstmPrttnOvrrdRqst 7557;
BA_ "SPN" SG_ 2558590718 HrdSstmRgnrtvBrkngDslRqst 7559;
BA_ "SPN" SG_ 2558590718 HybridPropulsionModeRequest 7889;
BA_ "SPN" SG_ 2558590718 HybridSystemShutdownCommand 7560;
BA_ "SPN" SG_ 2558590718 OperatorVehicleModeRequest 7888;
BA_ "SPN" SG_ 2558590718 StrdEnrgSrChrgDshrgRtRqst 7891;
BA_ "SPN" SG_ 2558590718 StrdEnrgSrStPntRqst 7892;
BA_ "SPN" SG_ 2558590718 HVESChargeConsent 10148;
BA_ "SPN" SG_ 2558590718 HrdPrplsnMdRqstdMxmmSpd 9706;
BA_ "SPN" SG_ 2558590718 HrdPrplsnMdRqstdDstn 9707;
BA_ "SPN" SG_ 2558590718 ConnectedEnergySourceType 13154;
BA_ "SPN" SG_ 2558656254 AftrtrtmntDslExhstFldDsrRdStts 8149;
BA_ "SPN" SG_ 2558656254 AftrtrtmntSstmEnlStts 7851;
BA_ "SPN" SG_ 2558656254 AftrtrtmntThrmlMngmntInhtRqst 7331;
BA_ "SPN" SG_ 2558656254 RqsttPrmtDEFHdrlStffnssChk 7515;
BA_ "SPN" SG_ 2558656254 RqsttPrmtSCRDsngTstInjtn 7516;
BA_ "SPN" SG_ 2558721790 ColdInflationPressureSetting 6974;
BA_ "SPN" SG_ 2558721790 ExtrmUndrPrssrPrntgThrshldSttng 6976;
BA_ "SPN" SG_ 2558721790 OverTemperatureSetting 6978;
BA_ "SPN" SG_ 2558721790 OvrPrssrPrntgThrshldSttng 6977;
BA_ "SPN" SG_ 2558721790 TireLocation 6973;
BA_ "SPN" SG_ 2558721790 TireSensorEnableSetting 7587;
BA_ "SPN" SG_ 2558721790 UndrPrssrPrntgThrshldSttng 6975;
BA_ "SPN" SG_ 2558787326 PayloadCorrectionFactorCommand 6873;
BA_ "SPN" SG_ 2558787326 PldClrtnCmmnddWght 6872;
BA_ "SPN" SG_ 2558787326 PldClrtnStPntCmmnd 6871;
BA_ "SPN" SG_ 2558852862 Aftrtrtmnt1PrtltSnsrDwpnt 6784;
BA_ "SPN" SG_ 2558852862 Aftrtrtmnt1PrtltSnsrExhstTmprtr 6785;
BA_ "SPN" SG_ 2558852862 Aftrtrtmnt1PrtltSnsrExhstVlt 6829;
BA_ "SPN" SG_ 2558852862 Aftrtrtmnt1PrtltSnsrRgnrtnRqst 6783;
BA_ "SPN" SG_ 2558852862 Aftrtrtmnt1PrtltSnsrShtdwnRqst 6782;
BA_ "SPN" SG_ 2558918398 ActiveShiftConsoleRequest 8855;
BA_ "SPN" SG_ 2558918398 AftrtrtmntSstmEnlCmmnd 8148;
BA_ "SPN" SG_ 2558918398 AttttRtESpdAwdSwt 7580;
BA_ "SPN" SG_ 2558918398 ElvtdEngnSpdAllwdSwth 7579;
BA_ "SPN" SG_ 2558918398 EngineFan2RequestedPercentSpeed 6730;
BA_ "SPN" SG_ 2558918398 EngineStopStartDisableCommand 7759;
BA_ "SPN" SG_ 2558918398 EngnIdlMngmntPndngEvntOvrrd 9374;
BA_ "SPN" SG_ 2558918398 HtExhngrDrsPrgFrSwth 7034;
BA_ "SPN" SG_ 2558918398 HtExhngrDrsPrgInhtSwth 7033;
BA_ "SPN" SG_ 2558918398 PerformanceBiasSelection 6874;
BA_ "SPN" SG_ 2558918398 PrdtvCrsCntrlDtvtnRqst 7437;
BA_ "SPN" SG_ 2558918398 PrdtvCrsCntrlEnlSwth 7436;
BA_ "SPN" SG_ 2558918398 PrdtvCrsCntrlMxmmNgtvOffst 7439;
BA_ "SPN" SG_ 2558918398 PrdtvCrsCntrlMxmmPstvOffst 7438;
BA_ "SPN" SG_ 2558918398 SCROprtrIndmntOvrrdSwth 6881;
BA_ "SPN" SG_ 2558918398 TrnsmssnAtNtrlMnlRtrnEnlSwth 7694;
BA_ "SPN" SG_ 2558918398 VehicleHoodSwitch 5575;
BA_ "SPN" SG_ 2558983934 SwitchedPowerOutput10Command 5994;
BA_ "SPN" SG_ 2558983934 SwitchedPowerOutput11Command 5993;
BA_ "SPN" SG_ 2558983934 SwitchedPowerOutput12Command 5992;
BA_ "SPN" SG_ 2558983934 SwitchedPowerOutput13Command 5999;
BA_ "SPN" SG_ 2558983934 SwitchedPowerOutput14Command 5998;
BA_ "SPN" SG_ 2558983934 SwitchedPowerOutput15Command 5997;
BA_ "SPN" SG_ 2558983934 SwitchedPowerOutput16Command 5996;
BA_ "SPN" SG_ 2558983934 SwitchedPowerOutput17Command 6003;
BA_ "SPN" SG_ 2558983934 SwitchedPowerOutput18Command 6002;
BA_ "SPN" SG_ 2558983934 SwitchedPowerOutput19Command 6001;
BA_ "SPN" SG_ 2558983934 SwitchedPowerOutput1Command 5987;
BA_ "SPN" SG_ 2558983934 SwitchedPowerOutput20Command 6000;
BA_ "SPN" SG_ 2558983934 SwitchedPowerOutput21Command 6007;
BA_ "SPN" SG_ 2558983934 SwitchedPowerOutput22Command 6006;
BA_ "SPN" SG_ 2558983934 SwitchedPowerOutput23Command 6005;
BA_ "SPN" SG_ 2558983934 SwitchedPowerOutput24Command 6004;
BA_ "SPN" SG_ 2558983934 SwitchedPowerOutput25Command 6011;
BA_ "SPN" SG_ 2558983934 SwitchedPowerOutput26Command 6010;
BA_ "SPN" SG_ 2558983934 SwitchedPowerOutput27Command 6009;
BA_ "SPN" SG_ 2558983934 SwitchedPowerOutput28Command 6008;
BA_ "SPN" SG_ 2558983934 SwitchedPowerOutput29Command 6015;
BA_ "SPN" SG_ 2558983934 SwitchedPowerOutput2Command 5986;
BA_ "SPN" SG_ 2558983934 SwitchedPowerOutput30Command 6014;
BA_ "SPN" SG_ 2558983934 SwitchedPowerOutput31Command 6013;
BA_ "SPN" SG_ 2558983934 SwitchedPowerOutput32Command 6012;
BA_ "SPN" SG_ 2558983934 SwitchedPowerOutput3Command 5985;
BA_ "SPN" SG_ 2558983934 SwitchedPowerOutput4Command 5984;
BA_ "SPN" SG_ 2558983934 SwitchedPowerOutput5Command 5991;
BA_ "SPN" SG_ 2558983934 SwitchedPowerOutput6Command 5990;
BA_ "SPN" SG_ 2558983934 SwitchedPowerOutput7Command 5989;
BA_ "SPN" SG_ 2558983934 SwitchedPowerOutput8Command 5988;
BA_ "SPN" SG_ 2558983934 SwitchedPowerOutput9Command 5995;
BA_ "SPN" SG_ 2559049470 DesiredEngineFuelingState 5793;
BA_ "SPN" SG_ 2559049470 EngineFuelingDesiredReason 7789;
BA_ "SPN" SG_ 2559049470 EngineFuelingNotDesiredReason 7855;
BA_ "SPN" SG_ 2559049470 EngineGaseousFuelUsageInhibited 6833;
BA_ "SPN" SG_ 2559049470 EngineShutdownCommand 8614;
BA_ "SPN" SG_ 2559049470 EngnGssFlSpplDsrdPrssr 6715;
BA_ "SPN" SG_ 2559049470 EngnPrttnDrtOvrrdCmmnd 9173;
BA_ "SPN" SG_ 2559049470 RequestedFuelType 6317;
BA_ "SPN" SG_ 2559049470 TrnsmssnIdlGvrnrFlngInht 7829;
BA_ "SPN" SG_ 2559115006 RadioBeaconDirection 5755;
BA_ "SPN" SG_ 2559115006 TransmitterID2 5756;
BA_ "SPN" SG_ 2559115006 UnqBnMssgIdntfrNmr 5754;
BA_ "SPN" SG_ 2559115006 WirelessSignalStrength2 5757;
BA_ "SPN" SG_ 2559573758 CtLvEPttStdwOvdCd 5565;
BA_ "SPN" SG_ 2559639294 SupplementalFanDirectionCommand 5553;
BA_ "SPN" SG_ 2559639294 SupplementalFanEnableCommand 5552;
BA_ "SPN" SG_ 2559639294 SupplementalFanPowerHold 5555;
BA_ "SPN" SG_ 2559639294 SupplementalFanSpeedCommand 5554;
BA_ "SPN" SG_ 2559704830 LrtnOprtnMdStCmmnd 5512;
BA_ "SPN" SG_ 2559704830 LubricationCycleModeLockCommand 5510;
BA_ "SPN" SG_ 2559704830 LubricationCycleSetCommand 5511;
BA_ "SPN" SG_ 2559704830 LubricationPumpEnableCommand 5513;
BA_ "SPN" SG_ 2559704830 LubricationTimingCycleCommand 5514;
BA_ "SPN" SG_ 2559770366 HydrocarbonDoserPurgingRequired 5509;
BA_ "SPN" SG_ 2559770366 RequestedFuelMassRate 5505;
BA_ "SPN" SG_ 2559770366 Aftertreatment1DPFHydrocarbon 10155;
BA_ "SPN" SG_ 2559770366 HydrocarbonDoserStatus 5506;
BA_ "SPN" SG_ 2559770366 HydrocarbonDoserInjectingStatus 5507;
BA_ "SPN" SG_ 2559770366 DgnstSttsfHdrrnDsr 5508;
BA_ "SPN" SG_ 2559901438 Atttt1DsPttFtStMCtOst 5495;
BA_ "SPN" SG_ 2559901438 Atttt1DsPttFtStStddDvtCtOst 5496;
BA_ "SPN" SG_ 2559966974 Atttt2DsPttFtStMCtOst 5497;
BA_ "SPN" SG_ 2559966974 Atttt2DsPttFtStStddDvtCtOst 5498;
BA_ "SPN" SG_ 2560032510 LwVltgDsnntDsrdOprtngMd 5149;
BA_ "SPN" SG_ 2560098046 CabNoiseControlStatus 5059;
BA_ "SPN" SG_ 2560098046 CabNoiseControlTuningStatus 5060;
BA_ "SPN" SG_ 2560163582 CabNoiseControlCommand 5057;
BA_ "SPN" SG_ 2560163582 CabNoiseControlTuningCommand 5058;
BA_ "SPN" SG_ 2560360190 DataDictionaryManufacturerCode 4180;
BA_ "SPN" SG_ 2560360190 DataDictionaryMethod 4181;
BA_ "SPN" SG_ 2560425726 AuxiliaryIOChannel15 4170;
BA_ "SPN" SG_ 2560425726 AuxiliaryIOChannel16 4169;
BA_ "SPN" SG_ 2560425726 AuxiliaryIOChannel17 4168;
BA_ "SPN" SG_ 2560425726 AuxiliaryIOChannel18 4167;
BA_ "SPN" SG_ 2560425726 AuxiliaryIOChannel19 4174;
BA_ "SPN" SG_ 2560425726 AuxiliaryIOChannel20 4173;
BA_ "SPN" SG_ 2560425726 AuxiliaryIOChannel21 4172;
BA_ "SPN" SG_ 2560425726 AuxiliaryIOChannel22 4171;
BA_ "SPN" SG_ 2560491262 AuxiliaryIOChannel10 4159;
BA_ "SPN" SG_ 2560491262 AuxiliaryIOChannel11 4166;
BA_ "SPN" SG_ 2560491262 AuxiliaryIOChannel12 4165;
BA_ "SPN" SG_ 2560491262 AuxiliaryIOChannel13 4164;
BA_ "SPN" SG_ 2560491262 AuxiliaryIOChannel14 4163;
BA_ "SPN" SG_ 2560491262 AuxiliaryIOChannel7 4162;
BA_ "SPN" SG_ 2560491262 AuxiliaryIOChannel8 4161;
BA_ "SPN" SG_ 2560491262 AuxiliaryIOChannel9 4160;
BA_ "SPN" SG_ 2561015550 AuxiliaryIO100 3923;
BA_ "SPN" SG_ 2561015550 AuxiliaryIO101 3924;
BA_ "SPN" SG_ 2561015550 AuxiliaryIO102 3925;
BA_ "SPN" SG_ 2561015550 AuxiliaryIO103 3926;
BA_ "SPN" SG_ 2561015550 AuxiliaryIO104 3927;
BA_ "SPN" SG_ 2561015550 AuxiliaryIO105 3928;
BA_ "SPN" SG_ 2561015550 AuxiliaryIO106 3929;
BA_ "SPN" SG_ 2561015550 AuxiliaryIO107 3930;
BA_ "SPN" SG_ 2561015550 AuxiliaryIO108 3931;
BA_ "SPN" SG_ 2561015550 AuxiliaryIO109 3932;
BA_ "SPN" SG_ 2561015550 AuxiliaryIO110 3933;
BA_ "SPN" SG_ 2561015550 AuxiliaryIO111 3934;
BA_ "SPN" SG_ 2561015550 AuxiliaryIO112 3935;
BA_ "SPN" SG_ 2561015550 AuxiliaryIO81 3904;
BA_ "SPN" SG_ 2561015550 AuxiliaryIO82 3905;
BA_ "SPN" SG_ 2561015550 AuxiliaryIO83 3906;
BA_ "SPN" SG_ 2561015550 AuxiliaryIO84 3907;
BA_ "SPN" SG_ 2561015550 AuxiliaryIO85 3908;
BA_ "SPN" SG_ 2561015550 AuxiliaryIO86 3909;
BA_ "SPN" SG_ 2561015550 AuxiliaryIO87 3910;
BA_ "SPN" SG_ 2561015550 AuxiliaryIO88 3911;
BA_ "SPN" SG_ 2561015550 AuxiliaryIO89 3912;
BA_ "SPN" SG_ 2561015550 AuxiliaryIO90 3913;
BA_ "SPN" SG_ 2561015550 AuxiliaryIO91 3914;
BA_ "SPN" SG_ 2561015550 AuxiliaryIO92 3915;
BA_ "SPN" SG_ 2561015550 AuxiliaryIO93 3916;
BA_ "SPN" SG_ 2561015550 AuxiliaryIO94 3917;
BA_ "SPN" SG_ 2561015550 AuxiliaryIO95 3918;
BA_ "SPN" SG_ 2561015550 AuxiliaryIO96 3919;
BA_ "SPN" SG_ 2561015550 AuxiliaryIO97 3920;
BA_ "SPN" SG_ 2561015550 AuxiliaryIO98 3921;
BA_ "SPN" SG_ 2561015550 AuxiliaryIO99 3922;
BA_ "SPN" SG_ 2561081086 AuxiliaryIO49 3872;
BA_ "SPN" SG_ 2561081086 AuxiliaryIO50 3873;
BA_ "SPN" SG_ 2561081086 AuxiliaryIO51 3874;
BA_ "SPN" SG_ 2561081086 AuxiliaryIO52 3875;
BA_ "SPN" SG_ 2561081086 AuxiliaryIO53 3876;
BA_ "SPN" SG_ 2561081086 AuxiliaryIO54 3877;
BA_ "SPN" SG_ 2561081086 AuxiliaryIO55 3878;
BA_ "SPN" SG_ 2561081086 AuxiliaryIO56 3879;
BA_ "SPN" SG_ 2561081086 AuxiliaryIO57 3880;
BA_ "SPN" SG_ 2561081086 AuxiliaryIO58 3881;
BA_ "SPN" SG_ 2561081086 AuxiliaryIO59 3882;
BA_ "SPN" SG_ 2561081086 AuxiliaryIO60 3883;
BA_ "SPN" SG_ 2561081086 AuxiliaryIO61 3884;
BA_ "SPN" SG_ 2561081086 AuxiliaryIO62 3885;
BA_ "SPN" SG_ 2561081086 AuxiliaryIO63 3886;
BA_ "SPN" SG_ 2561081086 AuxiliaryIO64 3887;
BA_ "SPN" SG_ 2561081086 AuxiliaryIO65 3888;
BA_ "SPN" SG_ 2561081086 AuxiliaryIO66 3889;
BA_ "SPN" SG_ 2561081086 AuxiliaryIO67 3890;
BA_ "SPN" SG_ 2561081086 AuxiliaryIO68 3891;
BA_ "SPN" SG_ 2561081086 AuxiliaryIO69 3892;
BA_ "SPN" SG_ 2561081086 AuxiliaryIO70 3893;
BA_ "SPN" SG_ 2561081086 AuxiliaryIO71 3894;
BA_ "SPN" SG_ 2561081086 AuxiliaryIO72 3895;
BA_ "SPN" SG_ 2561081086 AuxiliaryIO73 3896;
BA_ "SPN" SG_ 2561081086 AuxiliaryIO74 3897;
BA_ "SPN" SG_ 2561081086 AuxiliaryIO75 3898;
BA_ "SPN" SG_ 2561081086 AuxiliaryIO76 3899;
BA_ "SPN" SG_ 2561081086 AuxiliaryIO77 3900;
BA_ "SPN" SG_ 2561081086 AuxiliaryIO78 3901;
BA_ "SPN" SG_ 2561081086 AuxiliaryIO79 3902;
BA_ "SPN" SG_ 2561081086 AuxiliaryIO80 3903;
BA_ "SPN" SG_ 2561146622 AuxiliaryIO17 3840;
BA_ "SPN" SG_ 2561146622 AuxiliaryIO18 3841;
BA_ "SPN" SG_ 2561146622 AuxiliaryIO19 3842;
BA_ "SPN" SG_ 2561146622 AuxiliaryIO20 3843;
BA_ "SPN" SG_ 2561146622 AuxiliaryIO21 3844;
BA_ "SPN" SG_ 2561146622 AuxiliaryIO22 3845;
BA_ "SPN" SG_ 2561146622 AuxiliaryIO23 3846;
BA_ "SPN" SG_ 2561146622 AuxiliaryIO24 3847;
BA_ "SPN" SG_ 2561146622 AuxiliaryIO25 3848;
BA_ "SPN" SG_ 2561146622 AuxiliaryIO26 3849;
BA_ "SPN" SG_ 2561146622 AuxiliaryIO27 3850;
BA_ "SPN" SG_ 2561146622 AuxiliaryIO28 3851;
BA_ "SPN" SG_ 2561146622 AuxiliaryIO29 3852;
BA_ "SPN" SG_ 2561146622 AuxiliaryIO30 3853;
BA_ "SPN" SG_ 2561146622 AuxiliaryIO31 3854;
BA_ "SPN" SG_ 2561146622 AuxiliaryIO32 3855;
BA_ "SPN" SG_ 2561146622 AuxiliaryIO33 3856;
BA_ "SPN" SG_ 2561146622 AuxiliaryIO34 3857;
BA_ "SPN" SG_ 2561146622 AuxiliaryIO35 3858;
BA_ "SPN" SG_ 2561146622 AuxiliaryIO36 3859;
BA_ "SPN" SG_ 2561146622 AuxiliaryIO37 3860;
BA_ "SPN" SG_ 2561146622 AuxiliaryIO38 3861;
BA_ "SPN" SG_ 2561146622 AuxiliaryIO39 3862;
BA_ "SPN" SG_ 2561146622 AuxiliaryIO40 3863;
BA_ "SPN" SG_ 2561146622 AuxiliaryIO41 3864;
BA_ "SPN" SG_ 2561146622 AuxiliaryIO42 3865;
BA_ "SPN" SG_ 2561146622 AuxiliaryIO43 3866;
BA_ "SPN" SG_ 2561146622 AuxiliaryIO44 3867;
BA_ "SPN" SG_ 2561146622 AuxiliaryIO45 3868;
BA_ "SPN" SG_ 2561146622 AuxiliaryIO46 3869;
BA_ "SPN" SG_ 2561146622 AuxiliaryIO47 3870;
BA_ "SPN" SG_ 2561146622 AuxiliaryIO48 3871;
BA_ "SPN" SG_ 2561212158 TextDisplayIndex 3614;
BA_ "SPN" SG_ 2561212158 TextDisplayInstructions 3613;
BA_ "SPN" SG_ 2561277694 CurrentRegion 8133;
BA_ "SPN" SG_ 2561277694 CurrentSubRegion 8134;
BA_ "SPN" SG_ 2561277694 LnDprtrWrnngEnlCmmnd 3564;
BA_ "SPN" SG_ 2561277694 LaneKeepingAssistEnableCommand 9751;
BA_ "SPN" SG_ 2561277694 LaneCenteringEnableCommand 9752;
BA_ "SPN" SG_ 2561277694 RqstdAtvStrngDrvrPrfrnMd 9760;
BA_ "SPN" SG_ 2561605374 ReferenceTirePressureSetting 3193;
BA_ "SPN" SG_ 2561605374 TireLocation 3192;
BA_ "SPN" SG_ 2563768062 EngnSpdLmtRqstMnmmCntns 1784;
BA_ "SPN" SG_ 2563768062 EngnSpdLmtRqstMxmmCntns 1785;
BA_ "SPN" SG_ 2563768062 EngnTrqLmtRqstMnmmCntns 1786;
BA_ "SPN" SG_ 2563768062 EngnTrqLmtRqstMxmmCntns 1787;
BA_ "SPN" SG_ 2563768062 MnmmCntnsRtrdrSpdLmtRqst 1788;
BA_ "SPN" SG_ 2563768062 MnmmCntnsRtrdrTrqLmtRqst 1790;
BA_ "SPN" SG_ 2563768062 MxmmCntnsRtrdrSpdLmtRqst 1789;
BA_ "SPN" SG_ 2563768062 MxmmCntnsRtrdrTrqLmtRqst 1791;
BA_ "SPN" SG_ 2563833598 IlluminationBrightnessPercent 1487;
BA_ "SPN" SG_ 2563833598 SwthBklghtIllmntnBrghtnssPrnt 5532;
BA_ "SPN" SG_ 2563833598 SwthIndtnIllmntnBrghtnssPrnt 6820;
BA_ "SPN" SG_ 2563833598 OprtrDsrdDsplMdCmmnd1 13079;
BA_ "SPN" SG_ 2563833598 OprtrDsrdDsplMdCmmnd2 13080;
BA_ "SPN" SG_ 2564161278 Adjustday 1607;
BA_ "SPN" SG_ 2564161278 Adjusthours 1605;
BA_ "SPN" SG_ 2564161278 Adjustlocalhouroffset 1610;
BA_ "SPN" SG_ 2564161278 Adjustlocalminuteoffset 1609;
BA_ "SPN" SG_ 2564161278 Adjustminutes 1604;
BA_ "SPN" SG_ 2564161278 Adjustmonth 1606;
BA_ "SPN" SG_ 2564161278 Adjustseconds 1603;
BA_ "SPN" SG_ 2564161278 Adjustyear 1608;
BA_ "SPN" SG_ 2564882174 AftrtrtmntRgnrtnFrSwth 3696;
BA_ "SPN" SG_ 2564882174 AftrtrtmntRgnrtnInhtSwth 3695;
BA_ "SPN" SG_ 2564882174 AtmtGrShftngEnlSwth 1666;
BA_ "SPN" SG_ 2564882174 AuxiliaryHeaterModeRequest 1683;
BA_ "SPN" SG_ 2564882174 AxlrHtrClntPmpRqst 1684;
BA_ "SPN" SG_ 2564882174 BatteryMainSwitchHoldRequest 1682;
BA_ "SPN" SG_ 2564882174 CabInteriorTemperatureCommand 1691;
BA_ "SPN" SG_ 2564882174 EngineFan1RequestedPercentSpeed 986;
BA_ "SPN" SG_ 2564882174 EngnAtmtStrtEnlSwth 1656;
BA_ "SPN" SG_ 2564882174 OperatorSeatDirectionSwitch 1714;
BA_ "SPN" SG_ 2564882174 ParkBrakeCommand 5630;
BA_ "SPN" SG_ 2564882174 RequestCabZoneHeating 1686;
BA_ "SPN" SG_ 2564882174 RequestEngineZoneHeating 1685;
BA_ "SPN" SG_ 2564882174 SeatBeltSwitch 1856;
BA_ "SPN" SG_ 2564882174 SltdMxmmVhlSpdLmt 2596;
BA_ "SPN" SG_ 2564882174 VhlLmtngSpdGvrnrDrmntSwth 1655;
BA_ "SPN" SG_ 2564882174 VhlLmtngSpdGvrnrEnlSwth 1653;
BA_ "SPN" SG_ 2564882174 VhlLmtngSpdGvrnrInrmntSwth 1654;
BA_ "SPN" SG_ 2565865982 ABSEBSAmrWrnngSgnlPwrdVhl 1438;
BA_ "SPN" SG_ 2565865982 ABSFullyOperational 1243;
BA_ "SPN" SG_ 2565865982 ABSOffroadSwitch 575;
BA_ "SPN" SG_ 2565865982 AcceleratorInterlockSwitch 972;
BA_ "SPN" SG_ 2565865982 AntiLockBrakingABSActive 563;
BA_ "SPN" SG_ 2565865982 ASRBrakeControlActive 562;
BA_ "SPN" SG_ 2565865982 ASREngineControlActive 561;
BA_ "SPN" SG_ 2565865982 ASRHillHolderSwitch 577;
BA_ "SPN" SG_ 2565865982 ASROffroadSwitch 576;
BA_ "SPN" SG_ 2565865982 ATCASRInformationSignal 1793;
BA_ "SPN" SG_ 2565865982 BrakePedalPosition 521;
BA_ "SPN" SG_ 2565865982 EBSBrakeSwitch 1121;
BA_ "SPN" SG_ 2565865982 EBSRedWarningSignal 1439;
BA_ "SPN" SG_ 2565865982 EngineAuxiliaryShutdownSwitch 970;
BA_ "SPN" SG_ 2565865982 EngineDerateSwitch 971;
BA_ "SPN" SG_ 2565865982 EngineRetarderSelection 973;
BA_ "SPN" SG_ 2565865982 Haltbrakeswitch 2911;
BA_ "SPN" SG_ 2565865982 RailroadModeSwitch 7941;
BA_ "SPN" SG_ 2565865982 RemoteAcceleratorEnableSwitch 969;
BA_ "SPN" SG_ 2565865982 SrAddrssfCntrllngDvfrBrkCntrl 1481;
BA_ "SPN" SG_ 2565865982 TractionControlOverrideSwitch 1238;
BA_ "SPN" SG_ 2565865982 TrailerABSStatus 1836;
BA_ "SPN" SG_ 2565865982 TrtrMntdTrlrABSWrnngSgnl 1792;
BA_ "SPN" SG_ 2565867006 TransmissionActualGearRatio 526;
BA_ "SPN" SG_ 2565867006 TransmissionCurrentGear 523;
BA_ "SPN" SG_ 2565867006 TransmissionCurrentRange 163;
BA_ "SPN" SG_ 2565867006 TransmissionRequestedRange 162;
BA_ "SPN" SG_ 2565867006 TransmissionSelectedGear 524;
BA_ "SPN" SG_ 2565867262 DffrntlLkSttCntrlFrnt 565;
BA_ "SPN" SG_ 2565867262 DffrntlLkSttCntrlRr 566;
BA_ "SPN" SG_ 2565867262 DifferentialLockStateCentral 564;
BA_ "SPN" SG_ 2565867262 DifferentialLockStateFrontAxle1 567;
BA_ "SPN" SG_ 2565867262 DifferentialLockStateFrontAxle2 568;
BA_ "SPN" SG_ 2565867262 DifferentialLockStateRearAxle1 569;
BA_ "SPN" SG_ 2565867262 DifferentialLockStateRearAxle2 570;
BA_ "SPN" SG_ 2565867262 DifferentialLockStateRearAxle3 7716;
BA_ "SPN" SG_ 2565867262 Frontaxlegroupengagementstatus 3819;
BA_ "SPN" SG_ 2565867262 Location 927;
BA_ "SPN" SG_ 2565867262 Rearaxlegroupengagementstatus 3820;
BA_ "SPN" SG_ 2565867262 DogClutchRearAxle2 12285;
BA_ "SPN" SG_ 2565867774 EngnHdrlPrssrGvrnrMdIndtr 1763;
BA_ "SPN" SG_ 2565867774 EngnHdrlPrssrGvrnrSwth 1764;
BA_ "SPN" SG_ 2565867774 FireApparatusPumpEngagement 2599;
BA_ "SPN" SG_ 2565867774 FrApprtsOkTPmpIntrlk 6702;
BA_ "SPN" SG_ 2565867774 HdrlDshrgPrssrStPnt 6708;
BA_ "SPN" SG_ 2565867774 HdrlPrssrGvrnrDrsSwth 6704;
BA_ "SPN" SG_ 2565867774 HdrlPrssrGvrnrIdlSwth 6705;
BA_ "SPN" SG_ 2565867774 HdrlPrssrGvrnrInrsSwth 6703;
BA_ "SPN" SG_ 2565867774 HdrlPrssrGvrnrPrstSwth 6706;
BA_ "SPN" SG_ 2565867774 HydraulicIntakePressure 6707;
BA_ "SPN" SG_ 2565867774 HydraulicPressure 1762;
BA_ "SPN" SG_ 2565868030 LateralAcceleration 1809;
BA_ "SPN" SG_ 2565868030 LongitudinalAcceleration 1810;
BA_ "SPN" SG_ 2565868030 SteeringWheelAngle 1807;
BA_ "SPN" SG_ 2565868030 SteeringWheelAngleSensorType 1812;
BA_ "SPN" SG_ 2565868030 SteeringWheelTurnCounter 1811;
BA_ "SPN" SG_ 2565868030 YawRate 1808;
BA_ "SPN" SG_ 2565868542 ActualInnerwheelsteeringangle 2927;
BA_ "SPN" SG_ 2565868542 AxleLocation 2928;
BA_ "SPN" SG_ 2565868542 StatusofSteeringAxle 2923;
BA_ "SPN" SG_ 2565868542 SteeringType 2924;
BA_ "SPN" SG_ 2565868542 StrlLftAxlLwrngInht 2922;
BA_ "SPN" SG_ 2565868542 TypeofSteeringForces 2925;
BA_ "SPN" SG_ 2565868542 TypeofSteeringTransmission 2926;
BA_ "SPN" SG_ 2565869310 Aftrtrtmnt1IntkGsSnsr1HtrCntrl 3223;
BA_ "SPN" SG_ 2565869310 Aftrtrtmnt1IntkGsSnsr1tTmprtr 3219;
BA_ "SPN" SG_ 2565869310 Atttt1ItGsSs1HtPFMI 3222;
BA_ "SPN" SG_ 2565869310 Atttt1ItOxSs1PFMI 3225;
BA_ "SPN" SG_ 2565869310 Atttt1ItWdRPtOx1RdSt 3221;
BA_ "SPN" SG_ 2565869310 EngineExhaust1NOx1 3216;
BA_ "SPN" SG_ 2565869310 EngineExhaust1NOx1ReadingStable 3220;
BA_ "SPN" SG_ 2565869310 EngnExhst1NOxSnsr1PrlmnrFMI 3224;
BA_ "SPN" SG_ 2565869310 EngnExhst1NOxSnsr1SlfdgnssStts 5714;
BA_ "SPN" SG_ 2565869310 EngineExhaust1PercentOxygen1 3217;
BA_ "SPN" SG_ 2565869310 EngnExhst1GsSnsr1PwrInRng 3218;
BA_ "SPN" SG_ 2565869566 Aftertreatment1OutletNOx1 3226;
BA_ "SPN" SG_ 2565869566 Aftrtrtmnt1OtltGsSnsr1HtrCntrl 3233;
BA_ "SPN" SG_ 2565869566 Aftrtrtmnt1OtltGsSnsr1PwrInRng 3228;
BA_ "SPN" SG_ 2565869566 Aftrtrtmnt1OtltGsSnsr1tTmprtr 3229;
BA_ "SPN" SG_ 2565869566 Aftrtrtmnt1OtltNOx1RdngStl 3230;
BA_ "SPN" SG_ 2565869566 Aftrtrtmnt1OtltPrntOxgn1 3227;
BA_ "SPN" SG_ 2565869566 Atttt1OttGsSs1HtPFMI 3232;
BA_ "SPN" SG_ 2565869566 Atttt1OttNOxSs1PFMI 3234;
BA_ "SPN" SG_ 2565869566 Atttt1OttNOxSs1SdssStts 5713;
BA_ "SPN" SG_ 2565869566 Atttt1OttOxSs1PFMI 3235;
BA_ "SPN" SG_ 2565869566 Atttt1OttWdRPtOx1RdSt 3231;
BA_ "SPN" SG_ 2565869822 Aftrtrtmnt2IntkGsSnsr1HtrCntrl 3262;
BA_ "SPN" SG_ 2565869822 Aftrtrtmnt2IntkGsSnsr1tTmprtr 3258;
BA_ "SPN" SG_ 2565869822 Atttt2ItGsSs1HtPFMI 3261;
BA_ "SPN" SG_ 2565869822 Atttt2ItOxSs1PFMI 3264;
BA_ "SPN" SG_ 2565869822 Atttt2ItWdRPtOx1RdSt 3260;
BA_ "SPN" SG_ 2565869822 EngineExhaust2NOx1 3255;
BA_ "SPN" SG_ 2565869822 EngineExhaust2NOx1ReadingStable 3259;
BA_ "SPN" SG_ 2565869822 EngnExhst2NOxSnsr1PrlmnrFMI 3263;
BA_ "SPN" SG_ 2565869822 EngnExhst2NOxSnsr1SlfdgnssStts 5716;
BA_ "SPN" SG_ 2565869822 EngineExhaust2PercentOxygen1 3256;
BA_ "SPN" SG_ 2565869822 EngnExhst2GsSnsr1PwrInRng 3257;
BA_ "SPN" SG_ 2565869822 EngnExhst2GsSnsr2PwrSppl 8485;
BA_ "SPN" SG_ 2565870078 Aftertreatment2OutletNOx1 3265;
BA_ "SPN" SG_ 2565870078 Aftrtrtmnt2Otlt2GsSnsrPwrSppl 8486;
BA_ "SPN" SG_ 2565870078 Aftrtrtmnt2OtltGsSnsr1HtrCntrl 3272;
BA_ "SPN" SG_ 2565870078 Aftrtrtmnt2OtltGsSnsr1PwrInRng 3267;
BA_ "SPN" SG_ 2565870078 Aftrtrtmnt2OtltGsSnsr1tTmprtr 3268;
BA_ "SPN" SG_ 2565870078 Aftrtrtmnt2OtltNOx1RdngStl 3269;
BA_ "SPN" SG_ 2565870078 Aftrtrtmnt2OtltPrntOxgn1 3266;
BA_ "SPN" SG_ 2565870078 Atttt2OttGsSs1HtPFMI 3271;
BA_ "SPN" SG_ 2565870078 Atttt2OttNOxSs1PFMI 3273;
BA_ "SPN" SG_ 2565870078 Atttt2OttNOxSs1SdssStts 5715;
BA_ "SPN" SG_ 2565870078 Atttt2OttOxSs1PFMI 3274;
BA_ "SPN" SG_ 2565870078 Atttt2OttWdRPtOx1RdSt 3270;
BA_ "SPN" SG_ 2565870334 FifthWheelDrawbarForce 3309;
BA_ "SPN" SG_ 2565870334 FifthWheelRollMoment 3310;
BA_ "SPN" SG_ 2565870334 FifthWheelRollWarningIndicator 3317;
BA_ "SPN" SG_ 2565870334 FifthWheelVerticalForce 3308;
VAL_ 2561212158 TextDisplayInstructions 7 "1110Reserved" 6 "BlinkSubstring" 15 "NotApplicable" 1 "HldDsplyPrsntlyDsplydInfrmtnShl" 0 "ClrDsplyDsplydInfrmtnShldBDltdN" 5 "HighlightSubstring" 4 "OvrwrtSbstrngAPrtnOfPrsntlyDspl" 3 "OvrwrtDsplyPrsntlyDsplydInfrmtn" 2 "AppndAtEndOfDsplyTrnsmttdInfrmt" ;
VAL_ 2564882174 OperatorSeatDirectionSwitch 3 "NotAvailable" 2 "Error" 1 "OperatorSeatIsFacingForward" 0 "OperatorSeatNotFacingForward" ;
VAL_ 2564882174 SeatBeltSwitch 3 "NotAvailable" 2 "ErrrSwtchStteCannotBeDetermined" 1 "OKSeatBeltIsBuckled" 0 "NOTBuckled" ;
VAL_ 2565865982 ABSFullyOperational 3 "NotAvailable" 2 "Reserved" 1 "FullyOperational" 0 "NotFullyOperational" ;
VAL_ 2565865982 ABSOffroadSwitch 3 "NotAvailable" 2 "Error" 1 "ABSOffroadSwitchActive" 0 "ABSOffroadSwitchPassive" ;
VAL_ 2565865982 ASRHillHolderSwitch 3 "NotAvailable" 2 "Error" 1 "ASRHillHolderSwitchActive" 0 "ASRHillHolderSwitchPassive" ;
VAL_ 2565865982 ASROffroadSwitch 2 "Error" 1 "ASROffroadSwitchActive" 0 "ASROffroadSwitchPassive" 3 "NotAvailable" ;
VAL_ 2565865982 EBSBrakeSwitch 3 "NotAvailable" 2 "Error" 1 "BrakePedalIsBeingPressed" 0 "BrakePedalIsNotBeingPressed" ;
VAL_ 2565865982 EBSRedWarningSignal 3 "TakeNoAction" 2 "Reserved" 1 "On" 0 "Off" ;
VAL_ 2565865982 Haltbrakeswitch 3 "NotAvailable" 2 "Error" 1 "HaltBrakeSwitchActive" 0 "HaltBrakeSwitchPassive" ;
VAL_ 2565865982 TrailerABSStatus 3 "NotAvailableOrNotSupported" 2 "Reserved" 1 "TrailerABSActive" 0 "InformationAvailableButNotActive" ;
VAL_ 2565867262 Frontaxlegroupengagementstatus 3 "notAvailable" 2 "error" 1 "frontAxleGroupEngaged" 0 "frontAxleGroupDisengaged" ;
VAL_ 2565867262 Rearaxlegroupengagementstatus 3 "notAvailable" 2 "error" 1 "rearAxleGroupEngaged" 0 "rearAxleGroupDisengaged" ;
VAL_ 2565867774 FireApparatusPumpEngagement 3 "NotAvailableNotInstalled" 2 "Error" 1 "PumpEngaged" 0 "PumpNotEngaged" ;
VAL_ 2565870334 FifthWheelRollWarningIndicator 3 "NotAvailable" 2 "error" 1 "LimitExceeded" 0 "LimitNotExceeded" ;
VAL_ 2560032510 LwVltgDsnntDsrdOprtngMd 15 "NoChange" 6 "1110Reserved" 5 "ManualConnect" 4 "ManualDisconnect" 1 "0011Reserved" 0 "Automatic" ;
VAL_ 2560098046 CabNoiseControlStatus 3 "NotAvailable_NotRqed" 2 "ErrorIndicator" 1 "CabNoiseCtrlSystemOFFLine" 0 "CabNoiseCtrlSystemONLine" ;
VAL_ 2560098046 CabNoiseControlTuningStatus 15 "NotAvailable_NotTuning_NotRqed" 14 "TuningModeError" 10 "AutomaticTuningModeSavingData" 9 "AutomaticTuningModeCmdComplete" 8 "AutomaticTuningMode" 7 "MnlTnngDndRqrsScrtyVerification" 13 "Reserved" 2 "ManualTuningModeSavingData" 1 "ManualTuningModeCmdComplete" 0 "ManualTuningMode" ;
VAL_ 2560163582 CabNoiseControlCommand 3 "DontCare_NotCmded" 2 "Reserved" 1 "BringCabNoiseCtrlSystemOnLine" 0 "TakeCabNoiseCtrlSystemOffLine" ;
VAL_ 2560163582 CabNoiseControlTuningCommand 7 "DontCareNOTCmded" 6 "Reserved" 5 "ExitTuningSavingParameters" 4 "ExitTuningNotSavingParameters" 3 "RmnInTningSaveCurrentParameters" 2 "ActvtAtmtcTnngSttSvngPrmtrsExtO" 1 "ActvtAtmtcTnngWtFrSvAndExitCmds" 0 "ActvtMnlTnngWtFrSaveAndExitCmds" ;
VAL_ 2561015550 AuxiliaryIO84 3 "NtAvlblTkNoActionDependingOnApp" 2 "ErrrIndctrNotUsedDependingOnApp" 1 "AuxChannelOn" 0 "AuxChannelOff" ;
VAL_ 2561015550 AuxiliaryIO83 3 "NtAvlblTkNoActionDependingOnApp" 2 "ErrrIndctrNotUsedDependingOnApp" 1 "AuxChannelOn" 0 "AuxChannelOff" ;
VAL_ 2561015550 AuxiliaryIO82 3 "NtAvlblTkNoActionDependingOnApp" 2 "ErrrIndctrNotUsedDependingOnApp" 1 "AuxChannelOn" 0 "AuxChannelOff" ;
VAL_ 2561015550 AuxiliaryIO81 3 "NtAvlblTkNoActionDependingOnApp" 2 "ErrrIndctrNotUsedDependingOnApp" 1 "AuxChannelOn" 0 "AuxChannelOff" ;
VAL_ 2561015550 AuxiliaryIO88 3 "NtAvlblTkNoActionDependingOnApp" 2 "ErrrIndctrNotUsedDependingOnApp" 1 "AuxChannelOn" 0 "AuxChannelOff" ;
VAL_ 2561015550 AuxiliaryIO87 3 "NtAvlblTkNoActionDependingOnApp" 2 "ErrrIndctrNotUsedDependingOnApp" 1 "AuxChannelOn" 0 "AuxChannelOff" ;
VAL_ 2561015550 AuxiliaryIO86 3 "NtAvlblTkNoActionDependingOnApp" 2 "ErrrIndctrNotUsedDependingOnApp" 1 "AuxChannelOn" 0 "AuxChannelOff" ;
VAL_ 2561015550 AuxiliaryIO85 3 "NtAvlblTkNoActionDependingOnApp" 2 "ErrrIndctrNotUsedDependingOnApp" 1 "AuxChannelOn" 0 "AuxChannelOff" ;
VAL_ 2561015550 AuxiliaryIO92 3 "NtAvlblTkNoActionDependingOnApp" 2 "ErrrIndctrNotUsedDependingOnApp" 1 "AuxChannelOn" 0 "AuxChannelOff" ;
VAL_ 2561015550 AuxiliaryIO91 3 "NtAvlblTkNoActionDependingOnApp" 2 "ErrrIndctrNotUsedDependingOnApp" 1 "AuxChannelOn" 0 "AuxChannelOff" ;
VAL_ 2561015550 AuxiliaryIO90 3 "NtAvlblTkNoActionDependingOnApp" 2 "ErrrIndctrNotUsedDependingOnApp" 1 "AuxChannelOn" 0 "AuxChannelOff" ;
VAL_ 2561015550 AuxiliaryIO89 3 "NtAvlblTkNoActionDependingOnApp" 2 "ErrrIndctrNotUsedDependingOnApp" 1 "AuxChannelOn" 0 "AuxChannelOff" ;
VAL_ 2561015550 AuxiliaryIO96 3 "NtAvlblTkNoActionDependingOnApp" 2 "ErrrIndctrNotUsedDependingOnApp" 1 "AuxChannelOn" 0 "AuxChannelOff" ;
VAL_ 2561015550 AuxiliaryIO95 3 "NtAvlblTkNoActionDependingOnApp" 2 "ErrrIndctrNotUsedDependingOnApp" 1 "AuxChannelOn" 0 "AuxChannelOff" ;
VAL_ 2561015550 AuxiliaryIO94 3 "NtAvlblTkNoActionDependingOnApp" 2 "ErrrIndctrNotUsedDependingOnApp" 1 "AuxChannelOn" 0 "AuxChannelOff" ;
VAL_ 2561015550 AuxiliaryIO93 3 "NtAvlblTkNoActionDependingOnApp" 2 "ErrrIndctrNotUsedDependingOnApp" 1 "AuxChannelOn" 0 "AuxChannelOff" ;
VAL_ 2561015550 AuxiliaryIO100 3 "NtAvlblTkNoActionDependingOnApp" 2 "ErrrIndctrNotUsedDependingOnApp" 1 "AuxChannelOn" 0 "AuxChannelOff" ;
VAL_ 2561015550 AuxiliaryIO99 3 "NtAvlblTkNoActionDependingOnApp" 2 "ErrrIndctrNotUsedDependingOnApp" 1 "AuxChannelOn" 0 "AuxChannelOff" ;
VAL_ 2561015550 AuxiliaryIO98 3 "NtAvlblTkNoActionDependingOnApp" 2 "ErrrIndctrNotUsedDependingOnApp" 1 "AuxChannelOn" 0 "AuxChannelOff" ;
VAL_ 2561015550 AuxiliaryIO97 3 "NtAvlblTkNoActionDependingOnApp" 2 "ErrrIndctrNotUsedDependingOnApp" 1 "AuxChannelOn" 0 "AuxChannelOff" ;
VAL_ 2561015550 AuxiliaryIO104 3 "NtAvlblTkNoActionDependingOnApp" 2 "ErrrIndctrNotUsedDependingOnApp" 1 "AuxChannelOn" 0 "AuxChannelOff" ;
VAL_ 2561015550 AuxiliaryIO103 3 "NtAvlblTkNoActionDependingOnApp" 2 "ErrrIndctrNotUsedDependingOnApp" 1 "AuxChannelOn" 0 "AuxChannelOff" ;
VAL_ 2561015550 AuxiliaryIO102 3 "NtAvlblTkNoActionDependingOnApp" 2 "ErrrIndctrNotUsedDependingOnApp" 1 "AuxChannelOn" 0 "AuxChannelOff" ;
VAL_ 2561015550 AuxiliaryIO101 2 "ErrrIndctrNotUsedDependingOnApp" 1 "AuxChannelOn" 0 "AuxChannelOff" 3 "NtAvlblTkNoActionDependingOnApp" ;
VAL_ 2561015550 AuxiliaryIO108 3 "NtAvlblTkNoActionDependingOnApp" 2 "ErrrIndctrNotUsedDependingOnApp" 1 "AuxChannelOn" 0 "AuxChannelOff" ;
VAL_ 2561015550 AuxiliaryIO107 3 "NtAvlblTkNoActionDependingOnApp" 2 "ErrrIndctrNotUsedDependingOnApp" 1 "AuxChannelOn" 0 "AuxChannelOff" ;
VAL_ 2561015550 AuxiliaryIO106 3 "NtAvlblTkNoActionDependingOnApp" 2 "ErrrIndctrNotUsedDependingOnApp" 1 "AuxChannelOn" 0 "AuxChannelOff" ;
VAL_ 2561015550 AuxiliaryIO105 3 "NtAvlblTkNoActionDependingOnApp" 2 "ErrrIndctrNotUsedDependingOnApp" 1 "AuxChannelOn" 0 "AuxChannelOff" ;
VAL_ 2561015550 AuxiliaryIO112 3 "NtAvlblTkNoActionDependingOnApp" 2 "ErrrIndctrNotUsedDependingOnApp" 1 "AuxChannelOn" 0 "AuxChannelOff" ;
VAL_ 2561015550 AuxiliaryIO111 3 "NtAvlblTkNoActionDependingOnApp" 2 "ErrrIndctrNotUsedDependingOnApp" 1 "AuxChannelOn" 0 "AuxChannelOff" ;
VAL_ 2561015550 AuxiliaryIO110 3 "NtAvlblTkNoActionDependingOnApp" 2 "ErrrIndctrNotUsedDependingOnApp" 1 "AuxChannelOn" 0 "AuxChannelOff" ;
VAL_ 2561015550 AuxiliaryIO109 3 "NtAvlblTkNoActionDependingOnApp" 2 "ErrrIndctrNotUsedDependingOnApp" 1 "AuxChannelOn" 0 "AuxChannelOff" ;
VAL_ 2561081086 AuxiliaryIO52 3 "NtAvlblTkNoActionDependingOnApp" 2 "ErrrIndctrNotUsedDependingOnApp" 1 "AuxChannelOn" 0 "AuxChannelOff" ;
VAL_ 2561081086 AuxiliaryIO51 3 "NtAvlblTkNoActionDependingOnApp" 2 "ErrrIndctrNotUsedDependingOnApp" 1 "AuxChannelOn" 0 "AuxChannelOff" ;
VAL_ 2561081086 AuxiliaryIO50 3 "NtAvlblTkNoActionDependingOnApp" 2 "ErrrIndctrNotUsedDependingOnApp" 1 "AuxChannelOn" 0 "AuxChannelOff" ;
VAL_ 2561081086 AuxiliaryIO49 3 "NtAvlblTkNoActionDependingOnApp" 2 "ErrrIndctrNotUsedDependingOnApp" 1 "AuxChannelOn" 0 "AuxChannelOff" ;
VAL_ 2561081086 AuxiliaryIO56 3 "NtAvlblTkNoActionDependingOnApp" 2 "ErrrIndctrNotUsedDependingOnApp" 1 "AuxChannelOn" 0 "AuxChannelOff" ;
VAL_ 2561081086 AuxiliaryIO55 3 "NtAvlblTkNoActionDependingOnApp" 2 "ErrrIndctrNotUsedDependingOnApp" 1 "AuxChannelOn" 0 "AuxChannelOff" ;
VAL_ 2561081086 AuxiliaryIO54 3 "NtAvlblTkNoActionDependingOnApp" 2 "ErrrIndctrNotUsedDependingOnApp" 1 "AuxChannelOn" 0 "AuxChannelOff" ;
VAL_ 2561081086 AuxiliaryIO53 3 "NtAvlblTkNoActionDependingOnApp" 2 "ErrrIndctrNotUsedDependingOnApp" 1 "AuxChannelOn" 0 "AuxChannelOff" ;
VAL_ 2561081086 AuxiliaryIO60 3 "NtAvlblTkNoActionDependingOnApp" 2 "ErrrIndctrNotUsedDependingOnApp" 1 "AuxChannelOn" 0 "AuxChannelOff" ;
VAL_ 2561081086 AuxiliaryIO59 3 "NtAvlblTkNoActionDependingOnApp" 2 "ErrrIndctrNotUsedDependingOnApp" 1 "AuxChannelOn" 0 "AuxChannelOff" ;
VAL_ 2561081086 AuxiliaryIO58 3 "NtAvlblTkNoActionDependingOnApp" 2 "ErrrIndctrNotUsedDependingOnApp" 1 "AuxChannelOn" 0 "AuxChannelOff" ;
VAL_ 2561081086 AuxiliaryIO57 3 "NtAvlblTkNoActionDependingOnApp" 2 "ErrrIndctrNotUsedDependingOnApp" 1 "AuxChannelOn" 0 "AuxChannelOff" ;
VAL_ 2561081086 AuxiliaryIO64 3 "NtAvlblTkNoActionDependingOnApp" 2 "ErrrIndctrNotUsedDependingOnApp" 1 "AuxChannelOn" 0 "AuxChannelOff" ;
VAL_ 2561081086 AuxiliaryIO63 3 "NtAvlblTkNoActionDependingOnApp" 2 "ErrrIndctrNotUsedDependingOnApp" 1 "AuxChannelOn" 0 "AuxChannelOff" ;
VAL_ 2561081086 AuxiliaryIO62 3 "NtAvlblTkNoActionDependingOnApp" 2 "ErrrIndctrNotUsedDependingOnApp" 1 "AuxChannelOn" 0 "AuxChannelOff" ;
VAL_ 2561081086 AuxiliaryIO61 3 "NtAvlblTkNoActionDependingOnApp" 2 "ErrrIndctrNotUsedDependingOnApp" 1 "AuxChannelOn" 0 "AuxChannelOff" ;
VAL_ 2561081086 AuxiliaryIO68 3 "NtAvlblTkNoActionDependingOnApp" 2 "ErrrIndctrNotUsedDependingOnApp" 1 "AuxChannelOn" 0 "AuxChannelOff" ;
VAL_ 2561081086 AuxiliaryIO67 3 "NtAvlblTkNoActionDependingOnApp" 2 "ErrrIndctrNotUsedDependingOnApp" 1 "AuxChannelOn" 0 "AuxChannelOff" ;
VAL_ 2561081086 AuxiliaryIO66 3 "NtAvlblTkNoActionDependingOnApp" 2 "ErrrIndctrNotUsedDependingOnApp" 1 "AuxChannelOn" 0 "AuxChannelOff" ;
VAL_ 2561081086 AuxiliaryIO65 3 "NtAvlblTkNoActionDependingOnApp" 2 "ErrrIndctrNotUsedDependingOnApp" 1 "AuxChannelOn" 0 "AuxChannelOff" ;
VAL_ 2561081086 AuxiliaryIO72 3 "NtAvlblTkNoActionDependingOnApp" 2 "ErrrIndctrNotUsedDependingOnApp" 1 "AuxChannelOn" 0 "AuxChannelOff" ;
VAL_ 2561081086 AuxiliaryIO71 3 "NtAvlblTkNoActionDependingOnApp" 2 "ErrrIndctrNotUsedDependingOnApp" 1 "AuxChannelOn" 0 "AuxChannelOff" ;
VAL_ 2561081086 AuxiliaryIO70 3 "NtAvlblTkNoActionDependingOnApp" 2 "ErrrIndctrNotUsedDependingOnApp" 1 "AuxChannelOn" 0 "AuxChannelOff" ;
VAL_ 2561081086 AuxiliaryIO69 3 "NtAvlblTkNoActionDependingOnApp" 2 "ErrrIndctrNotUsedDependingOnApp" 1 "AuxChannelOn" 0 "AuxChannelOff" ;
VAL_ 2561081086 AuxiliaryIO76 3 "NtAvlblTkNoActionDependingOnApp" 2 "ErrrIndctrNotUsedDependingOnApp" 1 "AuxChannelOn" 0 "AuxChannelOff" ;
VAL_ 2561081086 AuxiliaryIO75 3 "NtAvlblTkNoActionDependingOnApp" 2 "ErrrIndctrNotUsedDependingOnApp" 1 "AuxChannelOn" 0 "AuxChannelOff" ;
VAL_ 2561081086 AuxiliaryIO74 3 "NtAvlblTkNoActionDependingOnApp" 2 "ErrrIndctrNotUsedDependingOnApp" 1 "AuxChannelOn" 0 "AuxChannelOff" ;
VAL_ 2561081086 AuxiliaryIO73 3 "NtAvlblTkNoActionDependingOnApp" 2 "ErrrIndctrNotUsedDependingOnApp" 1 "AuxChannelOn" 0 "AuxChannelOff" ;
VAL_ 2561081086 AuxiliaryIO80 3 "NtAvlblTkNoActionDependingOnApp" 2 "ErrrIndctrNotUsedDependingOnApp" 1 "AuxChannelOn" 0 "AuxChannelOff" ;
VAL_ 2561081086 AuxiliaryIO79 3 "NtAvlblTkNoActionDependingOnApp" 2 "ErrrIndctrNotUsedDependingOnApp" 1 "AuxChannelOn" 0 "AuxChannelOff" ;
VAL_ 2561081086 AuxiliaryIO78 3 "NtAvlblTkNoActionDependingOnApp" 2 "ErrrIndctrNotUsedDependingOnApp" 1 "AuxChannelOn" 0 "AuxChannelOff" ;
VAL_ 2561081086 AuxiliaryIO77 3 "NtAvlblTkNoActionDependingOnApp" 2 "ErrrIndctrNotUsedDependingOnApp" 1 "AuxChannelOn" 0 "AuxChannelOff" ;
VAL_ 2561146622 AuxiliaryIO20 3 "NtAvlblTkNoActionDependingOnApp" 2 "ErrrIndctrNotUsedDependingOnApp" 1 "AuxChannelOn" 0 "AuxChannelOff" ;
VAL_ 2561146622 AuxiliaryIO19 3 "NtAvlblTkNoActionDependingOnApp" 2 "ErrrIndctrNotUsedDependingOnApp" 1 "AuxChannelOn" 0 "AuxChannelOff" ;
VAL_ 2561146622 AuxiliaryIO18 3 "NtAvlblTkNoActionDependingOnApp" 2 "ErrrIndctrNotUsedDependingOnApp" 1 "AuxChannelOn" 0 "AuxChannelOff" ;
VAL_ 2561146622 AuxiliaryIO17 3 "NtAvlblTkNoActionDependingOnApp" 2 "ErrrIndctrNotUsedDependingOnApp" 1 "AuxChannelOn" 0 "AuxChannelOff" ;
VAL_ 2561146622 AuxiliaryIO24 3 "NtAvlblTkNoActionDependingOnApp" 2 "ErrrIndctrNotUsedDependingOnApp" 1 "AuxChannelOn" 0 "AuxChannelOff" ;
VAL_ 2561146622 AuxiliaryIO23 3 "NtAvlblTkNoActionDependingOnApp" 2 "ErrrIndctrNotUsedDependingOnApp" 1 "AuxChannelOn" 0 "AuxChannelOff" ;
VAL_ 2561146622 AuxiliaryIO22 3 "NtAvlblTkNoActionDependingOnApp" 2 "ErrrIndctrNotUsedDependingOnApp" 1 "AuxChannelOn" 0 "AuxChannelOff" ;
VAL_ 2561146622 AuxiliaryIO21 3 "NtAvlblTkNoActionDependingOnApp" 2 "ErrrIndctrNotUsedDependingOnApp" 1 "AuxChannelOn" 0 "AuxChannelOff" ;
VAL_ 2561146622 AuxiliaryIO28 3 "NtAvlblTkNoActionDependingOnApp" 2 "ErrrIndctrNotUsedDependingOnApp" 1 "AuxChannelOn" 0 "AuxChannelOff" ;
VAL_ 2561146622 AuxiliaryIO27 3 "NtAvlblTkNoActionDependingOnApp" 2 "ErrrIndctrNotUsedDependingOnApp" 1 "AuxChannelOn" 0 "AuxChannelOff" ;
VAL_ 2561146622 AuxiliaryIO26 3 "NtAvlblTkNoActionDependingOnApp" 2 "ErrrIndctrNotUsedDependingOnApp" 1 "AuxChannelOn" 0 "AuxChannelOff" ;
VAL_ 2561146622 AuxiliaryIO25 3 "NtAvlblTkNoActionDependingOnApp" 2 "ErrrIndctrNotUsedDependingOnApp" 1 "AuxChannelOn" 0 "AuxChannelOff" ;
VAL_ 2561146622 AuxiliaryIO32 3 "NtAvlblTkNoActionDependingOnApp" 2 "ErrrIndctrNotUsedDependingOnApp" 1 "AuxChannelOn" 0 "AuxChannelOff" ;
VAL_ 2561146622 AuxiliaryIO31 3 "NtAvlblTkNoActionDependingOnApp" 2 "ErrrIndctrNotUsedDependingOnApp" 1 "AuxChannelOn" 0 "AuxChannelOff" ;
VAL_ 2561146622 AuxiliaryIO30 3 "NtAvlblTkNoActionDependingOnApp" 2 "ErrrIndctrNotUsedDependingOnApp" 1 "AuxChannelOn" 0 "AuxChannelOff" ;
VAL_ 2561146622 AuxiliaryIO29 3 "NtAvlblTkNoActionDependingOnApp" 2 "ErrrIndctrNotUsedDependingOnApp" 1 "AuxChannelOn" 0 "AuxChannelOff" ;
VAL_ 2561146622 AuxiliaryIO36 3 "NtAvlblTkNoActionDependingOnApp" 2 "ErrrIndctrNotUsedDependingOnApp" 1 "AuxChannelOn" 0 "AuxChannelOff" ;
VAL_ 2561146622 AuxiliaryIO35 3 "NtAvlblTkNoActionDependingOnApp" 2 "ErrrIndctrNotUsedDependingOnApp" 1 "AuxChannelOn" 0 "AuxChannelOff" ;
VAL_ 2561146622 AuxiliaryIO34 3 "NtAvlblTkNoActionDependingOnApp" 2 "ErrrIndctrNotUsedDependingOnApp" 1 "AuxChannelOn" 0 "AuxChannelOff" ;
VAL_ 2561146622 AuxiliaryIO33 3 "NtAvlblTkNoActionDependingOnApp" 2 "ErrrIndctrNotUsedDependingOnApp" 1 "AuxChannelOn" 0 "AuxChannelOff" ;
VAL_ 2561146622 AuxiliaryIO40 3 "NtAvlblTkNoActionDependingOnApp" 2 "ErrrIndctrNotUsedDependingOnApp" 1 "AuxChannelOn" 0 "AuxChannelOff" ;
VAL_ 2561146622 AuxiliaryIO39 3 "NtAvlblTkNoActionDependingOnApp" 2 "ErrrIndctrNotUsedDependingOnApp" 1 "AuxChannelOn" 0 "AuxChannelOff" ;
VAL_ 2561146622 AuxiliaryIO38 3 "NtAvlblTkNoActionDependingOnApp" 2 "ErrrIndctrNotUsedDependingOnApp" 1 "AuxChannelOn" 0 "AuxChannelOff" ;
VAL_ 2561146622 AuxiliaryIO37 3 "NtAvlblTkNoActionDependingOnApp" 2 "ErrrIndctrNotUsedDependingOnApp" 1 "AuxChannelOn" 0 "AuxChannelOff" ;
VAL_ 2561146622 AuxiliaryIO44 3 "NtAvlblTkNoActionDependingOnApp" 2 "ErrrIndctrNotUsedDependingOnApp" 1 "AuxChannelOn" 0 "AuxChannelOff" ;
VAL_ 2561146622 AuxiliaryIO43 3 "NtAvlblTkNoActionDependingOnApp" 2 "ErrrIndctrNotUsedDependingOnApp" 1 "AuxChannelOn" 0 "AuxChannelOff" ;
VAL_ 2561146622 AuxiliaryIO42 3 "NtAvlblTkNoActionDependingOnApp" 2 "ErrrIndctrNotUsedDependingOnApp" 1 "AuxChannelOn" 0 "AuxChannelOff" ;
VAL_ 2561146622 AuxiliaryIO41 3 "NtAvlblTkNoActionDependingOnApp" 2 "ErrrIndctrNotUsedDependingOnApp" 1 "AuxChannelOn" 0 "AuxChannelOff" ;
VAL_ 2561146622 AuxiliaryIO48 3 "NtAvlblTkNoActionDependingOnApp" 2 "ErrrIndctrNotUsedDependingOnApp" 1 "AuxChannelOn" 0 "AuxChannelOff" ;
VAL_ 2561146622 AuxiliaryIO47 3 "NtAvlblTkNoActionDependingOnApp" 2 "ErrrIndctrNotUsedDependingOnApp" 1 "AuxChannelOn" 0 "AuxChannelOff" ;
VAL_ 2561146622 AuxiliaryIO46 3 "NtAvlblTkNoActionDependingOnApp" 2 "ErrrIndctrNotUsedDependingOnApp" 1 "AuxChannelOn" 0 "AuxChannelOff" ;
VAL_ 2561146622 AuxiliaryIO45 3 "NtAvlblTkNoActionDependingOnApp" 2 "ErrrIndctrNotUsedDependingOnApp" 1 "AuxChannelOn" 0 "AuxChannelOff" ;
VAL_ 2561277694 LnDprtrWrnngEnlCmmnd 3 "DonTCare" 2 "Reserved" 1 "EnableLaneDepartureWarning" 0 "DisableLaneDepartureWarning" ;
VAL_ 2564882174 AxlrHtrClntPmpRqst 3 "DontCare_TakeNoAction" 2 "Reserved" 1 "ActivateWaterPump" 0 "DeactivateWaterPump" ;
VAL_ 2564882174 BatteryMainSwitchHoldRequest 3 "DontCare_TakeNoAction" 2 "undefined" 1 "HoldBatteryMainSwitch" 0 "ReleaseBatteryMainSwitch" ;
VAL_ 2564882174 VhlLmtngSpdGvrnrDrmntSwth 3 "NotAvailable" 2 "Error" 1 "SwitchInOnStateDecrease" 0 "SwitchInOffState" ;
VAL_ 2564882174 VhlLmtngSpdGvrnrInrmntSwth 3 "NotAvailable" 2 "Error" 1 "SwitchInOnStateIncrease" 0 "SwitchInOffState" ;
VAL_ 2564882174 VhlLmtngSpdGvrnrEnlSwth 3 "NotAvailable" 2 "Error" 1 "SwitchedEnabled" 0 "SwitchDisabled" ;
VAL_ 2564882174 AftrtrtmntRgnrtnInhtSwth 3 "notAvailable" 2 "error" 1 "active" 0 "notActive" ;
VAL_ 2564882174 AftrtrtmntRgnrtnFrSwth 3 "notAvailable" 2 "error" 1 "active" 0 "notActive" ;
VAL_ 2564882174 AtmtGrShftngEnlSwth 3 "NotAvailable" 2 "Error" 1 "AutomatedGearShiftingIsEnabled" 0 "AutomatedGearShiftingIsDisabled" ;
VAL_ 2564882174 EngnAtmtStrtEnlSwth 3 "NotAvailable" 2 "Error" 1 "SwitchInOnState" 0 "SwitchInOffState" ;
VAL_ 2564882174 AuxiliaryHeaterModeRequest 15 "DontCare_TakeNoAction" 14 "Reserved" 4 "1101NotDefined" 3 "NormalMode" 2 "EconomyMode" 1 "OffDTADRPrErpnRgltnsFrTrnsprtOf" 0 "DeactivateAuxHeater" ;
VAL_ 2564882174 RequestEngineZoneHeating 3 "DontCare_TakeNoAction" 2 "Reserved" 1 "HeatEngZone" 0 "DoNotHeatEngZone" ;
VAL_ 2564882174 RequestCabZoneHeating 3 "DontCare_TakeNoAction" 2 "Reserved" 1 "HeatCabZone" 0 "DoNotCabEngZone" ;
VAL_ 2565865982 ASREngineControlActive 3 "NotAvailable" 2 "Reserved" 1 "ASREngCtrlActive" 0 "ASREngCtrlPassiveButInstalled" ;
VAL_ 2565865982 ASRBrakeControlActive 3 "NotAvailable" 2 "Reserved" 1 "ASRBrakeCtrlActive" 0 "ASRBrakeCtrlPassiveButInstalled" ;
VAL_ 2565865982 AntiLockBrakingABSActive 3 "NotAvailable" 2 "Reserved" 1 "ABSActive" 0 "ABSPassiveButInstalled" ;
VAL_ 2565865982 TractionControlOverrideSwitch 3 "NotAvailableNotInstalled" 2 "Error" 1 "On" 0 "Off" ;
VAL_ 2565865982 AcceleratorInterlockSwitch 3 "NotAvailable" 2 "Error" 1 "On" 0 "Off" ;
VAL_ 2565865982 EngineDerateSwitch 3 "NotAvailable" 2 "Error" 1 "On" 0 "Off" ;
VAL_ 2565865982 EngineAuxiliaryShutdownSwitch 3 "NotAvailable" 2 "Error" 1 "On" 0 "Off" ;
VAL_ 2565865982 RemoteAcceleratorEnableSwitch 3 "NotAvailable" 2 "Error" 1 "On" 0 "Off" ;
VAL_ 2565865982 ABSEBSAmrWrnngSgnlPwrdVhl 3 "TakeNoAction" 2 "Reserved" 1 "On" 0 "Off" ;
VAL_ 2565865982 ATCASRInformationSignal 3 "TakeNoAction" 2 "Reserved" 1 "On" 0 "Off" ;
VAL_ 2565865982 TrtrMntdTrlrABSWrnngSgnl 3 "TakeNoAction" 2 "Reserved" 1 "On" 0 "Off" ;
VAL_ 2565867262 DifferentialLockStateFrontAxle1 3 "NotAvailable" 2 "Error" 1 "DiffLockEngaged" 0 "DiffLockDisengaged" ;
VAL_ 2565867262 DifferentialLockStateFrontAxle2 3 "NotAvailable" 2 "Error" 1 "DiffLockEngaged" 0 "DiffLockDisengaged" ;
VAL_ 2565867262 DifferentialLockStateRearAxle1 3 "NotAvailable" 2 "Error" 1 "DiffLockEngaged" 0 "DiffLockDisengaged" ;
VAL_ 2565867262 DifferentialLockStateRearAxle2 3 "NotAvailable" 2 "Error" 1 "DiffLockEngaged" 0 "DiffLockDisengaged" ;
VAL_ 2565867262 DifferentialLockStateCentral 3 "NotAvailable" 2 "Error" 1 "DiffLockEngaged" 0 "DiffLockDisengaged" ;
VAL_ 2565867262 DffrntlLkSttCntrlFrnt 3 "NotAvailable" 2 "Error" 1 "DiffLockEngaged" 0 "DiffLockDisengaged" ;
VAL_ 2565867262 DffrntlLkSttCntrlRr 3 "NotAvailable" 2 "Error" 1 "DiffLockEngaged" 0 "DiffLockDisengaged" ;
VAL_ 2565867774 EngnHdrlPrssrGvrnrMdIndtr 3 "NotAvailable" 2 "ErrorIndicator" 1 "Enabled" 0 "Disabled" ;
VAL_ 2565867774 EngnHdrlPrssrGvrnrSwth 3 "NotAvailable" 2 "ErrorIndicator" 1 "PressModeActive" 0 "PressModeInactive" ;
VAL_ 2565868030 SteeringWheelAngleSensorType 3 "NotAvailable" 2 "Reserved" 1 "AbsMeasuringPrinciple" 0 "RelativeMeasuringPrinciple" ;
VAL_ 2565868542 StatusofSteeringAxle 15 "NotAvailable" 6 "1110ReservedForSAEAssignment" 5 "AxleSteerInSpecialMode" 4 "AxleNotActiveBecauseOfAnError" 3 "AxleCenteredBecauseOfAnError" 2 "AxleCentered" 1 "AxleSteerActive" 0 "AxleSteerNotActive" ;
VAL_ 2565868542 StrlLftAxlLwrngInht 3 "NotAvailable" 2 "Reserved" 1 "LoweringInhibited" 0 "LoweringAllowed" ;
VAL_ 2565868542 SteeringType 15 "NotAvailable" 2 "1110ReservedForAssignmentBySAE" 1 "AxStrEqpmntASystmInWhchWhlsOnAx" 0 "MnStrSystmStrngEqpmntOfAVhclWhc" ;
VAL_ 2565868542 TypeofSteeringForces 15 "NotAvailable" 4 "1110ReservedForSAEAssignment" 3 "SlfTrckngStrEqpmntASystmDsgndTC" 2 "FllPwrStrEqpmntStrngFrcsArPrvdd" 1 "PwrAssstdStrEqpmntStrngFrcsRslt" 0 "MnlStrEqpmntStrngFrcsRsltSllyFr" ;
VAL_ 2565868542 TypeofSteeringTransmission 15 "NotAvailable" 4 "1110ReservedForSAEAssignment" 3 "HybrdStrTrnsAStrngTrnsmssnInWhc" 2 "PrlyElctrcStrTrnsAStrngTrnsmssn" 1 "PrlyHydStrTrnsAStrngTrnsmssnInW" 0 "PrlyMchStrTrnsAStrngTrnsmssnInW" ;
VAL_ 2565869310 EngnExhst1GsSnsr1PwrInRng 3 "NotAvailable" 2 "Error" 1 "InRange" 0 "NotInRange" ;
VAL_ 2565869310 EngineExhaust1NOx1ReadingStable 3 "NotAvailable" 2 "Error" 1 "Stable" 0 "NotStable" ;
VAL_ 2565869310 Atttt1ItWdRPtOx1RdSt 3 "NotAvailable" 2 "Error" 1 "Stable" 0 "NotStable" ;
VAL_ 2565869310 Aftrtrtmnt1IntkGsSnsr1HtrCntrl 3 "HeaterOff" 2 "Preheat1" 1 "Preheat2" 0 "Automatic" ;
VAL_ 2565869566 Aftrtrtmnt1OtltGsSnsr1PwrInRng 3 "NotAvailable" 2 "Error" 1 "InRange" 0 "NotInRange" ;
VAL_ 2565869566 Aftrtrtmnt1OtltGsSnsr1tTmprtr 3 "NotAvailable" 2 "Error" 1 "InRange" 0 "NotInRange" ;
VAL_ 2565869566 Aftrtrtmnt1OtltNOx1RdngStl 3 "NotAvailable" 2 "Error" 1 "Stable" 0 "NotStable" ;
VAL_ 2565869566 Atttt1OttWdRPtOx1RdSt 3 "NotAvailable" 2 "Error" 1 "Stable" 0 "NotStable" ;
VAL_ 2565869566 Aftrtrtmnt1OtltGsSnsr1HtrCntrl 3 "HeaterOff" 2 "Preheat1" 1 "Preheat2" 0 "Automatic" ;
VAL_ 2565869822 EngnExhst2GsSnsr1PwrInRng 3 "NotAvailable" 2 "Error" 1 "InRange" 0 "NotInRange" ;
VAL_ 2565869822 Aftrtrtmnt2IntkGsSnsr1tTmprtr 3 "NotAvailable" 2 "Error" 1 "InRange" 0 "NotInRange" ;
VAL_ 2565869822 EngineExhaust2NOx1ReadingStable 3 "NotAvailable" 2 "Error" 1 "Stable" 0 "NotStable" ;
VAL_ 2565869822 Atttt2ItWdRPtOx1RdSt 3 "NotAvailable" 2 "Error" 1 "Stable" 0 "NotStable" ;
VAL_ 2565869822 Aftrtrtmnt2IntkGsSnsr1HtrCntrl 3 "HeaterOff" 2 "Preheat1" 1 "Preheat2" 0 "Automatic" ;
VAL_ 2565870078 Aftrtrtmnt2OtltGsSnsr1PwrInRng 3 "NotAvailable" 2 "Error" 1 "InRange" 0 "NotInRange" ;
VAL_ 2565870078 Aftrtrtmnt2OtltGsSnsr1tTmprtr 3 "NotAvailable" 2 "Error" 1 "InRange" 0 "NotInRange" ;
VAL_ 2565870078 Aftrtrtmnt2OtltNOx1RdngStl 3 "NotAvailable" 2 "Error" 1 "Stable" 0 "NotStable" ;
VAL_ 2565870078 Atttt2OttWdRPtOx1RdSt 3 "NotAvailable" 2 "Error" 1 "Stable" 0 "NotStable" ;
VAL_ 2565870078 Aftrtrtmnt2OtltGsSnsr1HtrCntrl 3 "HeaterOff" 2 "Preheat1" 1 "Preheat2" 0 "Automatic" ;
